VERSION ""

NS_ :

BS_:

BU_: HCM_FD IPMA_ADAS PSCM_FD ABS_ESC TCCM_FD TCM_DSL_FD PCM_HEV_FD PCM_FD ECM_Diesel GENERIC_GWMWakeup GWM_ECG _delete TSTR

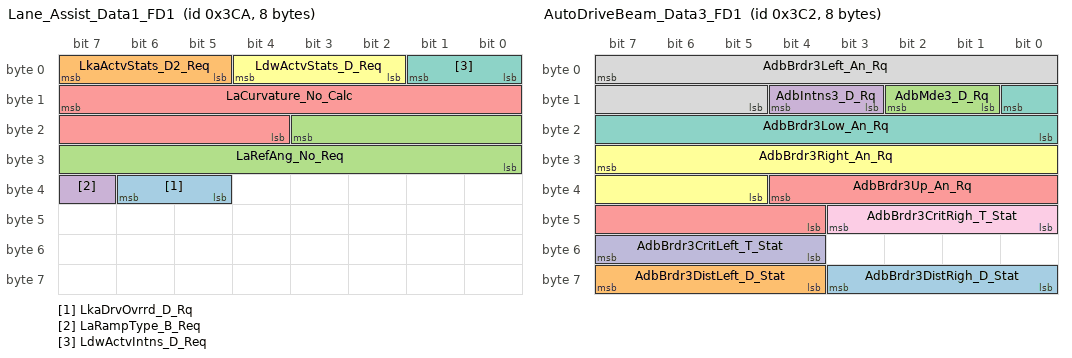
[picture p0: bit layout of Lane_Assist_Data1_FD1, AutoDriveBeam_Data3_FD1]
BO_ 970 Lane_Assist_Data1_FD1: 8 GWM_ECG
 SG_ LkaDrvOvrrd_D_Rq : 38|2@0+ (1,0) [0|3] "SED"  PSCM_FD
 SG_ LkaActvStats_D2_Req : 7|3@0+ (1,0) [0|7] "SED"  PSCM_FD
 SG_ LaRefAng_No_Req : 19|12@0+ (0.05,-102.4) [-102.4|102.3] "mrad"  PSCM_FD
 SG_ LaRampType_B_Req : 39|1@0+ (1,0) [0|1] "SED"  PSCM_FD
 SG_ LaCurvature_No_Calc : 15|12@0+ (5E-006,-0.01024) [-0.01024|0.01023] "1/m"  PSCM_FD
 SG_ LdwActvStats_D_Req : 4|3@0+ (1,0) [0|7] "SED"  PSCM_FD
 SG_ LdwActvIntns_D_Req : 1|2@0+ (1,0) [0|3] "SED"  PSCM_FD

BO_ 962 AutoDriveBeam_Data3_FD1: 8 IPMA_ADAS
 SG_ AdbBrdr3DistRigh_D_Stat : 59|4@0+ (1,0) [0|15] "SED"  HCM_FD
 SG_ AdbBrdr3DistLeft_D_Stat : 63|4@0+ (1,0) [0|15] "SED"  HCM_FD
 SG_ AdbMde3_D_Rq : 10|2@0+ (1,0) [0|3] "SED"  HCM_FD
 SG_ AdbIntns3_D_Rq : 12|2@0+ (1,0) [0|3] "SED"  HCM_FD
 SG_ AdbBrdr3Up_An_Rq : 36|9@0+ (0.02,-8) [-8|2.18] "degrees"  HCM_FD
 SG_ AdbBrdr3Right_An_Rq : 31|11@0+ (0.02,-20) [-20|20.9] "degrees"  HCM_FD
 SG_ AdbBrdr3Low_An_Rq : 8|9@0+ (0.02,-8) [-8|2.18] "degrees"  HCM_FD
 SG_ AdbBrdr3Left_An_Rq : 7|11@0+ (0.02,-20) [-20|20.9] "degrees"  HCM_FD
 SG_ AdbBrdr3CritRigh_T_Stat : 43|4@0+ (100,0) [0|1500] "millisecond"  HCM_FD
 SG_ AdbBrdr3CritLeft_T_Stat : 55|4@0+ (100,0) [0|1500] "millisecond"  HCM_FD

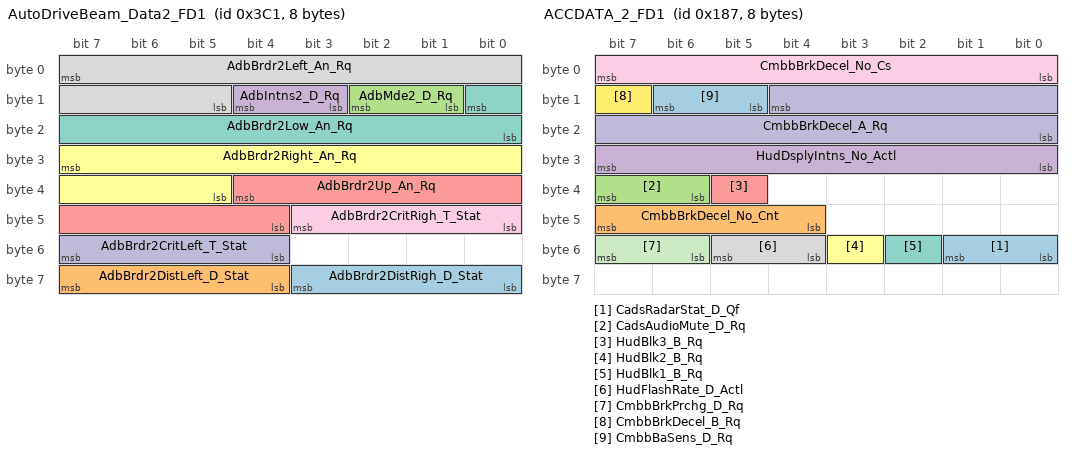
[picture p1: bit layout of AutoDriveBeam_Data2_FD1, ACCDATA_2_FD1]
BO_ 961 AutoDriveBeam_Data2_FD1: 8 IPMA_ADAS
 SG_ AdbBrdr2DistRigh_D_Stat : 59|4@0+ (1,0) [0|15] "SED"  HCM_FD
 SG_ AdbBrdr2DistLeft_D_Stat : 63|4@0+ (1,0) [0|15] "SED"  HCM_FD
 SG_ AdbMde2_D_Rq : 10|2@0+ (1,0) [0|3] "SED"  HCM_FD
 SG_ AdbIntns2_D_Rq : 12|2@0+ (1,0) [0|3] "SED"  HCM_FD
 SG_ AdbBrdr2Up_An_Rq : 36|9@0+ (0.02,-8) [-8|2.18] "degrees"  HCM_FD
 SG_ AdbBrdr2Right_An_Rq : 31|11@0+ (0.02,-20) [-20|20.9] "degrees"  HCM_FD
 SG_ AdbBrdr2Low_An_Rq : 8|9@0+ (0.02,-8) [-8|2.18] "degrees"  HCM_FD
 SG_ AdbBrdr2Left_An_Rq : 7|11@0+ (0.02,-20) [-20|20.9] "degrees"  HCM_FD
 SG_ AdbBrdr2CritRigh_T_Stat : 43|4@0+ (100,0) [0|1500] "millisecond"  HCM_FD
 SG_ AdbBrdr2CritLeft_T_Stat : 55|4@0+ (100,0) [0|1500] "millisecond"  HCM_FD

BO_ 394 ACCDATA_3_FD1: 8 IPMA_ADAS
 SG_ AccTrgDist2_D_Dsply : 27|4@0+ (1,0) [0|15] "SED" Vector__XXX
 SG_ AccStopRes_B_Dsply : 54|1@0+ (1,0) [0|1] "SED" Vector__XXX
 SG_ TjaWarn_D_Rq : 50|3@0+ (1,0) [0|7] "SED" Vector__XXX
 SG_ Tja_D_Stat : 44|3@0+ (1,0) [0|7] "SED" Vector__XXX
 SG_ TjaMsgTxt_D_Dsply : 53|3@0+ (1,0) [0|7] "SED" Vector__XXX
 SG_ IaccLamp_D_Rq : 46|2@0+ (1,0) [0|3] "SED" Vector__XXX
 SG_ AccMsgTxt_D2_Rq : 31|4@0+ (1,0) [0|15] "SED" Vector__XXX
 SG_ FcwDeny_B_Dsply : 10|1@0+ (1,0) [0|1] "SED" Vector__XXX
 SG_ FdaWarn_B_Rq : 21|1@0+ (1,0) [0|1] "SED" Vector__XXX
 SG_ FcwMemStat_B_Actl : 13|1@0+ (1,0) [0|1] "SED" Vector__XXX
 SG_ AccTGap_B_Dsply : 35|1@0+ (1,0) [0|1] "SED" Vector__XXX
 SG_ CadsAlignIncplt_B_Actl : 11|1@0+ (1,0) [0|1] "SED" Vector__XXX
 SG_ AccLowVMde_B_Dsply : 16|1@0+ (1,0) [0|1] "SED" Vector__XXX
 SG_ AccFllwMde_B_Dsply : 17|1@0+ (1,0) [0|1] "SED" Vector__XXX
 SG_ CadsRadrBlck_B_Actl : 22|1@0+ (1,0) [0|1] "SED" Vector__XXX
 SG_ FdaStat_D_Dsply : 3|3@0+ (1,0) [0|7] "SED" Vector__XXX
 SG_ FdaDeny_B_Dsply : 4|1@0+ (1,0) [0|1] "SED" Vector__XXX
 SG_ CadsChime_B_Rq : 55|1@0+ (1,0) [0|1] "SED" Vector__XXX
 SG_ CmbbPostEvnt_B_Dsply : 15|1@0+ (1,0) [0|1] "SED" Vector__XXX
 SG_ FcwCmbbSrvcRqd_B_Rq : 12|1@0+ (1,0) [0|1] "SED" Vector__XXX
 SG_ AccStopMde_B_Dsply : 0|1@0+ (1,0) [0|1] "SED" Vector__XXX
 SG_ CadsCamraBlck_B_Actl : 23|1@0+ (1,0) [0|1] "SED" Vector__XXX
 SG_ FcwMemSens_D_Actl : 20|2@0+ (1,0) [0|3] "SED" Vector__XXX
 SG_ FcwMemDfaltOn_B_Actl : 18|1@0+ (1,0) [0|1] "SED" Vector__XXX
 SG_ AccSrvcRqd_B_Rq : 14|1@0+ (1,0) [0|1] "SED" Vector__XXX
 SG_ FcwMsgTxt_D_Rq : 7|3@0+ (1,0) [0|7] "SED" Vector__XXX
 SG_ AccWarn_D_Dsply : 39|2@0+ (1,0) [0|3] "SED" Vector__XXX
 SG_ FcwVisblWarn_B_Rq : 47|1@0+ (1,0) [0|1] "SED" Vector__XXX
 SG_ FcwAudioWarn_B_Rq : 8|1@0+ (1,0) [0|1] "SED" Vector__XXX
 SG_ FcwMemAudioOn_B_Actl : 9|1@0+ (1,0) [0|1] "SED" Vector__XXX
 SG_ AccTGap_D_Dsply : 34|3@0+ (1,0) [0|7] "SED" Vector__XXX
 SG_ AccMemEnbl_B_RqDrv : 36|1@0+ (1,0) [0|1] "SED" Vector__XXX
 SG_ FdaMem_B_Stat : 37|1@0+ (1,0) [0|1] "SED" Vector__XXX

BO_ 391 ACCDATA_2_FD1: 8 GWM_ECG
 SG_ CadsRadarStat_D_Qf : 49|2@0+ (1,0) [0|3] "SED" Vector__XXX
 SG_ CmbbBrkDecel_No_Cnt : 47|4@0+ (1,0) [0|15] "Unitless"  ABS_ESC
 SG_ CadsAudioMute_D_Rq : 39|2@0+ (1,0) [0|3] "SED" Vector__XXX
 SG_ HudDsplyIntns_No_Actl : 31|8@0+ (0.5,0) [0|100] "%" Vector__XXX
 SG_ HudBlk3_B_Rq : 37|1@0+ (1,0) [0|1] "SED" Vector__XXX
 SG_ HudBlk2_B_Rq : 51|1@0+ (1,0) [0|1] "SED" Vector__XXX
 SG_ HudBlk1_B_Rq : 50|1@0+ (1,0) [0|1] "SED" Vector__XXX
 SG_ HudFlashRate_D_Actl : 53|2@0+ (1,0) [0|3] "SED" Vector__XXX
 SG_ CmbbBrkDecel_No_Cs : 7|8@0+ (1,0) [0|255] "Unitless"  ABS_ESC
 SG_ CmbbBrkDecel_A_Rq : 12|13@0+ (0.0039,-20) [-20|11.9449] "m/s^2"  ABS_ESC
 SG_ CmbbBrkPrchg_D_Rq : 55|2@0+ (1,0) [0|3] "SED"  ABS_ESC
 SG_ CmbbBrkDecel_B_Rq : 15|1@0+ (1,0) [0|1] "SED"  ABS_ESC
 SG_ CmbbBaSens_D_Rq : 14|2@0+ (1,0) [0|3] "SED"  ABS_ESC

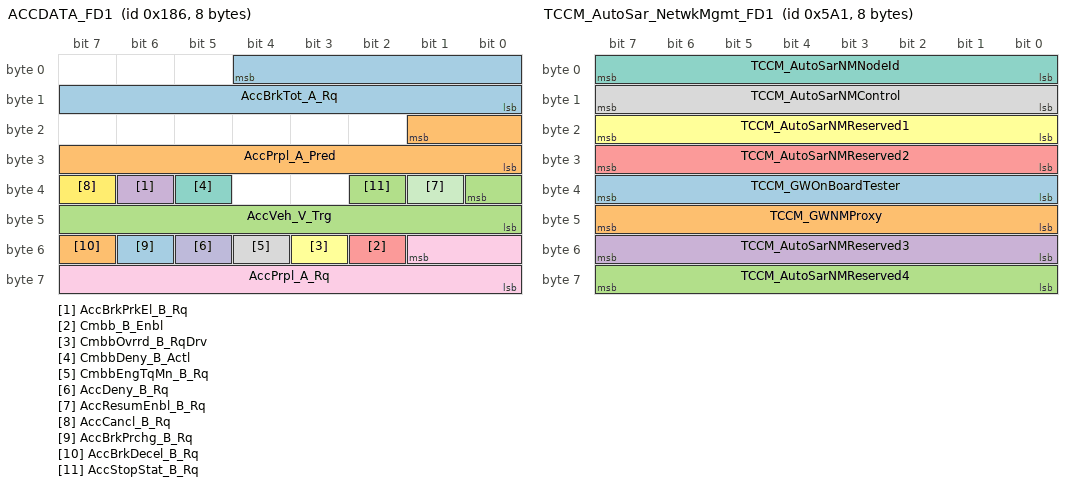
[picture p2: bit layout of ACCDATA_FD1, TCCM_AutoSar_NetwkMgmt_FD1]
BO_ 390 ACCDATA_FD1: 8 GWM_ECG
 SG_ AccBrkTot_A_Rq : 4|13@0+ (0.0039,-20) [-20|11.9449] "m/s^2"  ABS_ESC
 SG_ AccPrpl_A_Pred : 17|10@0+ (0.01,-5) [-5|5.23] "m/s^2"  ECM_Diesel,PCM_FD,PCM_HEV_FD
 SG_ AccVeh_V_Trg : 32|9@0+ (0.5,0) [0|255.5] "kph"  ECM_Diesel,PCM_FD,PCM_HEV_FD,TCM_DSL_FD
 SG_ AccBrkPrkEl_B_Rq : 38|1@0+ (1,0) [0|1] "SED"  ABS_ESC
 SG_ Cmbb_B_Enbl : 50|1@0+ (1,0) [0|1] "SED"  GWM_ECG
 SG_ CmbbOvrrd_B_RqDrv : 51|1@0+ (1,0) [0|1] "SED"  GWM_ECG
 SG_ CmbbDeny_B_Actl : 37|1@0+ (1,0) [0|1] "SED"  GWM_ECG,ABS_ESC
 SG_ CmbbEngTqMn_B_Rq : 52|1@0+ (1,0) [0|1] "SED"  ECM_Diesel,PCM_FD,PCM_HEV_FD,GWM_ECG
 SG_ AccPrpl_A_Rq : 49|10@0+ (0.01,-5) [-5|5.23] "m/s^2"  ECM_Diesel,PCM_FD,PCM_HEV_FD
 SG_ AccDeny_B_Rq : 53|1@0+ (1,0) [0|1] "SED"  ECM_Diesel,PCM_FD,PCM_HEV_FD
 SG_ AccResumEnbl_B_Rq : 33|1@0+ (1,0) [0|1] "SED"  ECM_Diesel,PCM_FD,PCM_HEV_FD
 SG_ AccCancl_B_Rq : 39|1@0+ (1,0) [0|1] "SED"  ABS_ESC,ECM_Diesel,PCM_FD,PCM_HEV_FD
 SG_ AccBrkPrchg_B_Rq : 54|1@0+ (1,0) [0|1] "SED"  ABS_ESC
 SG_ AccBrkDecel_B_Rq : 55|1@0+ (1,0) [0|1] "SED"  ABS_ESC
 SG_ AccStopStat_B_Rq : 34|1@0+ (1,0) [0|1] "SED"  ECM_Diesel,PCM_FD,PCM_HEV_FD,ABS_ESC

BO_ 1441 TCCM_AutoSar_NetwkMgmt_FD1: 8 TCCM_FD
 SG_ TCCM_GWOnBoardTester : 39|8@0+ (1,0) [0|255] "unitless"  GWM_ECG
 SG_ TCCM_GWNMProxy : 47|8@0+ (1,0) [0|255] "unitless"  GWM_ECG
 SG_ TCCM_AutoSarNMReserved4 : 63|8@0+ (1,0) [0|255] "unitless"  GWM_ECG
 SG_ TCCM_AutoSarNMReserved3 : 55|8@0+ (1,0) [0|255] "unitless"  GWM_ECG
 SG_ TCCM_AutoSarNMReserved2 : 31|8@0+ (1,0) [0|255] "unitless"  GWM_ECG
 SG_ TCCM_AutoSarNMReserved1 : 23|8@0+ (1,0) [0|255] "unitless"  GWM_ECG
 SG_ TCCM_AutoSarNMNodeId : 7|8@0+ (1,0) [0|255] "unitless"  GWM_ECG
 SG_ TCCM_AutoSarNMControl : 15|8@0+ (1,0) [0|255] "unitless"  GWM_ECG

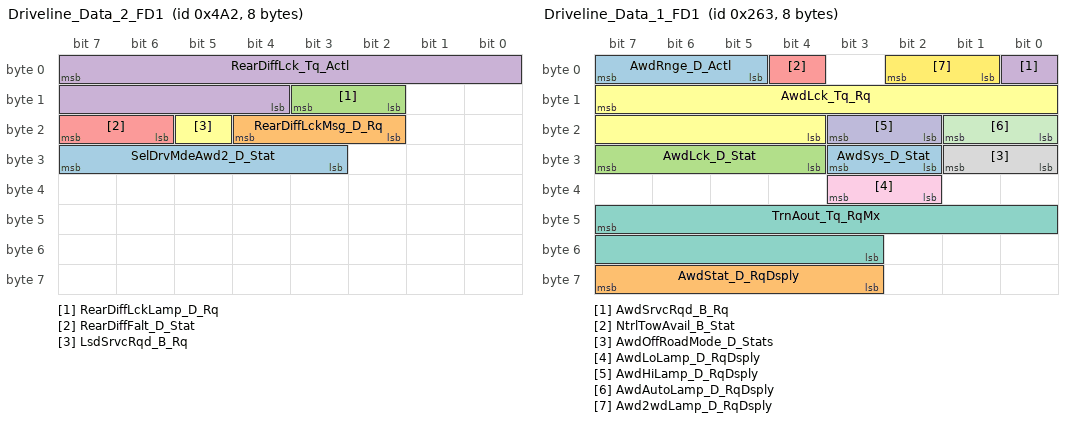
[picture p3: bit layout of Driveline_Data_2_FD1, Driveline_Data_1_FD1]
BO_ 1186 Driveline_Data_2_FD1: 8 TCCM_FD
 SG_ SelDrvMdeAwd2_D_Stat : 31|5@0+ (1,0) [0|31] "SED"  ABS_ESC,GWM_ECG
 SG_ RearDiffLckMsg_D_Rq : 20|3@0+ (1,0) [0|7] "SED"  GWM_ECG
 SG_ RearDiffLckLamp_D_Rq : 11|2@0+ (1,0) [0|3] "SED"  ABS_ESC,IPMA_ADAS,GWM_ECG
 SG_ RearDiffLck_Tq_Actl : 7|12@0+ (1,0) [0|4093] "Nm"  ABS_ESC,ECM_Diesel,PCM_FD,PCM_HEV_FD,GWM_ECG
 SG_ RearDiffFalt_D_Stat : 23|2@0+ (1,0) [0|3] "SED"  ABS_ESC,GWM_ECG
 SG_ LsdSrvcRqd_B_Rq : 21|1@0+ (1,0) [0|1] "SED"  GWM_ECG

BO_ 611 Driveline_Data_1_FD1: 8 TCCM_FD
 SG_ AwdSys_D_Stat : 27|2@0+ (1,0) [0|3] "SED"  GWM_ECG,ECM_Diesel,PCM_FD,PCM_HEV_FD
 SG_ AwdStat_D_RqDsply : 63|5@0+ (1,0) [0|31] "SED"  TCM_DSL_FD,ABS_ESC,GWM_ECG
 SG_ AwdLck_D_Stat : 31|4@0+ (1,0) [0|15] "SED"  GWM_ECG,ABS_ESC
 SG_ AwdSrvcRqd_B_Rq : 0|1@0+ (1,0) [0|1] "SED"  GWM_ECG,PCM_FD,PCM_HEV_FD,TCM_DSL_FD,ABS_ESC
 SG_ NtrlTowAvail_B_Stat : 4|1@0+ (1,0) [0|1] "SED"  GWM_ECG
 SG_ AwdLck_Tq_Rq : 15|12@0+ (1,0) [0|4093] "Nm"  ABS_ESC,GWM_ECG
 SG_ TrnAout_Tq_RqMx : 47|13@0+ (1,-1250) [-1250|6941] "Nm"  GWM_ECG,ECM_Diesel,PCM_FD,PCM_HEV_FD
 SG_ AwdOffRoadMode_D_Stats : 25|2@0+ (1,0) [0|3] "SED"  IPMA_ADAS,GWM_ECG
 SG_ AwdLoLamp_D_RqDsply : 35|2@0+ (1,0) [0|3] "SED"  GWM_ECG
 SG_ AwdHiLamp_D_RqDsply : 19|2@0+ (1,0) [0|3] "SED"  ABS_ESC,GWM_ECG
 SG_ AwdAutoLamp_D_RqDsply : 17|2@0+ (1,0) [0|3] "SED"  ABS_ESC,GWM_ECG
 SG_ Awd2wdLamp_D_RqDsply : 2|2@0+ (1,0) [0|3] "SED"  GWM_ECG
 SG_ AwdRnge_D_Actl : 7|3@0+ (1,0) [0|7] "SED"  GWM_ECG,ECM_Diesel,PCM_FD,PCM_HEV_FD,TCM_DSL_FD,ABS_ESC

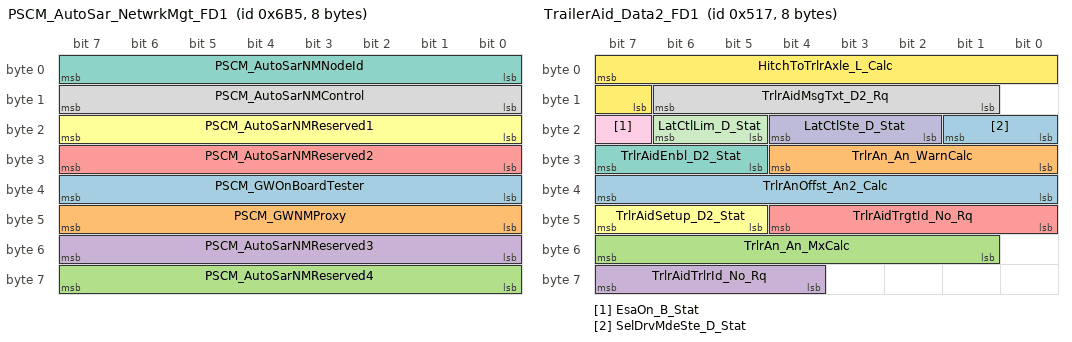
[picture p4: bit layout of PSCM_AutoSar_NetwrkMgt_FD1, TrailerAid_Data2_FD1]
BO_ 1717 PSCM_AutoSar_NetwrkMgt_FD1: 8 PSCM_FD
 SG_ PSCM_GWOnBoardTester : 39|8@0+ (1,0) [0|255] "unitless"  ABS_ESC
 SG_ PSCM_GWNMProxy : 47|8@0+ (1,0) [0|255] "unitless"  ABS_ESC
 SG_ PSCM_AutoSarNMReserved4 : 63|8@0+ (1,0) [0|255] "unitless"  ABS_ESC
 SG_ PSCM_AutoSarNMReserved3 : 55|8@0+ (1,0) [0|255] "unitless"  ABS_ESC
 SG_ PSCM_AutoSarNMReserved2 : 31|8@0+ (1,0) [0|255] "unitless"  ABS_ESC
 SG_ PSCM_AutoSarNMReserved1 : 23|8@0+ (1,0) [0|255] "unitless"  ABS_ESC
 SG_ PSCM_AutoSarNMNodeId : 7|8@0+ (1,0) [0|255] "unitless"  ABS_ESC
 SG_ PSCM_AutoSarNMControl : 15|8@0+ (1,0) [0|255] "unitless"  ABS_ESC

BO_ 1303 TrailerAid_Data2_FD1: 8 PSCM_FD
 SG_ TrlrAnOffst_An2_Calc : 39|8@0+ (0.5,-64) [-64|63.5] "degrees"  IPMA_ADAS
 SG_ TrlrAn_An_WarnCalc : 28|5@0+ (1,0) [0|31] "degrees"  IPMA_ADAS
 SG_ TrlrAn_An_MxCalc : 55|7@0+ (1,0) [0|127] "degrees"  IPMA_ADAS
 SG_ TrlrAidTrlrId_No_Rq : 63|4@0+ (1,0) [0|15] "unitless"  GWM_ECG
 SG_ TrlrAidTrgtId_No_Rq : 44|5@0+ (1,0) [0|31] "unitless"  IPMA_ADAS
 SG_ TrlrAidSetup_D2_Stat : 47|3@0+ (1,0) [0|7] "SED"  IPMA_ADAS
 SG_ TrlrAidEnbl_D2_Stat : 31|3@0+ (1,0) [0|7] "SED"  ECM_Diesel,IPMA_ADAS,GWM_ECG,PCM_FD
 SG_ TrlrAidMsgTxt_D2_Rq : 14|6@0+ (1,0) [0|63] "SED"  ABS_ESC,IPMA_ADAS,GWM_ECG
 SG_ EsaOn_B_Stat : 23|1@0+ (1,0) [0|1] "SED"  GWM_ECG
 SG_ LatCtlSte_D_Stat : 20|3@0+ (1,0) [0|7] "SED"  IPMA_ADAS
 SG_ LatCtlLim_D_Stat : 22|2@0+ (1,0) [0|3] "SED"  IPMA_ADAS
 SG_ HitchToTrlrAxle_L_Calc : 7|9@0+ (0.0254,0) [0|12.9794] "meter"  IPMA_ADAS
 SG_ SelDrvMdeSte_D_Stat : 17|2@0+ (1,0) [0|3] "SED"  ABS_ESC

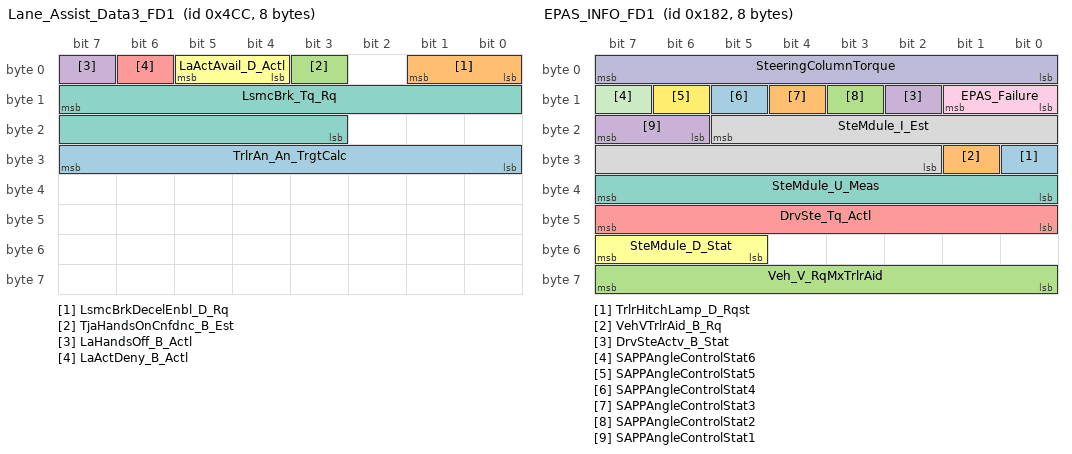
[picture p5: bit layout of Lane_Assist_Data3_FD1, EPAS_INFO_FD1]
BO_ 1228 Lane_Assist_Data3_FD1: 8 PSCM_FD
 SG_ TrlrAn_An_TrgtCalc : 31|8@0+ (1,-128) [-128|127] "degrees"  IPMA_ADAS
 SG_ LsmcBrkDecelEnbl_D_Rq : 1|2@0+ (1,0) [0|3] "SED"  ABS_ESC
 SG_ TjaHandsOnCnfdnc_B_Est : 3|1@0+ (1,0) [0|1] "SED"  IPMA_ADAS
 SG_ LaHandsOff_B_Actl : 7|1@0+ (1,0) [0|1] "SED"  IPMA_ADAS,GWM_ECG
 SG_ LaActDeny_B_Actl : 6|1@0+ (1,0) [0|1] "SED"  IPMA_ADAS,GWM_ECG
 SG_ LaActAvail_D_Actl : 5|2@0+ (1,0) [0|3] "SED"  IPMA_ADAS,GWM_ECG
 SG_ LsmcBrk_Tq_Rq : 15|13@0+ (4,0) [0|32764] "Nm"  ABS_ESC

BO_ 386 EPAS_INFO_FD1: 8 PSCM_FD
 SG_ TrlrHitchLamp_D_Rqst : 24|1@0+ (1,0) [0|1] "SED"  IPMA_ADAS,GWM_ECG
 SG_ VehVTrlrAid_B_Rq : 25|1@0+ (1,0) [0|1] "SED"  ECM_Diesel,PCM_FD
 SG_ Veh_V_RqMxTrlrAid : 63|8@0+ (0.1,0) [0|25.5] "km/h"  ECM_Diesel,PCM_FD
 SG_ DrvSteActv_B_Stat : 10|1@0+ (1,0) [0|1] "SED"  ABS_ESC
 SG_ DrvSte_Tq_Actl : 47|8@0+ (0.0625,-8) [-8|7.8125] "Nm"  ABS_ESC
 SG_ SteMdule_D_Stat : 55|3@0+ (1,0) [0|7] "SED"  GWM_ECG
 SG_ SteMdule_U_Meas : 39|8@0+ (0.05,6) [6|18.7] "Volts"  GWM_ECG
 SG_ SteMdule_I_Est : 21|12@0+ (0.05,-64) [-64|140.7] "Amps"  GWM_ECG
 SG_ EPAS_Failure : 9|2@0+ (1,0) [0|3] "SED"  IPMA_ADAS,GWM_ECG
 SG_ SteeringColumnTorque : 7|8@0+ (0.0625,-8) [-8|7.8125] "Nm"  ABS_ESC,IPMA_ADAS
 SG_ SAPPAngleControlStat6 : 15|1@0+ (1,0) [0|1] "SED"  IPMA_ADAS
 SG_ SAPPAngleControlStat5 : 14|1@0+ (1,0) [0|1] "SED"  IPMA_ADAS
 SG_ SAPPAngleControlStat4 : 13|1@0+ (1,0) [0|1] "SED"  IPMA_ADAS
 SG_ SAPPAngleControlStat3 : 12|1@0+ (1,0) [0|1] "SED"  IPMA_ADAS
 SG_ SAPPAngleControlStat2 : 11|1@0+ (1,0) [0|1] "SED"  IPMA_ADAS
 SG_ SAPPAngleControlStat1 : 23|2@0+ (1,0) [0|3] "SED"  IPMA_ADAS

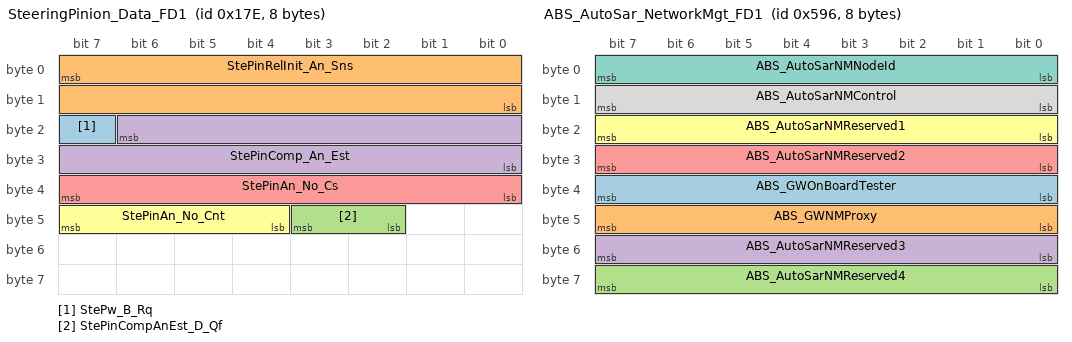
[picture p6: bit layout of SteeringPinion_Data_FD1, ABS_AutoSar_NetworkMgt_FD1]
BO_ 382 SteeringPinion_Data_FD1: 8 PSCM_FD
 SG_ StePw_B_Rq : 23|1@0+ (1,0) [0|1] "SED"  GWM_ECG,ECM_Diesel,PCM_FD
 SG_ StePinRelInit_An_Sns : 7|16@0+ (0.1,-3200) [-3200|3353.3] "degrees"  IPMA_ADAS,GWM_ECG,ECM_Diesel,PCM_FD,PCM_HEV_FD,ABS_ESC,TCCM_FD
 SG_ StePinCompAnEst_D_Qf : 43|2@0+ (1,0) [0|3] "SED"  HCM_FD,IPMA_ADAS,TCM_DSL_FD,GWM_ECG,ECM_Diesel,PCM_FD,PCM_HEV_FD,ABS_ESC,TCCM_FD
 SG_ StePinComp_An_Est : 22|15@0+ (0.1,-1600) [-1600|1676.7] "degrees"  HCM_FD,IPMA_ADAS,TCM_DSL_FD,GWM_ECG,ECM_Diesel,PCM_FD,PCM_HEV_FD,ABS_ESC,TCCM_FD
 SG_ StePinAn_No_Cs : 39|8@0+ (1,0) [0|255] "Unitless"  ABS_ESC,TCCM_FD,GWM_ECG
 SG_ StePinAn_No_Cnt : 47|4@0+ (1,0) [0|15] "unitless"  TCCM_FD,GWM_ECG,ABS_ESC

BO_ 1430 ABS_AutoSar_NetworkMgt_FD1: 8 ABS_ESC
 SG_ ABS_GWOnBoardTester : 39|8@0+ (1,0) [0|255] "unitless"  GWM_ECG
 SG_ ABS_GWNMProxy : 47|8@0+ (1,0) [0|255] "unitless"  GWM_ECG
 SG_ ABS_AutoSarNMReserved4 : 63|8@0+ (1,0) [0|255] "unitless"  GWM_ECG
 SG_ ABS_AutoSarNMReserved3 : 55|8@0+ (1,0) [0|255] "unitless"  GWM_ECG
 SG_ ABS_AutoSarNMReserved2 : 31|8@0+ (1,0) [0|255] "unitless"  GWM_ECG
 SG_ ABS_AutoSarNMReserved1 : 23|8@0+ (1,0) [0|255] "unitless"  GWM_ECG
 SG_ ABS_AutoSarNMNodeId : 7|8@0+ (1,0) [0|255] "unitless"  GWM_ECG
 SG_ ABS_AutoSarNMControl : 15|8@0+ (1,0) [0|255] "unitless"  GWM_ECG

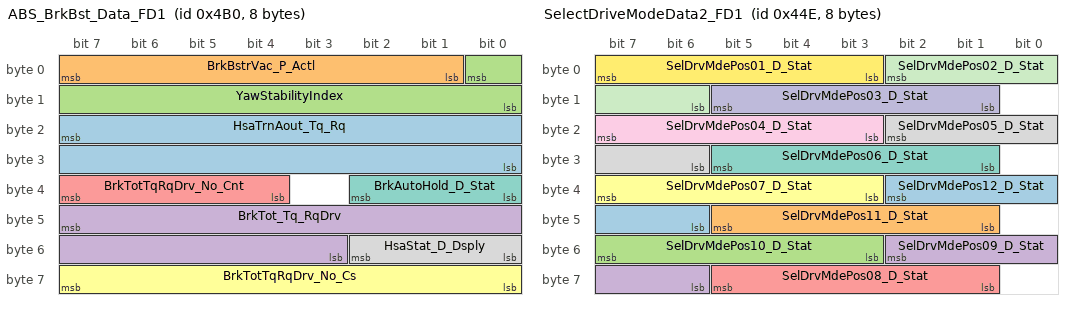
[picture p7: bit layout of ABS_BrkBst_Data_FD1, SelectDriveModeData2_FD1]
BO_ 1200 ABS_BrkBst_Data_FD1: 8 ABS_ESC
 SG_ HsaTrnAout_Tq_Rq : 23|16@0+ (4,-131072) [-131072|131060] "Nm"  GWM_ECG
 SG_ BrkBstrVac_P_Actl : 7|7@0+ (8,0) [0|1008] "Millibar"  ECM_Diesel,PCM_FD,PCM_HEV_FD,GWM_ECG
 SG_ YawStabilityIndex : 0|9@0+ (1,-256) [-256|255] "%"  IPMA_ADAS,PSCM_FD,GWM_ECG
 SG_ BrkTot_Tq_RqDrv : 47|13@0+ (4,0) [0|32760] "Nm"  IPMA_ADAS,ECM_Diesel,PCM_FD,PCM_HEV_FD,GWM_ECG
 SG_ BrkTotTqRqDrv_No_Cnt : 39|4@0+ (1,0) [0|15] "unitless"  ECM_Diesel,PCM_FD,PCM_HEV_FD,GWM_ECG
 SG_ BrkTotTqRqDrv_No_Cs : 63|8@0+ (1,0) [0|255] "unitless"  ECM_Diesel,PCM_FD,PCM_HEV_FD,GWM_ECG
 SG_ BrkAutoHold_D_Stat : 34|3@0+ (1,0) [0|7] "SED"  ECM_Diesel,PCM_FD,PCM_HEV_FD,GWM_ECG,IPMA_ADAS
 SG_ HsaStat_D_Dsply : 50|3@0+ (1,0) [0|7] "SED"  GWM_ECG

BO_ 1102 SelectDriveModeData2_FD1: 8 ABS_ESC
 SG_ SelDrvMdePos12_D_Stat : 34|5@0+ (1,0) [0|31] "SED"  GWM_ECG
 SG_ SelDrvMdePos11_D_Stat : 45|5@0+ (1,0) [0|31] "SED"  GWM_ECG
 SG_ SelDrvMdePos10_D_Stat : 55|5@0+ (1,0) [0|31] "SED"  GWM_ECG
 SG_ SelDrvMdePos09_D_Stat : 50|5@0+ (1,0) [0|31] "SED"  GWM_ECG
 SG_ SelDrvMdePos08_D_Stat : 61|5@0+ (1,0) [0|31] "SED"  GWM_ECG
 SG_ SelDrvMdePos07_D_Stat : 39|5@0+ (1,0) [0|31] "SED"  GWM_ECG
 SG_ SelDrvMdePos06_D_Stat : 29|5@0+ (1,0) [0|31] "SED"  GWM_ECG
 SG_ SelDrvMdePos05_D_Stat : 18|5@0+ (1,0) [0|31] "SED"  GWM_ECG
 SG_ SelDrvMdePos04_D_Stat : 23|5@0+ (1,0) [0|31] "SED"  GWM_ECG
 SG_ SelDrvMdePos03_D_Stat : 13|5@0+ (1,0) [0|31] "SED"  GWM_ECG
 SG_ SelDrvMdePos02_D_Stat : 2|5@0+ (1,0) [0|31] "SED"  GWM_ECG
 SG_ SelDrvMdePos01_D_Stat : 7|5@0+ (1,0) [0|31] "SED"  GWM_ECG

BO_ 1056 SelectDriveModeData_FD1: 8 ABS_ESC
 SG_ SelDrvMdePos12_B_Avail : 54|1@0+ (1,0) [0|1] "SED"  GWM_ECG
 SG_ SelDrvMdePos11_B_Avail : 55|1@0+ (1,0) [0|1] "SED"  GWM_ECG
 SG_ SelDrvMdePos10_B_Avail : 40|1@0+ (1,0) [0|1] "SED"  GWM_ECG
 SG_ SelDrvMdePos09_B_Avail : 41|1@0+ (1,0) [0|1] "SED"  GWM_ECG
 SG_ SelDrvMdePos08_B_Avail : 42|1@0+ (1,0) [0|1] "SED"  GWM_ECG
 SG_ SelDrvMdePos07_B_Avail : 43|1@0+ (1,0) [0|1] "SED"  GWM_ECG
 SG_ SelDrvMdePos06_B_Avail : 44|1@0+ (1,0) [0|1] "SED"  GWM_ECG
 SG_ SelDrvMdePos05_B_Avail : 45|1@0+ (1,0) [0|1] "SED"  GWM_ECG
 SG_ SelDrvMdePos04_B_Avail : 46|1@0+ (1,0) [0|1] "SED"  GWM_ECG
 SG_ SelDrvMdePos03_B_Avail : 47|1@0+ (1,0) [0|1] "SED"  GWM_ECG
 SG_ SelDrvMdePos02_B_Avail : 32|1@0+ (1,0) [0|1] "SED"  GWM_ECG
 SG_ SelDrvMdePos01_B_Avail : 24|1@0+ (1,0) [0|1] "SED"  GWM_ECG
 SG_ ActvDrvMde_D2_Stat : 53|5@0+ (1,0) [0|31] "SED"  IPMA_ADAS,GWM_ECG
 SG_ SelDrvMde_D2_Rq : 63|5@0+ (1,0) [0|31] "SED"  GWM_ECG
 SG_ SelDrvMdePt_D_Rq : 31|5@0+ (1,0) [0|31] "SED"  ECM_Diesel,PCM_FD,PCM_HEV_FD,GWM_ECG
 SG_ SelDrvMdeMsgTxt_D_Rq : 19|4@0+ (1,0) [0|0] "SED"  GWM_ECG
 SG_ SelDrvMde_D_Stat : 26|2@0+ (1,0) [0|3] "SED"  GWM_ECG
 SG_ AwdMde_D_RqBrk : 35|3@0+ (1,0) [0|7] "SED"  GWM_ECG

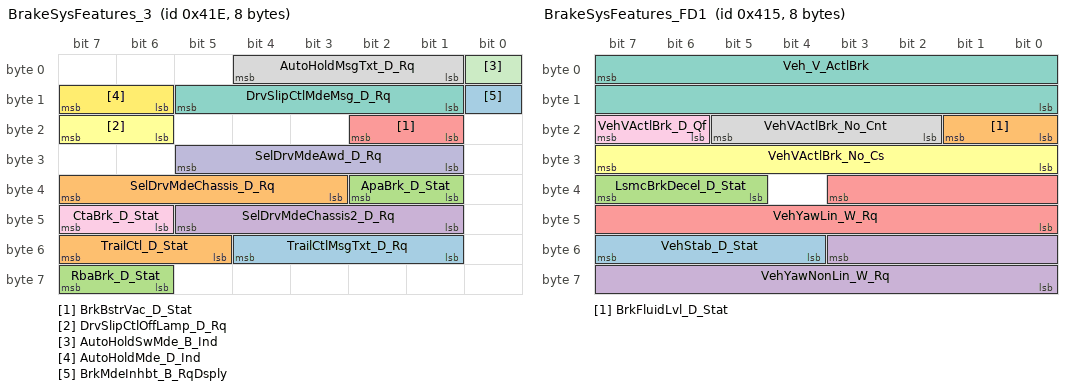
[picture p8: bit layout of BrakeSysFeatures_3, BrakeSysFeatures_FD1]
BO_ 1054 BrakeSysFeatures_3: 8 ABS_ESC
 SG_ TrailCtlMsgTxt_D_Rq : 52|4@0+ (1,0) [0|15] "SED"  GWM_ECG
 SG_ TrailCtl_D_Stat : 55|3@0+ (1,0) [0|7] "SED"  PCM_FD,GWM_ECG,TCCM_FD
 SG_ RbaBrk_D_Stat : 63|2@0+ (1,0) [0|3] "SED"  IPMA_ADAS,GWM_ECG
 SG_ SelDrvMdeChassis2_D_Rq : 45|5@0+ (1,0) [0|31] "SED"  PSCM_FD,GWM_ECG
 SG_ BrkBstrVac_D_Stat : 18|2@0+ (1,0) [0|3] "SED"  ECM_Diesel,PCM_FD,PCM_HEV_FD,GWM_ECG
 SG_ DrvSlipCtlOffLamp_D_Rq : 23|2@0+ (1,0) [0|3] "SED"  GWM_ECG
 SG_ DrvSlipCtlMdeMsg_D_Rq : 13|5@0+ (1,0) [0|31] "SED"  GWM_ECG
 SG_ AutoHoldMsgTxt_D_Rq : 4|4@0+ (1,0) [0|15] "SED"  GWM_ECG
 SG_ CtaBrk_D_Stat : 47|2@0+ (1,0) [0|3] "SED"  GWM_ECG
 SG_ SelDrvMdeAwd_D_Rq : 29|5@0+ (1,0) [0|31] "SED"  TCCM_FD,GWM_ECG
 SG_ AutoHoldSwMde_B_Ind : 0|1@0+ (1,0) [0|1] "SED"  GWM_ECG
 SG_ AutoHoldMde_D_Ind : 15|2@0+ (1,0) [0|3] "SED"  GWM_ECG
 SG_ BrkMdeInhbt_B_RqDsply : 8|1@0+ (1,0) [0|1] "SED"  GWM_ECG
 SG_ SelDrvMdeChassis_D_Rq : 39|5@0+ (1,0) [0|31] "SED"  GWM_ECG
 SG_ ApaBrk_D_Stat : 34|2@0+ (1,0) [0|3] "SED"  ECM_Diesel,IPMA_ADAS,PCM_FD,PCM_HEV_FD,GWM_ECG

BO_ 1046 BrakeSysFeatures_2: 8 ABS_ESC
 SG_ RearDiffElckrOpen_B_Rq : 40|1@0+ (1,0) [0|1] "SE"  GWM_ECG,TCCM_FD
 SG_ HsaMde_D_Mem : 33|2@0+ (1,0) [0|3] "SED"  GWM_ECG
 SG_ BrkBstrVac_B_Rq : 27|1@0+ (1,0) [0|1] "Discrete"  ECM_Diesel,PCM_FD,PCM_HEV_FD,GWM_ECG
 SG_ HdcMde_D_Actl : 31|3@0+ (1,0) [0|7] "SED"  GWM_ECG
 SG_ RearDiffLck_Tq2_RqMx : 51|12@0+ (4,0) [0|16376] "Nm"  GWM_ECG
 SG_ TRLR_SWAY_EVNT_IN_PROG : 25|1@0+ (1,0) [0|1] "SED"  GWM_ECG
 SG_ TRLR_SWAY_CONFIG_STAT : 26|1@0+ (1,0) [0|1] "SED"  GWM_ECG
 SG_ TCMode : 15|1@0+ (1,0) [0|1] "SED"  IPMA_ADAS,ECM_Diesel,PCM_FD,PCM_HEV_FD,GWM_ECG
 SG_ DrvSlipCtlLamp_D_Rq : 42|2@0+ (1,0) [0|3] "SED"  IPMA_ADAS,ECM_Diesel,PCM_FD,PCM_HEV_FD,GWM_ECG
 SG_ Abs_B_Falt : 5|1@0+ (1,0) [0|1] "SED"  ECM_Diesel,PCM_FD,PCM_HEV_FD,GWM_ECG
 SG_ DrvSlipCtlMde_D_Ind : 44|2@0+ (1,0) [0|3] "SED"  TCCM_FD,IPMA_ADAS,ECM_Diesel,PCM_FD,PCM_HEV_FD,GWM_ECG
 SG_ BpedMove_No_Cs : 23|8@0+ (1,0) [0|255] "Unitless"  ECM_Diesel,GWM_ECG
 SG_ DrvAntiLckLamp_D_Rq : 55|2@0+ (1,0) [0|3] "SED"  ECM_Diesel,GWM_ECG
 SG_ BpedMove_No_Cnt : 3|4@0+ (1,0) [0|15] "Unitless"  ECM_Diesel,GWM_ECG
 SG_ StabCtlBrk_B_Avail : 4|1@0+ (1,0) [0|1] "SED"  GWM_ECG
 SG_ DrvHdcWarnInfo_D_Rq : 35|2@0+ (1,0) [0|3] "SED"  GWM_ECG
 SG_ DrvHdcMsg_D_Rq : 10|3@0+ (1,0) [0|7] "SED"  GWM_ECG
 SG_ DrvHdcLampInfo_D_Rq : 12|2@0+ (1,0) [0|3] "SED"  GWM_ECG
 SG_ BpedMove_D_Actl : 7|2@0+ (1,0) [0|3] "SED"  ECM_Diesel,GWM_ECG
 SG_ ChimeBrk_B_Rq : 14|1@0+ (1,0) [0|1] "SED"  GWM_ECG
 SG_ BrkLamp_B_Rq : 13|1@0+ (1,0) [0|1] "SED"  GWM_ECG
 SG_ HILL_DESC_MC : 47|3@0+ (1,0) [0|7] "SED"  GWM_ECG

BO_ 1045 BrakeSysFeatures_FD1: 8 ABS_ESC
 SG_ VehStab_D_Stat : 55|4@0+ (1,0) [0|15] "SED"  PCM_FD,PCM_HEV_FD,GWM_ECG
 SG_ BrkFluidLvl_D_Stat : 17|2@0+ (1,0) [0|3] "SED"  GWM_ECG
 SG_ LsmcBrkDecel_D_Stat : 39|3@0+ (1,0) [0|7] "SED"  PSCM_FD,GWM_ECG
 SG_ VehYawNonLin_W_Rq : 51|12@0+ (0.03663,-75) [-75|74.92659] "deg/s"  ECM_Diesel,GWM_ECG
 SG_ VehYawLin_W_Rq : 35|12@0+ (0.03663,-75) [-75|74.92659] "deg/s"  ECM_Diesel,GWM_ECG
 SG_ VehVActlBrk_No_Cs : 31|8@0+ (1,0) [0|255] "Unitless"  PCM_FD,ECM_Diesel,PCM_HEV_FD,PSCM_FD,TCM_DSL_FD,GWM_ECG
 SG_ Veh_V_ActlBrk : 7|16@0+ (0.01,0) [0|655.35] "kph"  PCM_FD,IPMA_ADAS,ECM_Diesel,PCM_HEV_FD,PSCM_FD,TCM_DSL_FD,GWM_ECG
 SG_ VehVActlBrk_No_Cnt : 21|4@0+ (1,0) [0|15] "Unitless"  PCM_FD,ECM_Diesel,PCM_HEV_FD,PSCM_FD,TCM_DSL_FD,GWM_ECG
 SG_ VehVActlBrk_D_Qf : 23|2@0+ (1,0) [0|3] "SED"  PCM_FD,IPMA_ADAS,ECM_Diesel,PCM_HEV_FD,PSCM_FD,TCM_DSL_FD,GWM_ECG

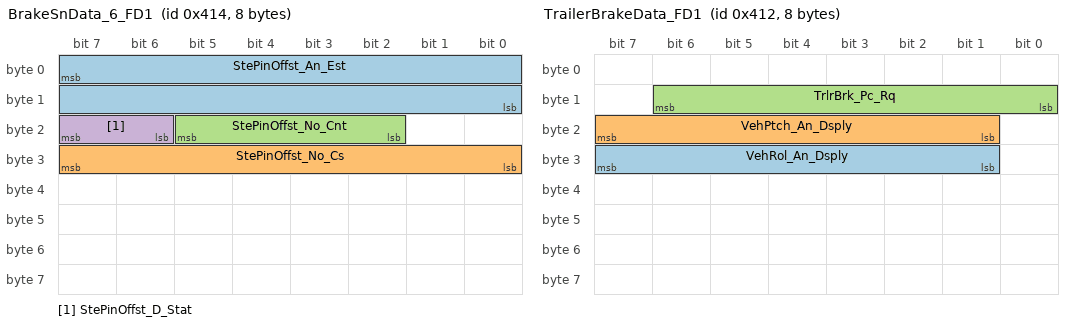
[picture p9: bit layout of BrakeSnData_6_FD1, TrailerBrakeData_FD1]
BO_ 1044 BrakeSnData_6_FD1: 8 ABS_ESC
 SG_ StePinOffst_An_Est : 7|16@0+ (0.1,-3200) [-3200|3353.3] "degrees"  PSCM_FD
 SG_ StePinOffst_No_Cs : 31|8@0+ (1,0) [0|255] "Unitless"  PSCM_FD
 SG_ StePinOffst_No_Cnt : 21|4@0+ (1,0) [0|15] "unitless"  PSCM_FD
 SG_ StePinOffst_D_Stat : 23|2@0+ (1,0) [0|3] "SED"  PSCM_FD

BO_ 1042 TrailerBrakeData_FD1: 8 ABS_ESC
 SG_ VehRol_An_Dsply : 31|7@0+ (1,-64) [-64|61] "degrees"  GWM_ECG
 SG_ VehPtch_An_Dsply : 23|7@0+ (1,-64) [-64|61] "degrees"  GWM_ECG
 SG_ TrlrBrk_Pc_Rq : 14|7@0+ (1,0) [0|127] "percent"  GWM_ECG

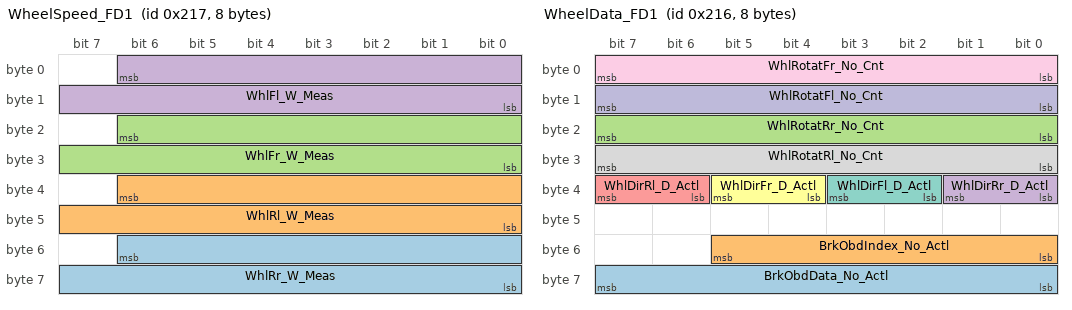
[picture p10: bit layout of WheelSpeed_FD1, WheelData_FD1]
BO_ 535 WheelSpeed_FD1: 8 ABS_ESC
 SG_ WhlRr_W_Meas : 54|15@0+ (0.01,0) [0|327.65] "rad/s"  IPMA_ADAS,GWM_ECG,ECM_Diesel,PCM_FD,PCM_HEV_FD,PSCM_FD,TCCM_FD,TCM_DSL_FD
 SG_ WhlRl_W_Meas : 38|15@0+ (0.01,0) [0|327.65] "rad/s"  IPMA_ADAS,GWM_ECG,ECM_Diesel,PCM_FD,PCM_HEV_FD,PSCM_FD,TCCM_FD,TCM_DSL_FD
 SG_ WhlFr_W_Meas : 22|15@0+ (0.01,0) [0|327.65] "rad/s"  IPMA_ADAS,GWM_ECG,ECM_Diesel,PCM_FD,PCM_HEV_FD,PSCM_FD,TCCM_FD,TCM_DSL_FD
 SG_ WhlFl_W_Meas : 6|15@0+ (0.01,0) [0|327.65] "rad/s"  IPMA_ADAS,GWM_ECG,ECM_Diesel,PCM_FD,PCM_HEV_FD,PSCM_FD,TCCM_FD,TCM_DSL_FD

BO_ 534 WheelData_FD1: 8 ABS_ESC
 SG_ BrkObdData_No_Actl : 63|8@0+ (1,0) [0|255] "unitless"  GWM_ECG
 SG_ BrkObdIndex_No_Actl : 53|6@0+ (1,0) [0|63] "unitless"  GWM_ECG
 SG_ WhlRotatRr_No_Cnt : 23|8@0+ (1,0) [0|255] "Unitless"  PSCM_FD,IPMA_ADAS,GWM_ECG
 SG_ WhlDirRr_D_Actl : 33|2@0+ (1,0) [0|3] "SED"  IPMA_ADAS,GWM_ECG,ECM_Diesel,PCM_HEV_FD,PSCM_FD
 SG_ WhlDirRl_D_Actl : 39|2@0+ (1,0) [0|3] "SED"  IPMA_ADAS,GWM_ECG,PSCM_FD,ECM_Diesel,PCM_HEV_FD
 SG_ WhlDirFr_D_Actl : 37|2@0+ (1,0) [0|3] "SED"  IPMA_ADAS,GWM_ECG,ECM_Diesel,PCM_HEV_FD,PSCM_FD
 SG_ WhlDirFl_D_Actl : 35|2@0+ (1,0) [0|3] "SED"  IPMA_ADAS,GWM_ECG,ECM_Diesel,PCM_HEV_FD,PSCM_FD
 SG_ WhlRotatRl_No_Cnt : 31|8@0+ (1,0) [0|255] "Unitless"  PSCM_FD,IPMA_ADAS,GWM_ECG
 SG_ WhlRotatFr_No_Cnt : 7|8@0+ (1,0) [0|255] "Unitless"  IPMA_ADAS,GWM_ECG,PSCM_FD
 SG_ WhlRotatFl_No_Cnt : 15|8@0+ (1,0) [0|255] "Unitless"  IPMA_ADAS,GWM_ECG,PSCM_FD

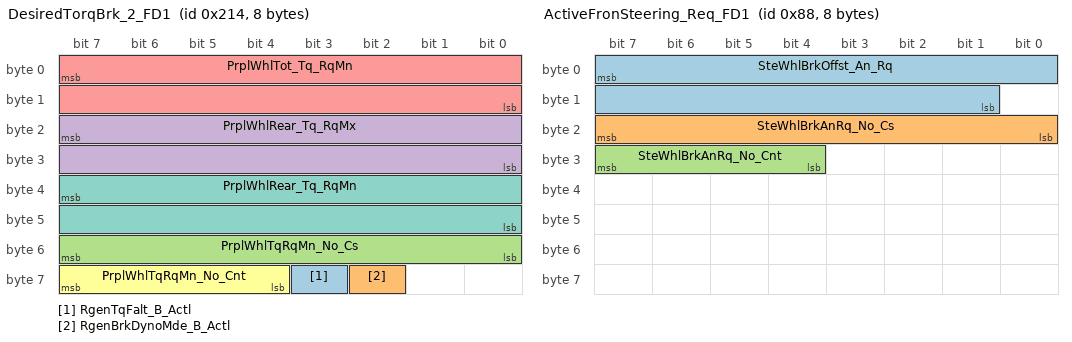
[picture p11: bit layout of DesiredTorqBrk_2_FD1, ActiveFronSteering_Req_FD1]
BO_ 532 DesiredTorqBrk_2_FD1: 8 ABS_ESC
 SG_ RgenTqFalt_B_Actl : 59|1@0+ (1,0) [0|1] "SED"  GWM_ECG,PCM_HEV_FD
 SG_ RgenBrkDynoMde_B_Actl : 58|1@0+ (1,0) [0|1] "SED"  GWM_ECG,PCM_HEV_FD
 SG_ PrplWhlTqRqMn_No_Cs : 55|8@0+ (1,0) [0|255] "Unitless"  GWM_ECG,ECM_Diesel,PCM_FD,PCM_HEV_FD
 SG_ PrplWhlRear_Tq_RqMx : 23|16@0+ (4,-131072) [-131072|131068] "Nm"  GWM_ECG
 SG_ PrplWhlTot_Tq_RqMn : 7|16@0+ (4,-131072) [-131072|131068] "Nm"  GWM_ECG,ECM_Diesel,PCM_FD,PCM_HEV_FD
 SG_ PrplWhlTqRqMn_No_Cnt : 63|4@0+ (1,0) [0|15] "Unitless"  GWM_ECG,ECM_Diesel,PCM_FD,PCM_HEV_FD
 SG_ PrplWhlRear_Tq_RqMn : 39|16@0+ (4,-131072) [-131072|131068] "Nm"  GWM_ECG

BO_ 531 DesiredTorqBrk_FD1: 8 ABS_ESC
 SG_ VehStop_D_Stat : 28|2@0+ (1,0) [0|3] "SED"  IPMA_ADAS,GWM_ECG
 SG_ TracCtlPtActv_B_Actl : 31|1@0+ (1,0) [0|1] "SED"  IPMA_ADAS,TCCM_FD,ECM_Diesel,PCM_FD,PCM_HEV_FD,TCM_DSL_FD,GWM_ECG
 SG_ LscmbbMntr_B_Err : 17|1@0+ (1,0) [0|1] "SED"  GWM_ECG
 SG_ LscmbbBrkDis_B_Actl : 19|1@0+ (1,0) [0|1] "SED"  GWM_ECG
 SG_ LscmbbDeny_B_ActlBrk : 18|1@0+ (1,0) [0|1] "SED"  GWM_ECG
 SG_ PrkBrkYwLamp_D_Rq : 38|2@0+ (1,0) [0|3] "SED"  GWM_ECG
 SG_ PrkBrkRedLamp_D_Rq : 30|2@0+ (1,0) [0|3] "SED"  GWM_ECG
 SG_ VehicleStationary : 39|1@0+ (1,0) [0|1] "SED"  IPMA_ADAS,GWM_ECG
 SG_ LscmbbBrkDecel_B_Actl : 20|1@0+ (1,0) [0|1] "SED"  GWM_ECG
 SG_ AbsActv_B_Actl : 45|1@0+ (1,0) [0|1] "SED"  IPMA_ADAS,ECM_Diesel,PCM_FD,PCM_HEV_FD,TCM_DSL_FD,PSCM_FD,GWM_ECG
 SG_ StabCtlBrkActv_B_Actl : 23|1@0+ (1,0) [0|1] "SED"  IPMA_ADAS,PCM_FD,PCM_HEV_FD,TCM_DSL_FD,PSCM_FD,TCCM_FD,ECM_Diesel,GWM_ECG
 SG_ CmbbBrkPrchg_B_Actl : 59|1@0+ (1,0) [0|1] "SED"  IPMA_ADAS,GWM_ECG
 SG_ CmbbBrkDecel_B_Actl : 58|1@0+ (1,0) [0|1] "SED"  IPMA_ADAS,GWM_ECG
 SG_ CmbbBaSensInc_B_Actl : 57|1@0+ (1,0) [0|1] "SED"  IPMA_ADAS,GWM_ECG
 SG_ AccBrkWarm_B_Actl : 63|1@0+ (1,0) [0|1] "SED"  IPMA_ADAS,GWM_ECG
 SG_ AccBrkTotTqMn_B_Actl : 62|1@0+ (1,0) [0|1] "SED"  IPMA_ADAS,GWM_ECG
 SG_ AccBrkPrchgActv_B_Actl : 61|1@0+ (1,0) [0|1] "SED"  IPMA_ADAS,GWM_ECG
 SG_ AccBrkDis_B_Actl : 44|1@0+ (1,0) [0|1] "SED"  IPMA_ADAS,GWM_ECG
 SG_ AccBrkDeny_B_Actl : 42|1@0+ (1,0) [0|1] "SED"  IPMA_ADAS,ECM_Diesel,PCM_FD,PCM_HEV_FD,GWM_ECG
 SG_ AccBrkActv_B_Actl : 43|1@0+ (1,0) [0|1] "SED"  IPMA_ADAS,ECM_Diesel,GWM_ECG
 SG_ PrplDrgCtlActv_B_Actl : 46|1@0+ (1,0) [0|1] "SED"  ECM_Diesel,PCM_FD,PCM_HEV_FD,TCM_DSL_FD,GWM_ECG
 SG_ PrplWhlTot_Tq_RqMx : 7|16@0+ (4,-131072) [-131072|131068] "Nm"  ECM_Diesel,PCM_FD,PCM_HEV_FD,TCCM_FD,GWM_ECG
 SG_ LscmbbBaSensInc_B_Actl : 21|1@0+ (1,0) [0|1] "SED"  GWM_ECG
 SG_ CmbbBrkDis_B_Actl : 56|1@0+ (1,0) [0|1] "SED"  IPMA_ADAS,PSCM_FD,GWM_ECG
 SG_ CmbbDeny_B_ActlBrk : 60|1@0+ (1,0) [0|1] "SED"  IPMA_ADAS,PSCM_FD,ECM_Diesel,PCM_FD,PCM_HEV_FD,GWM_ECG
 SG_ CcDis_B_Cmd : 47|1@0+ (1,0) [0|1] "SED"  PCM_FD,PCM_HEV_FD,GWM_ECG
 SG_ VehLongOvrGnd_A_Est : 41|10@0+ (0.035,-17.9) [-17.9|17.835] "m/s^2"  IPMA_ADAS,TCCM_FD,GWM_ECG
 SG_ LscmbBrkPrchg_B_Actl : 16|1@0+ (1,0) [0|1] "SED"  GWM_ECG
 SG_ AccStopActv_B_ActlBrk : 22|1@0+ (1,0) [0|1] "SED"  IPMA_ADAS,ECM_Diesel,PCM_FD,PCM_HEV_FD,GWM_ECG
 SG_ AccDis_B_ActlEpb : 32|1@0+ (1,0) [0|1] "SED"  IPMA_ADAS,GWM_ECG
 SG_ PrkBrkMsgTxt_D_Rq : 36|4@0+ (1,0) [0|15] "SED"  GWM_ECG
 SG_ PrkBrkStatus : 26|3@0+ (1,0) [0|7] "SED"  IPMA_ADAS,ECM_Diesel,PCM_FD,PCM_HEV_FD,TCM_DSL_FD,GWM_ECG

BO_ 136 ActiveFronSteering_Req_FD1: 8 ABS_ESC
 SG_ SteWhlBrkOffst_An_Rq : 7|15@0+ (0.1,-1600) [-1600|1676.5] "degrees"  GWM_ECG
 SG_ SteWhlBrkAnRq_No_Cs : 23|8@0+ (1,0) [0|255] "Unitless"  GWM_ECG
 SG_ SteWhlBrkAnRq_No_Cnt : 31|4@0+ (1,0) [0|15] "Unitless"  GWM_ECG

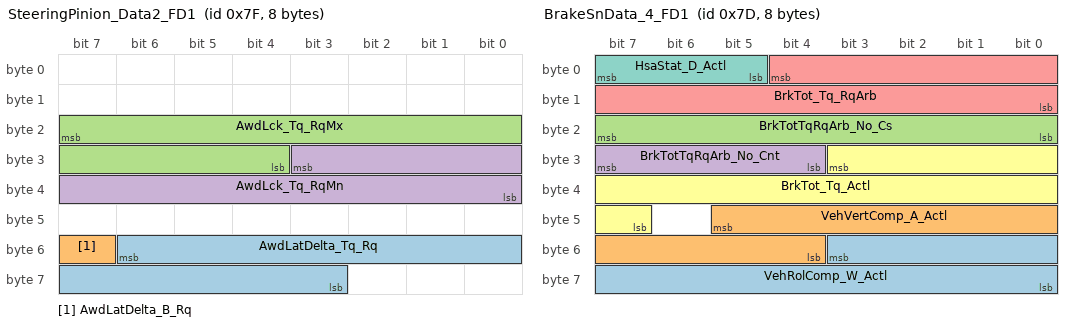
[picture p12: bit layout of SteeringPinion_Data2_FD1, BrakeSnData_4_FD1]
BO_ 127 SteeringPinion_Data2_FD1: 8 ABS_ESC
 SG_ AwdLatDelta_Tq_Rq : 54|12@0+ (2,-4095) [-4095|4095] "Nm"  GWM_ECG
 SG_ AwdLatDelta_B_Rq : 55|1@0+ (1,0) [0|1] "SED"  GWM_ECG
 SG_ AwdLck_Tq_RqMx : 23|12@0+ (1,0) [0|4095] "Nm"  TCCM_FD,GWM_ECG
 SG_ AwdLck_Tq_RqMn : 27|12@0+ (1,0) [0|4095] "Nm"  GWM_ECG

BO_ 125 BrakeSnData_4_FD1: 8 ABS_ESC
 SG_ VehRolComp_W_Actl : 51|12@0+ (0.03663,-75) [-75|74.92659] "degrees/sec"  GWM_ECG
 SG_ VehVertComp_A_Actl : 45|10@0+ (0.035,-17.9) [-17.9|17.835] "m/s^2"  PSCM_FD,GWM_ECG
 SG_ BrkTotTqRqArb_No_Cs : 23|8@0+ (1,0) [0|255] "Unitless"  ECM_Diesel,PCM_FD,PCM_HEV_FD,GWM_ECG
 SG_ BrkTotTqRqArb_No_Cnt : 31|4@0+ (1,0) [0|15] "Unitless"  ECM_Diesel,PCM_FD,PCM_HEV_FD,GWM_ECG
 SG_ BrkTot_Tq_RqArb : 4|13@0+ (4,0) [0|32756] "Nm"  HCM_FD,IPMA_ADAS,ECM_Diesel,PCM_FD,PCM_HEV_FD,TCM_DSL_FD,GWM_ECG
 SG_ BrkTot_Tq_Actl : 27|13@0+ (4,0) [0|32756] "Nm"  ECM_Diesel,PCM_FD,PCM_HEV_FD,PSCM_FD,GWM_ECG
 SG_ HsaStat_D_Actl : 7|3@0+ (1,0) [0|7] "SED"  ECM_Diesel,PCM_FD,PCM_HEV_FD,TCM_DSL_FD,GWM_ECG

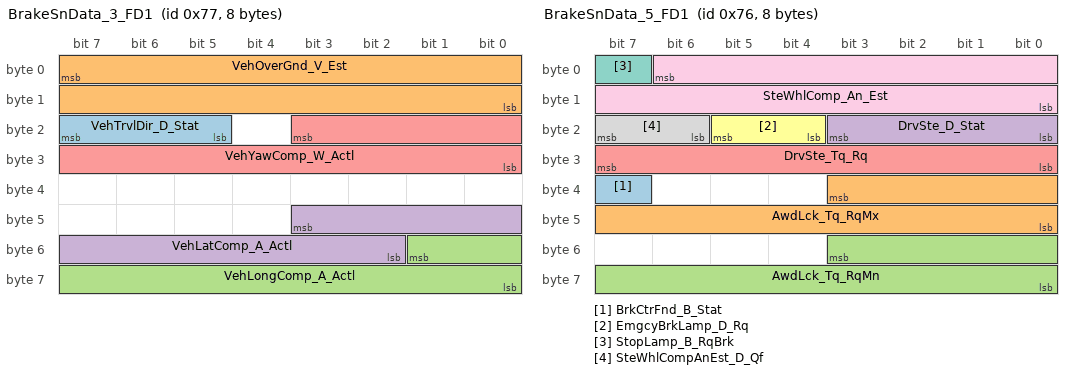
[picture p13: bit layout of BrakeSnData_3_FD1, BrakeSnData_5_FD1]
BO_ 119 BrakeSnData_3_FD1: 8 ABS_ESC
 SG_ VehTrvlDir_D_Stat : 23|3@0+ (1,0) [0|7] "SED"  GWM_ECG
 SG_ VehOverGnd_V_Est : 7|16@0+ (0.01,0) [0|655.33] "kph"  IPMA_ADAS,TCCM_FD,PSCM_FD,GWM_ECG
 SG_ VehLongComp_A_Actl : 49|10@0+ (0.035,-17.9) [-17.9|17.835] "m/s^2"  ECM_Diesel,PCM_FD,PCM_HEV_FD,TCM_DSL_FD,PSCM_FD,GWM_ECG
 SG_ VehLatComp_A_Actl : 43|10@0+ (0.035,-17.9) [-17.9|17.835] "m/s^2"  ECM_Diesel,PCM_FD,PCM_HEV_FD,TCM_DSL_FD,PSCM_FD,TCCM_FD,GWM_ECG
 SG_ VehYawComp_W_Actl : 19|12@0+ (0.03663,-75) [-75|74.92659] "deg/s"  TCCM_FD,IPMA_ADAS,ECM_Diesel,PCM_FD,PCM_HEV_FD,TCM_DSL_FD,PSCM_FD,GWM_ECG

BO_ 118 BrakeSnData_5_FD1: 8 ABS_ESC
 SG_ BrkCtrFnd_B_Stat : 39|1@0+ (1,0) [0|1] "SED"  GWM_ECG
 SG_ AwdLck_Tq_RqMx : 35|12@0+ (1,0) [0|4095] "Nm"  GWM_ECG
 SG_ AwdLck_Tq_RqMn : 51|12@0+ (1,0) [0|4095] "Nm"  TCCM_FD,GWM_ECG
 SG_ DrvSte_D_Stat : 19|4@0+ (1,0) [0|15] "SED"  PSCM_FD,GWM_ECG
 SG_ DrvSte_Tq_Rq : 31|8@0+ (0.0625,-8) [-8|7.8125] "Nm"  PSCM_FD,GWM_ECG
 SG_ EmgcyBrkLamp_D_Rq : 21|2@0+ (1,0) [0|3] "SED"  GWM_ECG
 SG_ StopLamp_B_RqBrk : 7|1@0+ (1,0) [0|1] "SED"  GWM_ECG
 SG_ SteWhlCompAnEst_D_Qf : 23|2@0+ (1,0) [0|3] "SED"  IPMA_ADAS,GWM_ECG
 SG_ SteWhlComp_An_Est : 6|15@0+ (0.1,-1600) [-1600|1676.7] "deg"  IPMA_ADAS,GWM_ECG

BO_ 73 Global_PATS_SubTarget_FD1: 8 ABS_ESC
 SG_ immoSubTarget1Data_T1 : 15|40@0+ (1,0) [0|1099511627775] "Encrypted"  GWM_ECG,PCM_FD,PCM_HEV_FD
 SG_ immoSubTarget1Cmd_T1 : 7|3@0+ (1,0) [0|7] "SED"  GWM_ECG,PCM_FD,PCM_HEV_FD

BO_ 1034 GGCC_Config_Mgmt_ID_1_FD1: 8 GWM_ECG
 SG_ VehicleGGCCData : 7|64@0+ (1,0) [0|1.84467E+019] "mixed"  HCM_FD,IPMA_ADAS,ABS_ESC,ECM_Diesel,PCM_FD,PCM_HEV_FD,PSCM_FD,TCCM_FD,TCM_DSL_FD

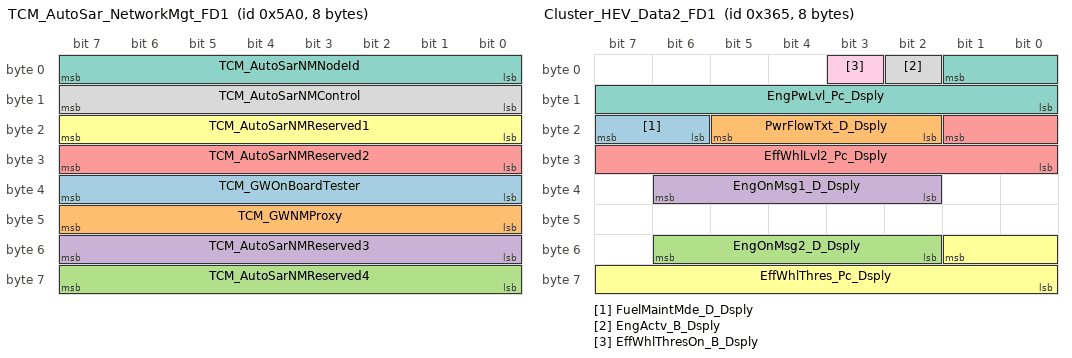
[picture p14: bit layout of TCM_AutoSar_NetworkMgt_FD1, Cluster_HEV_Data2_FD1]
BO_ 1440 TCM_AutoSar_NetworkMgt_FD1: 8 TCM_DSL_FD
 SG_ TCM_GWOnBoardTester : 39|8@0+ (1,0) [0|255] "unitless"  GWM_ECG
 SG_ TCM_GWNMProxy : 47|8@0+ (1,0) [0|255] "unitless"  GWM_ECG
 SG_ TCM_AutoSarNMReserved4 : 63|8@0+ (1,0) [0|255] "unitless"  GWM_ECG
 SG_ TCM_AutoSarNMReserved3 : 55|8@0+ (1,0) [0|255] "unitless"  GWM_ECG
 SG_ TCM_AutoSarNMReserved2 : 31|8@0+ (1,0) [0|255] "unitless"  GWM_ECG
 SG_ TCM_AutoSarNMReserved1 : 23|8@0+ (1,0) [0|255] "unitless"  GWM_ECG
 SG_ TCM_AutoSarNMNodeId : 7|8@0+ (1,0) [0|255] "unitless"  GWM_ECG
 SG_ TCM_AutoSarNMControl : 15|8@0+ (1,0) [0|255] "unitless"  GWM_ECG

BO_ 561 TransGearData_2_FD1: 8 TCM_DSL_FD
 SG_ TrnMsgTxt2_D_Rq : 39|3@0+ (1,0) [0|7] "SED"  GWM_ECG
 SG_ TrnMsgTxt_D_Rq : 23|4@0+ (1,0) [0|15] "SED"  GWM_ECG

BO_ 330 TransData_3_FD1: 8 TCM_DSL_FD
 SG_ TrnAout_W_ActlUnfilt : 22|15@0+ (0.1,0) [0|3276.5] "rad/s"  ECM_Diesel,GWM_ECG

BO_ 869 Cluster_HEV_Data2_FD1: 8 PCM_HEV_FD
 SG_ FuelMaintMde_D_Dsply : 23|2@0+ (1,0) [0|3] "SED"  GWM_ECG
 SG_ PwrFlowTxt_D_Dsply : 21|4@0+ (1,0) [0|15] "SED"  GWM_ECG
 SG_ EngOnMsg2_D_Dsply : 54|5@0+ (1,0) [0|31] "SED"  GWM_ECG
 SG_ EngOnMsg1_D_Dsply : 38|5@0+ (1,0) [0|31] "SED"  GWM_ECG
 SG_ EffWhlLvl2_Pc_Dsply : 17|10@0+ (0.2,-102.2) [-102.2|102.4] "percent"  GWM_ECG
 SG_ EffWhlThres_Pc_Dsply : 49|10@0+ (0.1,0) [0|102.3] "percent"  GWM_ECG
 SG_ EngPwLvl_Pc_Dsply : 1|10@0+ (0.1,0) [0|102.3] "percent"  GWM_ECG
 SG_ EngActv_B_Dsply : 2|1@0+ (1,0) [0|1] "SED"  GWM_ECG
 SG_ EffWhlThresOn_B_Dsply : 3|1@0+ (1,0) [0|1] "SED"  GWM_ECG

BO_ 606 HEV_Powertrain_Data8_FD1: 8 PCM_HEV_FD
 SG_ ElVehLaterMde_D_Stat : 7|2@0+ (1,0) [0|3] "SED"  GWM_ECG
 SG_ ElVehNowMde_D_Stat : 5|2@0+ (1,0) [0|3] "SED"  GWM_ECG

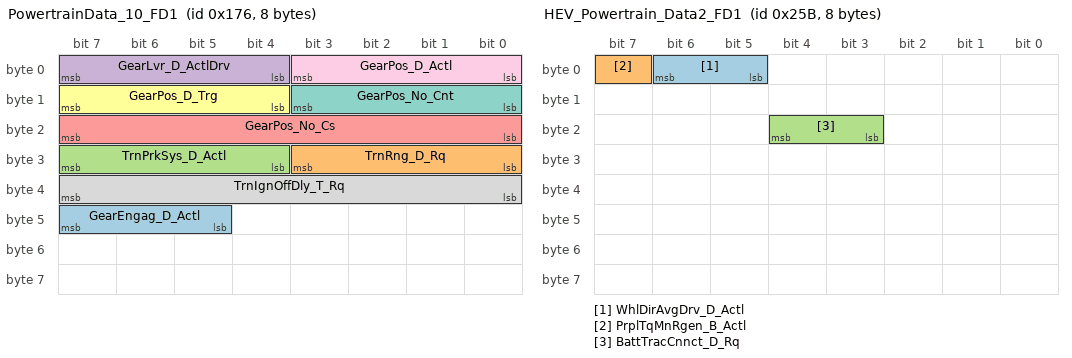
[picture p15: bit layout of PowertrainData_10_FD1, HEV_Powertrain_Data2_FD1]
BO_ 374 PowertrainData_10_FD1: 8 PCM_FD
 SG_ GearEngag_D_Actl : 47|3@0+ (1,0) [0|7] "SED"  GWM_ECG
 SG_ TrnRng_D_Rq : 27|4@0+ (1,0) [0|15] "SED"  IPMA_ADAS,PSCM_FD,ECM_Diesel,GWM_ECG
 SG_ TrnPrkSys_D_Actl : 31|4@0+ (1,0) [0|15] "SED"  IPMA_ADAS,ECM_Diesel,GWM_ECG
 SG_ GearLvr_D_ActlDrv : 7|4@0+ (1,0) [0|15] "SED"  IPMA_ADAS,TCCM_FD,ECM_Diesel,GWM_ECG
 SG_ GearPos_No_Cs : 23|8@0+ (1,0) [0|255] "unitless"  IPMA_ADAS,ABS_ESC,ECM_Diesel,GWM_ECG
 SG_ GearPos_D_Trg : 15|4@0+ (1,0) [0|15] "SED"  HCM_FD,IPMA_ADAS,ABS_ESC,TCCM_FD,ECM_Diesel,GWM_ECG
 SG_ GearPos_No_Cnt : 11|4@0+ (1,0) [0|15] "unitless"  IPMA_ADAS,ABS_ESC,ECM_Diesel,GWM_ECG
 SG_ TrnIgnOffDly_T_Rq : 39|8@0+ (4,0) [0|1020] "ms"  GWM_ECG
 SG_ GearPos_D_Actl : 3|4@0+ (1,0) [0|15] "SED"  PSCM_FD,IPMA_ADAS,ABS_ESC,ECM_Diesel,GWM_ECG

BO_ 603 HEV_Powertrain_Data2_FD1: 8 PCM_HEV_FD
 SG_ WhlDirAvgDrv_D_Actl : 6|2@0+ (1,0) [0|3] "SED"  IPMA_ADAS,GWM_ECG
 SG_ PrplTqMnRgen_B_Actl : 7|1@0+ (1,0) [0|1] "SED"  GWM_ECG
 SG_ BattTracCnnct_D_Rq : 20|2@0+ (1,0) [0|3] "SED"  GWM_ECG

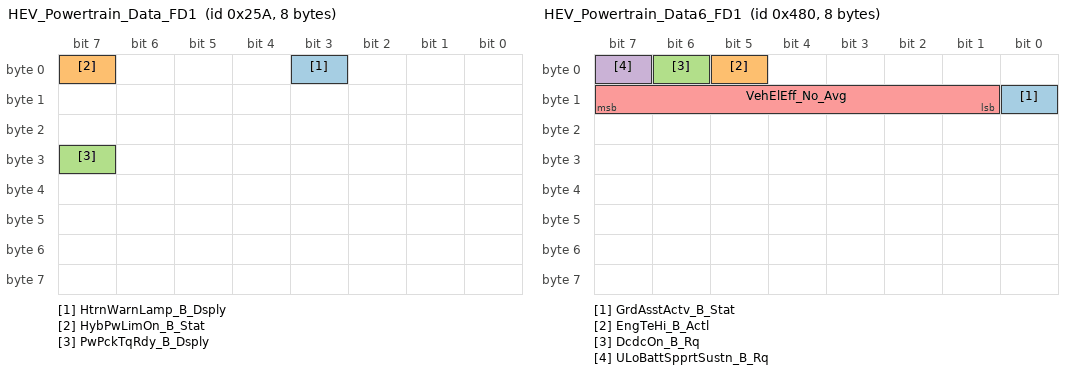
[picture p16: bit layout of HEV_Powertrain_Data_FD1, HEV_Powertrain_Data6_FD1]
BO_ 602 HEV_Powertrain_Data_FD1: 8 PCM_HEV_FD
 SG_ HtrnWarnLamp_B_Dsply : 3|1@0+ (1,0) [0|1] "SED"  GWM_ECG
 SG_ HybPwLimOn_B_Stat : 7|1@0+ (1,0) [0|1] "SED"  GWM_ECG
 SG_ PwPckTqRdy_B_Dsply : 31|1@0+ (1,0) [0|1] "SED"  GWM_ECG

BO_ 1152 HEV_Powertrain_Data6_FD1: 8 PCM_HEV_FD
 SG_ GrdAsstActv_B_Stat : 8|1@0+ (1,0) [0|1] "SED"  GWM_ECG
 SG_ EngTeHi_B_Actl : 5|1@0+ (1,0) [0|1] "SED"  GWM_ECG
 SG_ DcdcOn_B_Rq : 6|1@0+ (1,0) [0|1] "SED"  GWM_ECG
 SG_ ULoBattSpprtSustn_B_Rq : 7|1@0+ (1,0) [0|1] "SED"  GWM_ECG
 SG_ VehElEff_No_Avg : 15|7@0+ (10,-100) [-100|1150] "watt*hr/km"  GWM_ECG

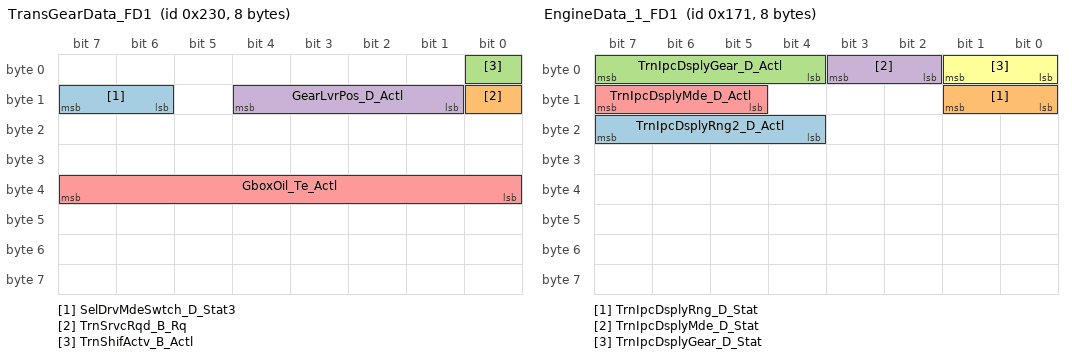
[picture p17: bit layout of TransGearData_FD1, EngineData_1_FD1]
BO_ 560 TransGearData_FD1: 8 TCM_DSL_FD
 SG_ SelDrvMdeSwtch_D_Stat3 : 15|2@0+ (1,0) [0|3] "SED"  GWM_ECG,ABS_ESC
 SG_ TrnSrvcRqd_B_Rq : 8|1@0+ (1,0) [0|1] "SED"  GWM_ECG
 SG_ TrnShifActv_B_Actl : 0|1@0+ (1,0) [0|1] "SED"  GWM_ECG,ABS_ESC,ECM_Diesel
 SG_ GearLvrPos_D_Actl : 12|4@0+ (1,0) [0|15] "SED"  HCM_FD,IPMA_ADAS,GWM_ECG,ABS_ESC,PSCM_FD,TCCM_FD,ECM_Diesel
 SG_ GboxOil_Te_Actl : 39|8@0+ (1,-60) [-60|193] "degC"  GWM_ECG,TCCM_FD,ECM_Diesel

BO_ 369 EngineData_1_FD1: 8 PCM_FD
 SG_ TrnIpcDsplyRng2_D_Actl : 23|4@0+ (1,0) [0|15] "SED"  GWM_ECG
 SG_ TrnIpcDsplyRng_D_Stat : 9|2@0+ (1,0) [0|3] "SED"  GWM_ECG
 SG_ TrnIpcDsplyGear_D_Actl : 7|4@0+ (1,0) [0|15] "SED"  GWM_ECG
 SG_ TrnIpcDsplyMde_D_Stat : 3|2@0+ (1,0) [0|3] "SED"  GWM_ECG
 SG_ TrnIpcDsplyMde_D_Actl : 15|3@0+ (1,0) [0|7] "SED"  GWM_ECG
 SG_ TrnIpcDsplyGear_D_Stat : 1|2@0+ (1,0) [0|3] "SED"  GWM_ECG

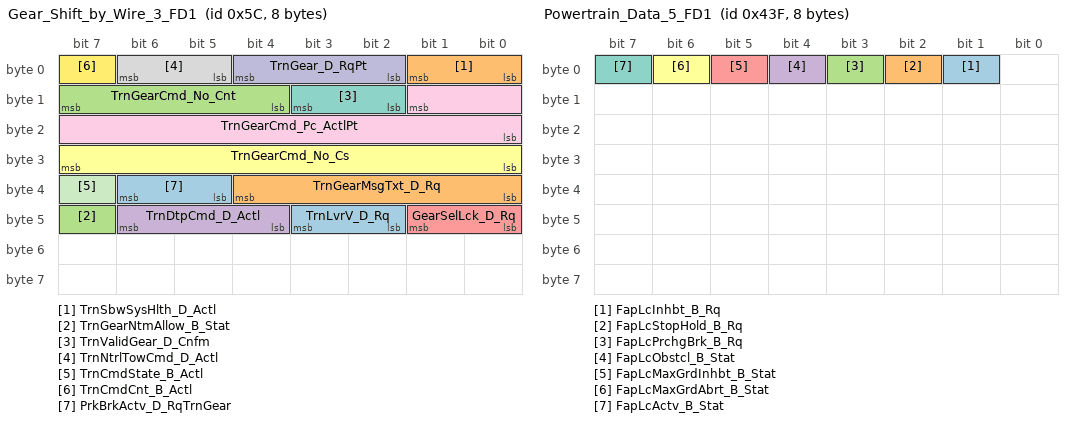
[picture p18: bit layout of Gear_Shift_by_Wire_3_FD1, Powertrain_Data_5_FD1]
BO_ 92 Gear_Shift_by_Wire_3_FD1: 8 PCM_HEV_FD
 SG_ TrnLvrV_D_Rq : 43|2@0+ (1,0) [0|3] "SED"  GWM_ECG
 SG_ TrnSbwSysHlth_D_Actl : 1|2@0+ (1,0) [0|3] "SED"  IPMA_ADAS,GWM_ECG
 SG_ TrnGearNtmAllow_B_Stat : 47|1@0+ (1,0) [0|1] "SED"  GWM_ECG
 SG_ TrnDtpCmd_D_Actl : 46|3@0+ (1,0) [0|7] "SED"  GWM_ECG
 SG_ GearSelLck_D_Rq : 41|2@0+ (1,0) [0|3] "SED"  GWM_ECG
 SG_ TrnGearCmd_No_Cs : 31|8@0+ (1,0) [0|255] "Unitless"  GWM_ECG
 SG_ TrnValidGear_D_Cnfm : 11|2@0+ (1,0) [0|3] "SED"  GWM_ECG
 SG_ TrnNtrlTowCmd_D_Actl : 6|2@0+ (1,0) [0|3] "SED"  IPMA_ADAS,GWM_ECG,ABS_ESC
 SG_ TrnGearCmd_Pc_ActlPt : 9|10@0+ (0.1,0) [0|102.2] "percent duty cycle"  GWM_ECG
 SG_ TrnGear_D_RqPt : 4|3@0+ (1,0) [0|7] "SED"  GWM_ECG
 SG_ TrnCmdState_B_Actl : 39|1@0+ (1,0) [0|1] "SED"  GWM_ECG
 SG_ TrnCmdCnt_B_Actl : 7|1@0+ (1,0) [0|1] "unitless"  GWM_ECG
 SG_ PrkBrkActv_D_RqTrnGear : 38|2@0+ (1,0) [0|3] "SED"  GWM_ECG,ABS_ESC
 SG_ TrnGearMsgTxt_D_Rq : 36|5@0+ (1,0) [0|31] "SED"  GWM_ECG
 SG_ TrnGearCmd_No_Cnt : 15|4@0+ (1,0) [0|15] "Unitless"  GWM_ECG

BO_ 1087 Powertrain_Data_5_FD1: 8 PCM_HEV_FD
 SG_ FapLcInhbt_B_Rq : 1|1@0+ (1,0) [0|1] "SED" Vector__XXX
 SG_ FapLcStopHold_B_Rq : 2|1@0+ (1,0) [0|1] "SED"  ABS_ESC
 SG_ FapLcPrchgBrk_B_Rq : 3|1@0+ (1,0) [0|1] "SED"  ABS_ESC
 SG_ FapLcObstcl_B_Stat : 4|1@0+ (1,0) [0|1] "SED"  IPMA_ADAS
 SG_ FapLcMaxGrdInhbt_B_Stat : 5|1@0+ (1,0) [0|1] "SED"  IPMA_ADAS
 SG_ FapLcMaxGrdAbrt_B_Stat : 6|1@0+ (1,0) [0|1] "SED"  IPMA_ADAS
 SG_ FapLcActv_B_Stat : 7|1@0+ (1,0) [0|1] "SED"  IPMA_ADAS

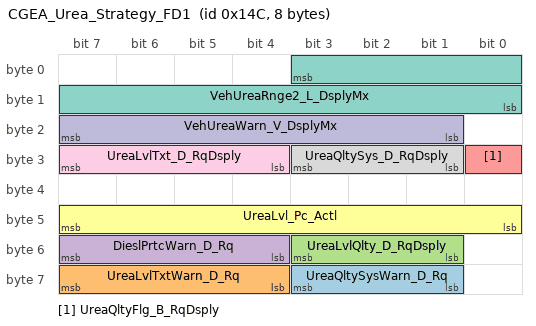
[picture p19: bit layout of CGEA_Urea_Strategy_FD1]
BO_ 332 CGEA_Urea_Strategy_FD1: 8 ECM_Diesel
 SG_ UreaQltySysWarn_D_Rq : 59|3@0+ (1,0) [0|7] "SED"  GWM_ECG
 SG_ UreaLvlTxtWarn_D_Rq : 63|4@0+ (1,0) [0|15] "SED"  GWM_ECG
 SG_ UreaLvlQlty_D_RqDsply : 51|3@0+ (1,0) [0|7] "SED"  GWM_ECG
 SG_ DieslPrtcWarn_D_Rq : 55|4@0+ (1,0) [0|15] "SED"  GWM_ECG
 SG_ UreaQltyFlg_B_RqDsply : 24|1@0+ (1,0) [0|1] "SED"  GWM_ECG
 SG_ UreaLvl_Pc_Actl : 47|8@0+ (0.4,0) [0|102] "percent"  GWM_ECG
 SG_ VehUreaRnge2_L_DsplyMx : 3|12@0+ (1,0) [0|4095] "kilometer"  GWM_ECG
 SG_ UreaQltySys_D_RqDsply : 27|3@0+ (1,0) [0|7] "SED"  GWM_ECG
 SG_ UreaLvlTxt_D_RqDsply : 31|4@0+ (1,0) [0|15] "SED"  GWM_ECG
 SG_ VehUreaWarn_V_DsplyMx : 23|7@0+ (1,0) [0|127] "km/h"  GWM_ECG

BO_ 1896 TesterPhysicalResABS_FD1: 64 ABS_ESC
 SG_ TesterPhysicalResABS : 7|64@0+ (1,0) [0|1.84467E+019] "unitless"  TSTR

BO_ 1889 TesterPhysicalReqTCCM_FD1: 64 TSTR
 SG_ TesterPhysicalReqTCCM : 7|64@0+ (1,0) [0|1.84467E+019] "unitless"  TCCM_FD

BO_ 1888 TesterPhysicalReqABS_FD1: 64 TSTR
 SG_ TesterPhysicalReqABS : 7|64@0+ (1,0) [0|1.84467E+019] "unitless"  ABS_ESC

BO_ 1631 TesterPhysicalResPSCM_FD1: 64 PSCM_FD
 SG_ TesterPhysicalResPSCM : 7|64@0+ (1,0) [0|1.84467E+019] "unitless"  TSTR

BO_TX_BU_ 374 : PCM_HEV_FD,TCM_DSL_FD,PCM_FD;
BO_TX_BU_ 560 : PCM_FD,PCM_HEV_FD,TCM_DSL_FD;
BO_TX_BU_ 369 : PCM_HEV_FD,TCM_DSL_FD,PCM_FD;
BO_TX_BU_ 92 : PCM_FD,TCM_DSL_FD,PCM_HEV_FD;
BO_TX_BU_ 1087 : ECM_Diesel,PCM_FD,PCM_HEV_FD;
CM_ SG_ 391 CmbbBrkDecel_A_Rq "ABSGenSigTimeoutTime=1000";
CM_ SG_ 391 CmbbBrkPrchg_D_Rq "ABSGenSigTimeoutTime=1000";
CM_ SG_ 391 CmbbBrkDecel_B_Rq "ABSGenSigTimeoutTime=1000";
CM_ SG_ 391 CmbbBaSens_D_Rq "ABSGenSigTimeoutTime=1000";
CM_ SG_ 390 AccBrkTot_A_Rq "ABSGenSigTimeoutTime=1000";
CM_ SG_ 390 AccBrkPrkEl_B_Rq "ABSGenSigTimeoutTime=1000";
CM_ SG_ 390 AccPrpl_A_Rq "PCMGenSigTimeoutTime=1000";
CM_ SG_ 390 AccBrkPrchg_B_Rq "ABSGenSigTimeoutTime=1000";
CM_ SG_ 390 AccBrkDecel_B_Rq "ABSGenSigTimeoutTime=1000";
CM_ SG_ 390 AccStopStat_B_Rq "ABSGenSigTimeoutTime=1000";
CM_ BO_ 611 "Used on Applications with 4x4 supplied by Motorola.";
CM_ SG_ 611 AwdStat_D_RqDsply "Signal not transmitted on programs that do not have AWD.";
CM_ SG_ 611 AwdSrvcRqd_B_Rq "Signal not transmitted on programs that do not have AWD.";
CM_ SG_ 611 AwdLck_Tq_Rq "Signal not transmitted on programs that do not have AWD.";
CM_ BO_ 386 "drecker 10/23/09 Need SAPP in sync w/Strg Torque for proper PAM interpretation, else fault msg's displayed FP@20ms IPC needs EPAS_Failure for msg to driver.  Not map w/Lane Assist FP@30s FP), save bandwidth if feature not on vehicle ";
CM_ SG_ 386 VehVTrlrAid_B_Rq "VR session start- req. limit blower speed no more than X volts.  CC restriction on time msg. will be honored.Double Event msg1st event to request limit, 2nd event to release limit, No msg. CC Grammar v7.xls";
CM_ SG_ 386 SteMdule_U_Meas "DCR 1745  to update Tx from GWM to EP100ms. SteMdule_I_Est & SteMdule_U_Meas are used by BMS system & filtered. The filter uses standard periodic rate & changing to EP would adversely affect the filter.(jweinfur)";
CM_ SG_ 386 SteMdule_I_Est "DCR 1745  to update Tx from GWM to EP100ms. SteMdule_I_Est & SteMdule_U_Meas are used by BMS system & filtered. The filter uses standard periodic rate & changing to EP would adversely affect the filter.(jweinfur)";
CM_ SG_ 382 StePinRelInit_An_Sns "SASM will transmit these signals on vehicles with SASM and without PSCM.  SCCM will not Tx this signal when SASM is present.";
CM_ SG_ 382 StePinAn_No_Cs "Signal not transmitted on gas variants.";
CM_ SG_ 1200 BrkTot_Tq_RqDrv "DCR 1836 to update Tx from GWM to EP100ms rejected due MPS6 TCM requires BrkTot_Tq_RqDrv at 20ms (bshu1).";
CM_ SG_ 1046 TCMode "Signal data set to 0x0 for ABS only vehicle option content";
CM_ SG_ 1046 DrvAntiLckLamp_D_Rq "update value table v8.34, not align w/GSDB, need etracker.  ABS & IPC implemented as updated.";
CM_ SG_ 1046 BpedMove_D_Actl "CCMGenSigTimeoutTime=1000";
CM_ SG_ 1044 StePinOffst_An_Est "SASM will transmit these signals on vehicles with SASM and without PSCM.  SCCM will not Tx this signal when SASM is present.";
CM_ SG_ 1044 StePinOffst_No_Cs "Signal not transmitted on gas variants.";
CM_ SG_ 534 BrkObdData_No_Actl "Signal not transmitted on gas, diesel and HEV.  Only supported on PHEV.";
CM_ SG_ 534 BrkObdIndex_No_Actl "Signal not transmitted on gas, diesel and HEV.  Only supported on PHEV.";
CM_ SG_ 534 WhlRotatRr_No_Cnt "DCR 1833 to update Tx from GWM to EP100ms. Wheel Count signals are used by complex algorithm to determine Tire Pressure by Location & can't change from 20msec. (jweinfur)";
CM_ SG_ 534 WhlRotatRl_No_Cnt "DCR 1833 to update Tx from GWM to EP100ms. Wheel Count signals are used by complex algorithm to determine Tire Pressure by Location & can't change from 20msec. (jweinfur)";
CM_ SG_ 534 WhlRotatFr_No_Cnt "DCR 1833 to update Tx from GWM to EP100ms. Wheel Count signals are used by complex algorithm to determine Tire Pressure by Location & can't change from 20msec. (jweinfur)";
CM_ SG_ 534 WhlRotatFl_No_Cnt "DCR 1833 to update Tx from GWM to EP100ms. Wheel Count signals are used by complex algorithm to determine Tire Pressure by Location & can't change from 20msec. (jweinfur)";
CM_ BO_ 532 "IC is NOT to use data in this message for displays, Used data from 415 instead.";
CM_ BO_ 531 "When PBM is present use 0x41B for PrkMsgTxt_D_Rq, PrkBrkRedLamp_D_Rq, PrkBrkYwLamp_D_Rq source signals otherwise ABS will source from 0x213.";
CM_ SG_ 531 VehLongOvrGnd_A_Est "CCMGenSigTimeoutTime=1000";
CM_ SG_ 118 SteWhlCompAnEst_D_Qf "Legacy signal not supported, reserving bit locations for commodity BCM, PAM, RCM, APIM dbc files.  GWM to Tx Init value, no valid data. ";
CM_ SG_ 118 SteWhlComp_An_Est "Legacy signal not supported, reserving bit locations for commodity BCM, PAM, RCM, APIM dbc files.  GWM to Tx Init value, no valid data. ";
CM_ BO_ 73 "Provide target function information to the control function of the Passive Anti-Theft Subsystem";
CM_ SG_ 1034 VehicleGGCCData "RCMGenSigTimeout=6000";
CM_ BO_ 374 "Programs w/o HS1 0x172 will need HS1 0x176 for GearPos_D_Actl.  Future MY Programs that choose c/o still require HS1 0x172. ";
CM_ SG_ 374 TrnRng_D_Rq "Powersplit HEVs with HF45, HPCM will Tx  this message.  For all other programs it will be Tx by PCM or TCM. ";
CM_ SG_ 374 TrnPrkSys_D_Actl "Powersplit HEVs with HF45, HPCM will Tx  this message.  For all other programs it will be Tx by PCM or TCM. ";
CM_ SG_ 374 GearLvr_D_ActlDrv "Powersplit HEVs with HF45, HPCM will Tx  this message.  For all other programs it will be Tx by PCM or TCM. ";
CM_ SG_ 374 GearPos_No_Cs "Powersplit HEVs with HF45, HPCM will Tx  this message.  For all other programs it will be Tx by PCM or TCM. ";
CM_ SG_ 374 GearPos_D_Trg "Powersplit HEVs with HF45, HPCM will Tx  this message.  For all other programs it will be Tx by PCM or TCM. ";
CM_ SG_ 374 GearPos_No_Cnt "Powersplit HEVs with HF45, HPCM will Tx  this message.  For all other programs it will be Tx by PCM or TCM. ";
CM_ SG_ 374 GearPos_D_Actl "Powersplit HEVs with HF45, HPCM will Tx  this message.  For all other programs it will be Tx by PCM or TCM. ";
CM_ BO_ 603 "48V mHEV: ECM_HEVDSL is Tx
MHT HEV: PCM_HEV is Tx
Powersplit HEV: SOBDMC_HPCM is Tx
";
CM_ SG_ 603 WhlDirAvgDrv_D_Actl "48V mHEV: ECM_HEVDSL is Tx,  MHT HEV: PCM_HEV is Tx,  Powersplit HEV: SOBDMC_HPCM is Tx";
CM_ SG_ 603 PrplTqMnRgen_B_Actl "48V mHEV: ECM_HEVDSL is Tx,  MHT HEV: PCM_HEV is Tx,  Powersplit HEV: SOBDMC_HPCM is Tx";
CM_ SG_ 603 BattTracCnnct_D_Rq "48V mHEV: ECM_HEVDSL is Tx,  MHT HEV: PCM_HEV is Tx,  Powersplit HEV: SOBDMC_HPCM is Tx";
CM_ BO_ 560 "MHT (U611/625) the HPCM will Rx 0x230 from the PCM_HEV
Powersplit FWD HEV’s (Cx482/3 430) the HPCM will Tx 0x230";
CM_ SG_ 560 SelDrvMdeSwtch_D_Stat3 "ECM_HEV does not support or Transmit signal.";
CM_ SG_ 560 TrnSrvcRqd_B_Rq "Signal not transmitted on Diesel & HEV variants. MHT(U611/625) HPCM Rx 0x230 from PCM_HEV. Powersplit FWD HEV’s(Cx482/3 430) HPCM Tx 0x230.";
CM_ SG_ 560 TrnShifActv_B_Actl "Signal not transmitted on HEV variants. MHT(U611/625) HPCM Rx 0x230 from PCM_HEV. Powersplit FWD HEV’s(Cx482/3 430) HPCM Tx 0x230.";
CM_ SG_ 560 GboxOil_Te_Actl "Signal not transmitted on HEV variants. MHT(U611/625) HPCM Rx 0x230 from PCM_HEV. Powersplit FWD HEV’s(Cx482/3 430) HPCM Tx 0x230.";
CM_ SG_ 92 TrnSbwSysHlth_D_Actl "Signal not transmitted on vehicles that do not have shift by wire.";
CM_ SG_ 92 TrnGearNtmAllow_B_Stat "Signal not transmitted on vehicles that do not have shift by wire.";
CM_ SG_ 92 TrnDtpCmd_D_Actl "Signal not transmitted on vehicles that do not have shift by wire.";
CM_ SG_ 92 TrnGearCmd_No_Cs "Signal not transmitted on vehicles that do not have shift by wire.";
CM_ SG_ 92 TrnValidGear_D_Cnfm "Signal not transmitted on vehicles that do not have shift by wire.";
CM_ SG_ 92 TrnNtrlTowCmd_D_Actl "Signal not transmitted on vehicles that do not have shift by wire.";
CM_ SG_ 92 TrnGearCmd_Pc_ActlPt "Signal not transmitted on vehicles that do not have shift by wire.";
CM_ SG_ 92 TrnGear_D_RqPt "Signal not transmitted on vehicles that do not have shift by wire.";
CM_ SG_ 92 TrnCmdState_B_Actl "Signal not transmitted on vehicles that do not have shift by wire.";
CM_ SG_ 92 TrnCmdCnt_B_Actl "Signal not transmitted on vehicles that do not have shift by wire.";
CM_ SG_ 92 PrkBrkActv_D_RqTrnGear "Signal not transmitted on vehicles that do not have shift by wire.";
CM_ SG_ 92 TrnGearMsgTxt_D_Rq "Signal not transmitted on vehicles that do not have shift by wire.";
CM_ SG_ 92 TrnGearCmd_No_Cnt "Signal not transmitted on vehicles that do not have shift by wire.";
BA_DEF_ BO_  "VFrameFormat" ENUM  "StandardCAN","ExtendedCAN","reserved","reserved","reserved","reserved","reserved","reserved","reserved","reserved","reserved","reserved","reserved","reserved","StandardCAN_FD","ExtendedCAN_FD";
BA_DEF_ SG_  "GenSigSendType" ENUM  "Cyclic","OnWrite","vector_leerstring","OnChange","vector_leerstring","IfActive","vector_leerstring","NoSigSendType";
BA_DEF_ SG_  "GenSigInactiveValue" INT 0 100000;
BA_DEF_ SG_  "WakeupSignal" ENUM  "No","Yes";
BA_DEF_ SG_  "CrossOver_InfoCAN" ENUM  "No","Yes";
BA_DEF_ SG_  "UsedOnPgmDBC" ENUM  "No","Yes";
BA_DEF_ SG_  "GenSigStartValue" INT 0 1000000000;
BA_DEF_ SG_  "ContentDependant" ENUM  "No","Yes";
BA_DEF_ SG_  "MetaData" ENUM  "No","Yes";
BA_DEF_ SG_  "U_P702_MY2021_Rx" ENUM  "No","Yes";
BA_DEF_ SG_  "U_CX727_MY2021_Tx" ENUM  "No","Yes";
BA_DEF_ SG_  "U_P702_MY2021_Tx" ENUM  "No","Yes";
BA_DEF_ BO_  "GenMsgILSupport" ENUM  "No","Yes";
BA_DEF_ BO_  "DiagResponse" ENUM  "No","Yes";
BA_DEF_ BO_  "DiagRequest" ENUM  "No","Yes";
BA_DEF_ BO_  "DiagState" ENUM  "No","Yes";
BA_DEF_ BO_  "TpApplType" STRING ;
BA_DEF_ BO_  "NmAsrMessage" ENUM  "No","Yes";
BA_DEF_ BO_  "MessageGateway" ENUM  "No","Yes";
BA_DEF_ BO_  "AuthFreshnessCounterSyncAttempt" INT 0 2;
BA_DEF_ BO_  "GenMsgSendType" ENUM  "FixedPeriodic","Event","EnabledPeriodic","NotUsed","NotUsed","EventPeriodic","NotUsed","NotUsed","NoMsgSendType";
BA_DEF_ BO_  "GenMsgCycleTime" INT 0 100000;
BA_DEF_ BO_  "GenMsgDelayTime" INT 0 1000;
BA_DEF_ BO_  "GenMsgNrOfRepetition" INT 0 100;
BA_DEF_ BO_  "GenMsgStartDelayTime" INT 0 10000;
BA_DEF_ BO_  "EventRateOfChange" INT 10 10000;
BA_DEF_ BO_  "FrameGatewayId" HEX 0 1407;
BA_DEF_ BO_  "NetworkInitialization" ENUM  "No","Yes";
BA_DEF_ BO_  "FrameGatewayNetwork" STRING ;
BA_DEF_DEF_  "VFrameFormat" "ExtendedCAN_FD";
BA_DEF_DEF_  "GenSigSendType" "NoSigSendType";
BA_DEF_DEF_  "GenSigInactiveValue" 0;
BA_DEF_DEF_  "WakeupSignal" "No";
BA_DEF_DEF_  "CrossOver_InfoCAN" "No";
BA_DEF_DEF_  "UsedOnPgmDBC" "Yes";
BA_DEF_DEF_  "GenSigStartValue" 0;
BA_DEF_DEF_  "ContentDependant" "No";
BA_DEF_DEF_  "MetaData" "No";
BA_DEF_DEF_  "U_P702_MY2021_Rx" "No";
BA_DEF_DEF_  "U_CX727_MY2021_Tx" "No";
BA_DEF_DEF_  "U_P702_MY2021_Tx" "No";
BA_DEF_DEF_  "GenMsgILSupport" "Yes";
BA_DEF_DEF_  "DiagResponse" "No";
BA_DEF_DEF_  "DiagRequest" "No";
BA_DEF_DEF_  "DiagState" "No";
BA_DEF_DEF_  "TpApplType" "";
BA_DEF_DEF_  "NmAsrMessage" "No";
BA_DEF_DEF_  "MessageGateway" "No";
BA_DEF_DEF_  "AuthFreshnessCounterSyncAttempt" 2;
BA_DEF_DEF_  "GenMsgSendType" "NoMsgSendType";
BA_DEF_DEF_  "GenMsgCycleTime" 0;
BA_DEF_DEF_  "GenMsgDelayTime" 20;
BA_DEF_DEF_  "GenMsgNrOfRepetition" 1;
BA_DEF_DEF_  "GenMsgStartDelayTime" 0;
BA_DEF_DEF_  "EventRateOfChange" 10000;
BA_DEF_DEF_  "FrameGatewayId" 0;
BA_DEF_DEF_  "NetworkInitialization" "Yes";
BA_DEF_DEF_  "FrameGatewayNetwork" "NONE";
BA_ "FrameGatewayNetwork" BO_ 970 "HS2_CAN";
BA_ "FrameGatewayId" BO_ 970 970;
BA_ "GenMsgDelayTime" BO_ 970 10;
BA_ "VFrameFormat" BO_ 970 14;
BA_ "GenMsgCycleTime" BO_ 962 1000;
BA_ "GenMsgSendType" BO_ 962 5;
BA_ "VFrameFormat" BO_ 962 14;
BA_ "GenMsgCycleTime" BO_ 961 1000;
BA_ "GenMsgSendType" BO_ 961 5;
BA_ "VFrameFormat" BO_ 961 14;
BA_ "GenMsgCycleTime" BO_ 394 200;
BA_ "GenMsgSendType" BO_ 394 0;
BA_ "VFrameFormat" BO_ 394 14;
BA_ "FrameGatewayNetwork" BO_ 391 "HS2_CAN";
BA_ "FrameGatewayId" BO_ 391 391;
BA_ "GenMsgDelayTime" BO_ 391 10;
BA_ "VFrameFormat" BO_ 391 14;
BA_ "FrameGatewayNetwork" BO_ 390 "HS2_CAN";
BA_ "FrameGatewayId" BO_ 390 390;
BA_ "GenMsgDelayTime" BO_ 390 10;
BA_ "VFrameFormat" BO_ 390 14;
BA_ "GenMsgCycleTime" BO_ 1441 1000;
BA_ "GenMsgSendType" BO_ 1441 0;
BA_ "NmAsrMessage" BO_ 1441 1;
BA_ "GenMsgILSupport" BO_ 1441 0;
BA_ "VFrameFormat" BO_ 1441 14;
BA_ "GenMsgCycleTime" BO_ 1186 100;
BA_ "GenMsgSendType" BO_ 1186 0;
BA_ "VFrameFormat" BO_ 1186 14;
BA_ "GenMsgCycleTime" BO_ 611 100;
BA_ "GenMsgSendType" BO_ 611 0;
BA_ "VFrameFormat" BO_ 611 14;
BA_ "GenMsgCycleTime" BO_ 1717 1000;
BA_ "GenMsgSendType" BO_ 1717 0;
BA_ "NmAsrMessage" BO_ 1717 1;
BA_ "GenMsgILSupport" BO_ 1717 0;
BA_ "VFrameFormat" BO_ 1717 14;
BA_ "GenMsgCycleTime" BO_ 1303 1000;
BA_ "GenMsgSendType" BO_ 1303 5;
BA_ "VFrameFormat" BO_ 1303 14;
BA_ "GenMsgDelayTime" BO_ 1228 10;
BA_ "GenMsgCycleTime" BO_ 1228 30;
BA_ "GenMsgSendType" BO_ 1228 0;
BA_ "VFrameFormat" BO_ 1228 14;
BA_ "GenMsgDelayTime" BO_ 386 10;
BA_ "GenMsgCycleTime" BO_ 386 20;
BA_ "GenMsgSendType" BO_ 386 0;
BA_ "VFrameFormat" BO_ 386 14;
BA_ "GenMsgDelayTime" BO_ 382 0;
BA_ "GenMsgCycleTime" BO_ 382 10;
BA_ "GenMsgSendType" BO_ 382 0;
BA_ "MessageGateway" BO_ 382 1;
BA_ "VFrameFormat" BO_ 382 14;
BA_ "GenMsgCycleTime" BO_ 1430 1000;
BA_ "GenMsgSendType" BO_ 1430 0;
BA_ "NmAsrMessage" BO_ 1430 1;
BA_ "GenMsgILSupport" BO_ 1430 0;
BA_ "VFrameFormat" BO_ 1430 14;
BA_ "GenMsgDelayTime" BO_ 1200 10;
BA_ "GenMsgCycleTime" BO_ 1200 20;
BA_ "GenMsgSendType" BO_ 1200 0;
BA_ "VFrameFormat" BO_ 1200 14;
BA_ "GenMsgStartDelayTime" BO_ 1102 1130;
BA_ "GenMsgCycleTime" BO_ 1102 100000;
BA_ "GenMsgSendType" BO_ 1102 5;
BA_ "VFrameFormat" BO_ 1102 14;
BA_ "GenMsgCycleTime" BO_ 1056 1000;
BA_ "GenMsgSendType" BO_ 1056 5;
BA_ "VFrameFormat" BO_ 1056 14;
BA_ "GenMsgCycleTime" BO_ 1054 1000;
BA_ "GenMsgSendType" BO_ 1054 5;
BA_ "VFrameFormat" BO_ 1054 14;
BA_ "GenMsgCycleTime" BO_ 1046 100;
BA_ "GenMsgSendType" BO_ 1046 0;
BA_ "VFrameFormat" BO_ 1046 14;
BA_ "GenMsgDelayTime" BO_ 1045 10;
BA_ "GenMsgCycleTime" BO_ 1045 20;
BA_ "GenMsgSendType" BO_ 1045 0;
BA_ "VFrameFormat" BO_ 1045 14;
BA_ "GenMsgCycleTime" BO_ 1044 100;
BA_ "GenMsgSendType" BO_ 1044 0;
BA_ "VFrameFormat" BO_ 1044 14;
BA_ "GenMsgCycleTime" BO_ 1042 50;
BA_ "GenMsgSendType" BO_ 1042 0;
BA_ "VFrameFormat" BO_ 1042 14;
BA_ "GenMsgDelayTime" BO_ 535 0;
BA_ "GenMsgCycleTime" BO_ 535 10;
BA_ "GenMsgSendType" BO_ 535 0;
BA_ "VFrameFormat" BO_ 535 14;
BA_ "GenMsgDelayTime" BO_ 534 10;
BA_ "GenMsgCycleTime" BO_ 534 20;
BA_ "GenMsgSendType" BO_ 534 0;
BA_ "VFrameFormat" BO_ 534 14;
BA_ "GenMsgDelayTime" BO_ 532 10;
BA_ "GenMsgCycleTime" BO_ 532 20;
BA_ "GenMsgSendType" BO_ 532 0;
BA_ "VFrameFormat" BO_ 532 14;
BA_ "GenMsgDelayTime" BO_ 531 10;
BA_ "GenMsgCycleTime" BO_ 531 20;
BA_ "GenMsgSendType" BO_ 531 0;
BA_ "VFrameFormat" BO_ 531 14;
BA_ "GenMsgDelayTime" BO_ 136 0;
BA_ "GenMsgCycleTime" BO_ 136 10;
BA_ "GenMsgSendType" BO_ 136 0;
BA_ "VFrameFormat" BO_ 136 14;
BA_ "GenMsgDelayTime" BO_ 127 10;
BA_ "GenMsgCycleTime" BO_ 127 20;
BA_ "GenMsgSendType" BO_ 127 0;
BA_ "VFrameFormat" BO_ 127 14;
BA_ "GenMsgDelayTime" BO_ 125 10;
BA_ "GenMsgCycleTime" BO_ 125 20;
BA_ "GenMsgSendType" BO_ 125 0;
BA_ "VFrameFormat" BO_ 125 14;
BA_ "GenMsgDelayTime" BO_ 119 10;
BA_ "GenMsgCycleTime" BO_ 119 20;
BA_ "GenMsgSendType" BO_ 119 0;
BA_ "VFrameFormat" BO_ 119 14;
BA_ "GenMsgCycleTime" BO_ 118 500;
BA_ "GenMsgSendType" BO_ 118 5;
BA_ "VFrameFormat" BO_ 118 14;
BA_ "GenMsgDelayTime" BO_ 73 10;
BA_ "GenMsgCycleTime" BO_ 73 20;
BA_ "GenMsgSendType" BO_ 73 0;
BA_ "VFrameFormat" BO_ 73 14;
BA_ "FrameGatewayNetwork" BO_ 1034 "HS1_CAN";
BA_ "FrameGatewayId" BO_ 1034 1034;
BA_ "VFrameFormat" BO_ 1034 14;
BA_ "GenMsgCycleTime" BO_ 1440 1000;
BA_ "GenMsgSendType" BO_ 1440 0;
BA_ "NmAsrMessage" BO_ 1440 1;
BA_ "GenMsgILSupport" BO_ 1440 0;
BA_ "VFrameFormat" BO_ 1440 14;
BA_ "GenMsgCycleTime" BO_ 561 100;
BA_ "GenMsgSendType" BO_ 561 0;
BA_ "VFrameFormat" BO_ 561 14;
BA_ "GenMsgDelayTime" BO_ 330 0;
BA_ "GenMsgCycleTime" BO_ 330 10;
BA_ "GenMsgSendType" BO_ 330 0;
BA_ "VFrameFormat" BO_ 330 14;
BA_ "GenMsgCycleTime" BO_ 869 100;
BA_ "GenMsgSendType" BO_ 869 0;
BA_ "VFrameFormat" BO_ 869 14;
BA_ "GenMsgCycleTime" BO_ 606 1000;
BA_ "GenMsgSendType" BO_ 606 5;
BA_ "VFrameFormat" BO_ 606 14;
BA_ "GenMsgCycleTime" BO_ 374 100;
BA_ "GenMsgSendType" BO_ 374 5;
BA_ "VFrameFormat" BO_ 374 14;
BA_ "GenMsgDelayTime" BO_ 603 10;
BA_ "GenMsgCycleTime" BO_ 603 20;
BA_ "GenMsgSendType" BO_ 603 0;
BA_ "VFrameFormat" BO_ 603 14;
BA_ "GenMsgCycleTime" BO_ 602 100;
BA_ "GenMsgSendType" BO_ 602 0;
BA_ "VFrameFormat" BO_ 602 14;
BA_ "GenMsgCycleTime" BO_ 1152 1000;
BA_ "GenMsgSendType" BO_ 1152 5;
BA_ "VFrameFormat" BO_ 1152 14;
BA_ "GenMsgDelayTime" BO_ 560 10;
BA_ "GenMsgCycleTime" BO_ 560 20;
BA_ "GenMsgSendType" BO_ 560 0;
BA_ "VFrameFormat" BO_ 560 14;
BA_ "GenMsgDelayTime" BO_ 369 10;
BA_ "GenMsgCycleTime" BO_ 369 30;
BA_ "GenMsgSendType" BO_ 369 0;
BA_ "VFrameFormat" BO_ 369 14;
BA_ "GenMsgCycleTime" BO_ 92 100;
BA_ "GenMsgSendType" BO_ 92 5;
BA_ "VFrameFormat" BO_ 92 14;
BA_ "GenMsgCycleTime" BO_ 1087 1000;
BA_ "GenMsgSendType" BO_ 1087 5;
BA_ "VFrameFormat" BO_ 1087 14;
BA_ "GenMsgCycleTime" BO_ 332 200;
BA_ "GenMsgSendType" BO_ 332 0;
BA_ "VFrameFormat" BO_ 332 14;
BA_ "GenMsgDelayTime" BO_ 1896 0;
BA_ "GenMsgSendType" BO_ 1896 1;
BA_ "DiagResponse" BO_ 1896 1;
BA_ "GenMsgILSupport" BO_ 1896 0;
BA_ "VFrameFormat" BO_ 1896 14;
BA_ "GenMsgDelayTime" BO_ 1889 0;
BA_ "GenMsgSendType" BO_ 1889 1;
BA_ "DiagRequest" BO_ 1889 1;
BA_ "GenMsgILSupport" BO_ 1889 0;
BA_ "VFrameFormat" BO_ 1889 14;
BA_ "GenMsgDelayTime" BO_ 1888 0;
BA_ "GenMsgSendType" BO_ 1888 1;
BA_ "DiagRequest" BO_ 1888 1;
BA_ "GenMsgILSupport" BO_ 1888 0;
BA_ "VFrameFormat" BO_ 1888 14;
BA_ "GenMsgDelayTime" BO_ 1631 0;
BA_ "GenMsgSendType" BO_ 1631 1;
BA_ "DiagResponse" BO_ 1631 1;
BA_ "GenMsgILSupport" BO_ 1631 0;
BA_ "VFrameFormat" BO_ 1631 14;
BA_ "U_P702_MY2021_Rx" SG_ 970 LkaActvStats_D2_Req 1;
BA_ "U_P702_MY2021_Rx" SG_ 970 LaRefAng_No_Req 1;
BA_ "GenSigStartValue" SG_ 970 LaRefAng_No_Req 2048;
BA_ "U_P702_MY2021_Rx" SG_ 970 LaRampType_B_Req 1;
BA_ "U_P702_MY2021_Rx" SG_ 970 LaCurvature_No_Calc 1;
BA_ "GenSigStartValue" SG_ 970 LaCurvature_No_Calc 2048;
BA_ "U_P702_MY2021_Rx" SG_ 970 LdwActvStats_D_Req 1;
BA_ "U_P702_MY2021_Rx" SG_ 970 LdwActvIntns_D_Req 1;
BA_ "CrossOver_InfoCAN" SG_ 970 LdwActvIntns_D_Req 1;
BA_ "U_P702_MY2021_Rx" SG_ 962 AdbBrdr3DistRigh_D_Stat 1;
BA_ "GenSigSendType" SG_ 962 AdbBrdr3DistRigh_D_Stat 3;
BA_ "U_P702_MY2021_Rx" SG_ 962 AdbBrdr3DistLeft_D_Stat 1;
BA_ "GenSigSendType" SG_ 962 AdbBrdr3DistLeft_D_Stat 3;
BA_ "U_P702_MY2021_Rx" SG_ 962 AdbMde3_D_Rq 1;
BA_ "GenSigSendType" SG_ 962 AdbMde3_D_Rq 3;
BA_ "U_P702_MY2021_Rx" SG_ 962 AdbIntns3_D_Rq 1;
BA_ "GenSigSendType" SG_ 962 AdbIntns3_D_Rq 3;
BA_ "U_P702_MY2021_Rx" SG_ 962 AdbBrdr3Up_An_Rq 1;
BA_ "GenSigStartValue" SG_ 962 AdbBrdr3Up_An_Rq 510;
BA_ "U_P702_MY2021_Rx" SG_ 962 AdbBrdr3Right_An_Rq 1;
BA_ "GenSigStartValue" SG_ 962 AdbBrdr3Right_An_Rq 2046;
BA_ "U_P702_MY2021_Rx" SG_ 962 AdbBrdr3Low_An_Rq 1;
BA_ "GenSigStartValue" SG_ 962 AdbBrdr3Low_An_Rq 510;
BA_ "U_P702_MY2021_Rx" SG_ 962 AdbBrdr3Left_An_Rq 1;
BA_ "GenSigStartValue" SG_ 962 AdbBrdr3Left_An_Rq 2046;
BA_ "U_P702_MY2021_Rx" SG_ 962 AdbBrdr3CritRigh_T_Stat 1;
BA_ "U_P702_MY2021_Rx" SG_ 962 AdbBrdr3CritLeft_T_Stat 1;
BA_ "U_P702_MY2021_Rx" SG_ 961 AdbBrdr2DistRigh_D_Stat 1;
BA_ "GenSigSendType" SG_ 961 AdbBrdr2DistRigh_D_Stat 3;
BA_ "U_P702_MY2021_Rx" SG_ 961 AdbBrdr2DistLeft_D_Stat 1;
BA_ "GenSigSendType" SG_ 961 AdbBrdr2DistLeft_D_Stat 3;
BA_ "U_P702_MY2021_Rx" SG_ 961 AdbMde2_D_Rq 1;
BA_ "GenSigSendType" SG_ 961 AdbMde2_D_Rq 3;
BA_ "U_P702_MY2021_Rx" SG_ 961 AdbIntns2_D_Rq 1;
BA_ "GenSigSendType" SG_ 961 AdbIntns2_D_Rq 3;
BA_ "U_P702_MY2021_Rx" SG_ 961 AdbBrdr2Up_An_Rq 1;
BA_ "GenSigStartValue" SG_ 961 AdbBrdr2Up_An_Rq 510;
BA_ "U_P702_MY2021_Rx" SG_ 961 AdbBrdr2Right_An_Rq 1;
BA_ "GenSigStartValue" SG_ 961 AdbBrdr2Right_An_Rq 2046;
BA_ "U_P702_MY2021_Rx" SG_ 961 AdbBrdr2Low_An_Rq 1;
BA_ "GenSigStartValue" SG_ 961 AdbBrdr2Low_An_Rq 510;
BA_ "U_P702_MY2021_Rx" SG_ 961 AdbBrdr2Left_An_Rq 1;
BA_ "GenSigStartValue" SG_ 961 AdbBrdr2Left_An_Rq 2046;
BA_ "U_P702_MY2021_Rx" SG_ 961 AdbBrdr2CritRigh_T_Stat 1;
BA_ "U_P702_MY2021_Rx" SG_ 961 AdbBrdr2CritLeft_T_Stat 1;
BA_ "CrossOver_InfoCAN" SG_ 394 AccTrgDist2_D_Dsply 1;
BA_ "CrossOver_InfoCAN" SG_ 394 AccStopRes_B_Dsply 1;
BA_ "CrossOver_InfoCAN" SG_ 394 FcwDeny_B_Dsply 1;
BA_ "CrossOver_InfoCAN" SG_ 394 FdaWarn_B_Rq 1;
BA_ "CrossOver_InfoCAN" SG_ 394 FcwMemStat_B_Actl 1;
BA_ "CrossOver_InfoCAN" SG_ 394 AccTGap_B_Dsply 1;
BA_ "CrossOver_InfoCAN" SG_ 394 CadsAlignIncplt_B_Actl 1;
BA_ "CrossOver_InfoCAN" SG_ 394 AccLowVMde_B_Dsply 1;
BA_ "CrossOver_InfoCAN" SG_ 394 AccFllwMde_B_Dsply 1;
BA_ "CrossOver_InfoCAN" SG_ 394 CadsRadrBlck_B_Actl 1;
BA_ "CrossOver_InfoCAN" SG_ 394 FdaStat_D_Dsply 1;
BA_ "CrossOver_InfoCAN" SG_ 394 FdaDeny_B_Dsply 1;
BA_ "CrossOver_InfoCAN" SG_ 394 CadsChime_B_Rq 1;
BA_ "CrossOver_InfoCAN" SG_ 394 CmbbPostEvnt_B_Dsply 1;
BA_ "CrossOver_InfoCAN" SG_ 394 FcwCmbbSrvcRqd_B_Rq 1;
BA_ "CrossOver_InfoCAN" SG_ 394 AccStopMde_B_Dsply 1;
BA_ "CrossOver_InfoCAN" SG_ 394 CadsCamraBlck_B_Actl 1;
BA_ "CrossOver_InfoCAN" SG_ 394 FcwMemSens_D_Actl 1;
BA_ "CrossOver_InfoCAN" SG_ 394 FcwMemDfaltOn_B_Actl 1;
BA_ "CrossOver_InfoCAN" SG_ 394 AccSrvcRqd_B_Rq 1;
BA_ "CrossOver_InfoCAN" SG_ 394 FcwMsgTxt_D_Rq 1;
BA_ "CrossOver_InfoCAN" SG_ 394 AccWarn_D_Dsply 1;
BA_ "CrossOver_InfoCAN" SG_ 394 FcwVisblWarn_B_Rq 1;
BA_ "CrossOver_InfoCAN" SG_ 394 FcwAudioWarn_B_Rq 1;
BA_ "CrossOver_InfoCAN" SG_ 394 FcwMemAudioOn_B_Actl 1;
BA_ "GenSigStartValue" SG_ 394 AccTGap_D_Dsply 3;
BA_ "CrossOver_InfoCAN" SG_ 394 AccTGap_D_Dsply 1;
BA_ "GenSigStartValue" SG_ 394 AccMemEnbl_B_RqDrv 1;
BA_ "CrossOver_InfoCAN" SG_ 394 AccMemEnbl_B_RqDrv 1;
BA_ "CrossOver_InfoCAN" SG_ 394 FdaMem_B_Stat 1;
BA_ "MetaData" SG_ 391 CadsRadarStat_D_Qf 1;
BA_ "GenSigStartValue" SG_ 391 CadsRadarStat_D_Qf 1;
BA_ "U_P702_MY2021_Rx" SG_ 391 CmbbBrkDecel_No_Cnt 1;
BA_ "MetaData" SG_ 391 CmbbBrkDecel_No_Cnt 1;
BA_ "CrossOver_InfoCAN" SG_ 391 CadsAudioMute_D_Rq 1;
BA_ "U_P702_MY2021_Rx" SG_ 391 CmbbBrkDecel_No_Cs 1;
BA_ "MetaData" SG_ 391 CmbbBrkDecel_No_Cs 1;
BA_ "U_P702_MY2021_Rx" SG_ 391 CmbbBrkDecel_A_Rq 1;
BA_ "GenSigStartValue" SG_ 391 CmbbBrkDecel_A_Rq 5129;
BA_ "U_P702_MY2021_Rx" SG_ 391 CmbbBrkPrchg_D_Rq 1;
BA_ "U_P702_MY2021_Rx" SG_ 391 CmbbBrkDecel_B_Rq 1;
BA_ "U_P702_MY2021_Rx" SG_ 391 CmbbBaSens_D_Rq 1;
BA_ "U_P702_MY2021_Rx" SG_ 390 AccBrkTot_A_Rq 1;
BA_ "GenSigStartValue" SG_ 390 AccBrkTot_A_Rq 5129;
BA_ "U_P702_MY2021_Rx" SG_ 390 AccPrpl_A_Pred 1;
BA_ "U_P702_MY2021_Rx" SG_ 390 AccVeh_V_Trg 1;
BA_ "U_P702_MY2021_Rx" SG_ 390 AccBrkPrkEl_B_Rq 1;
BA_ "U_P702_MY2021_Rx" SG_ 390 CmbbDeny_B_Actl 1;
BA_ "U_P702_MY2021_Rx" SG_ 390 CmbbEngTqMn_B_Rq 1;
BA_ "U_P702_MY2021_Rx" SG_ 390 AccPrpl_A_Rq 1;
BA_ "U_P702_MY2021_Rx" SG_ 390 AccDeny_B_Rq 1;
BA_ "U_P702_MY2021_Rx" SG_ 390 AccResumEnbl_B_Rq 1;
BA_ "WakeupSignal" SG_ 390 AccResumEnbl_B_Rq 1;
BA_ "U_P702_MY2021_Rx" SG_ 390 AccCancl_B_Rq 1;
BA_ "U_P702_MY2021_Rx" SG_ 390 AccBrkPrchg_B_Rq 1;
BA_ "U_P702_MY2021_Rx" SG_ 390 AccBrkDecel_B_Rq 1;
BA_ "U_P702_MY2021_Rx" SG_ 390 AccStopStat_B_Rq 1;
BA_ "U_P702_MY2021_Tx" SG_ 1441 TCCM_GWOnBoardTester 1;
BA_ "ContentDependant" SG_ 1441 TCCM_GWOnBoardTester 1;
BA_ "GenSigStartValue" SG_ 1441 TCCM_GWOnBoardTester 255;
BA_ "U_P702_MY2021_Tx" SG_ 1441 TCCM_GWNMProxy 1;
BA_ "ContentDependant" SG_ 1441 TCCM_GWNMProxy 1;
BA_ "GenSigStartValue" SG_ 1441 TCCM_GWNMProxy 255;
BA_ "U_P702_MY2021_Tx" SG_ 1441 TCCM_AutoSarNMReserved4 1;
BA_ "ContentDependant" SG_ 1441 TCCM_AutoSarNMReserved4 1;
BA_ "GenSigStartValue" SG_ 1441 TCCM_AutoSarNMReserved4 255;
BA_ "U_P702_MY2021_Tx" SG_ 1441 TCCM_AutoSarNMReserved3 1;
BA_ "ContentDependant" SG_ 1441 TCCM_AutoSarNMReserved3 1;
BA_ "GenSigStartValue" SG_ 1441 TCCM_AutoSarNMReserved3 255;
BA_ "U_P702_MY2021_Tx" SG_ 1441 TCCM_AutoSarNMReserved2 1;
BA_ "ContentDependant" SG_ 1441 TCCM_AutoSarNMReserved2 1;
BA_ "GenSigStartValue" SG_ 1441 TCCM_AutoSarNMReserved2 255;
BA_ "U_P702_MY2021_Tx" SG_ 1441 TCCM_AutoSarNMReserved1 1;
BA_ "ContentDependant" SG_ 1441 TCCM_AutoSarNMReserved1 1;
BA_ "GenSigStartValue" SG_ 1441 TCCM_AutoSarNMReserved1 255;
BA_ "U_P702_MY2021_Tx" SG_ 1441 TCCM_AutoSarNMNodeId 1;
BA_ "ContentDependant" SG_ 1441 TCCM_AutoSarNMNodeId 1;
BA_ "GenSigStartValue" SG_ 1441 TCCM_AutoSarNMNodeId 161;
BA_ "U_P702_MY2021_Tx" SG_ 1441 TCCM_AutoSarNMControl 1;
BA_ "ContentDependant" SG_ 1441 TCCM_AutoSarNMControl 1;
BA_ "U_P702_MY2021_Tx" SG_ 1186 SelDrvMdeAwd2_D_Stat 1;
BA_ "GenSigStartValue" SG_ 1186 SelDrvMdeAwd2_D_Stat 31;
BA_ "U_P702_MY2021_Tx" SG_ 1186 RearDiffLckMsg_D_Rq 1;
BA_ "U_P702_MY2021_Tx" SG_ 1186 RearDiffLckLamp_D_Rq 1;
BA_ "U_P702_MY2021_Tx" SG_ 1186 RearDiffLck_Tq_Actl 1;
BA_ "U_P702_MY2021_Rx" SG_ 1186 RearDiffLck_Tq_Actl 1;
BA_ "U_P702_MY2021_Tx" SG_ 1186 RearDiffFalt_D_Stat 1;
BA_ "U_P702_MY2021_Rx" SG_ 1186 RearDiffFalt_D_Stat 1;
BA_ "U_P702_MY2021_Tx" SG_ 1186 LsdSrvcRqd_B_Rq 1;
BA_ "CrossOver_InfoCAN" SG_ 1186 LsdSrvcRqd_B_Rq 1;
BA_ "U_P702_MY2021_Tx" SG_ 611 AwdSys_D_Stat 1;
BA_ "U_P702_MY2021_Rx" SG_ 611 AwdSys_D_Stat 1;
BA_ "U_P702_MY2021_Tx" SG_ 611 AwdStat_D_RqDsply 1;
BA_ "U_P702_MY2021_Rx" SG_ 611 AwdStat_D_RqDsply 1;
BA_ "ContentDependant" SG_ 611 AwdStat_D_RqDsply 1;
BA_ "CrossOver_InfoCAN" SG_ 611 AwdStat_D_RqDsply 1;
BA_ "U_P702_MY2021_Tx" SG_ 611 AwdLck_D_Stat 1;
BA_ "U_P702_MY2021_Rx" SG_ 611 AwdLck_D_Stat 1;
BA_ "CrossOver_InfoCAN" SG_ 611 AwdLck_D_Stat 1;
BA_ "U_P702_MY2021_Tx" SG_ 611 AwdSrvcRqd_B_Rq 1;
BA_ "U_P702_MY2021_Rx" SG_ 611 AwdSrvcRqd_B_Rq 1;
BA_ "ContentDependant" SG_ 611 AwdSrvcRqd_B_Rq 1;
BA_ "CrossOver_InfoCAN" SG_ 611 AwdSrvcRqd_B_Rq 1;
BA_ "U_P702_MY2021_Tx" SG_ 611 NtrlTowAvail_B_Stat 1;
BA_ "U_P702_MY2021_Tx" SG_ 611 AwdLck_Tq_Rq 1;
BA_ "U_P702_MY2021_Rx" SG_ 611 AwdLck_Tq_Rq 1;
BA_ "ContentDependant" SG_ 611 AwdLck_Tq_Rq 1;
BA_ "CrossOver_InfoCAN" SG_ 611 AwdLck_Tq_Rq 1;
BA_ "U_P702_MY2021_Tx" SG_ 611 TrnAout_Tq_RqMx 1;
BA_ "U_P702_MY2021_Rx" SG_ 611 TrnAout_Tq_RqMx 1;
BA_ "GenSigStartValue" SG_ 611 TrnAout_Tq_RqMx 8191;
BA_ "CrossOver_InfoCAN" SG_ 611 TrnAout_Tq_RqMx 1;
BA_ "U_P702_MY2021_Tx" SG_ 611 AwdOffRoadMode_D_Stats 1;
BA_ "CrossOver_InfoCAN" SG_ 611 AwdOffRoadMode_D_Stats 1;
BA_ "U_P702_MY2021_Tx" SG_ 611 AwdLoLamp_D_RqDsply 1;
BA_ "CrossOver_InfoCAN" SG_ 611 AwdLoLamp_D_RqDsply 1;
BA_ "U_P702_MY2021_Tx" SG_ 611 AwdHiLamp_D_RqDsply 1;
BA_ "CrossOver_InfoCAN" SG_ 611 AwdHiLamp_D_RqDsply 1;
BA_ "U_P702_MY2021_Tx" SG_ 611 AwdAutoLamp_D_RqDsply 1;
BA_ "CrossOver_InfoCAN" SG_ 611 AwdAutoLamp_D_RqDsply 1;
BA_ "U_P702_MY2021_Tx" SG_ 611 Awd2wdLamp_D_RqDsply 1;
BA_ "CrossOver_InfoCAN" SG_ 611 Awd2wdLamp_D_RqDsply 1;
BA_ "U_P702_MY2021_Tx" SG_ 611 AwdRnge_D_Actl 1;
BA_ "U_P702_MY2021_Rx" SG_ 611 AwdRnge_D_Actl 1;
BA_ "GenSigStartValue" SG_ 611 AwdRnge_D_Actl 7;
BA_ "CrossOver_InfoCAN" SG_ 611 AwdRnge_D_Actl 1;
BA_ "U_P702_MY2021_Tx" SG_ 1717 PSCM_GWOnBoardTester 1;
BA_ "U_P702_MY2021_Rx" SG_ 1717 PSCM_GWOnBoardTester 1;
BA_ "ContentDependant" SG_ 1717 PSCM_GWOnBoardTester 1;
BA_ "GenSigStartValue" SG_ 1717 PSCM_GWOnBoardTester 255;
BA_ "U_P702_MY2021_Tx" SG_ 1717 PSCM_GWNMProxy 1;
BA_ "U_P702_MY2021_Rx" SG_ 1717 PSCM_GWNMProxy 1;
BA_ "ContentDependant" SG_ 1717 PSCM_GWNMProxy 1;
BA_ "GenSigStartValue" SG_ 1717 PSCM_GWNMProxy 255;
BA_ "U_P702_MY2021_Tx" SG_ 1717 PSCM_AutoSarNMReserved4 1;
BA_ "U_P702_MY2021_Rx" SG_ 1717 PSCM_AutoSarNMReserved4 1;
BA_ "ContentDependant" SG_ 1717 PSCM_AutoSarNMReserved4 1;
BA_ "GenSigStartValue" SG_ 1717 PSCM_AutoSarNMReserved4 255;
BA_ "U_P702_MY2021_Tx" SG_ 1717 PSCM_AutoSarNMReserved3 1;
BA_ "U_P702_MY2021_Rx" SG_ 1717 PSCM_AutoSarNMReserved3 1;
BA_ "ContentDependant" SG_ 1717 PSCM_AutoSarNMReserved3 1;
BA_ "GenSigStartValue" SG_ 1717 PSCM_AutoSarNMReserved3 255;
BA_ "U_P702_MY2021_Tx" SG_ 1717 PSCM_AutoSarNMReserved2 1;
BA_ "ContentDependant" SG_ 1717 PSCM_AutoSarNMReserved2 1;
BA_ "GenSigStartValue" SG_ 1717 PSCM_AutoSarNMReserved2 255;
BA_ "U_P702_MY2021_Tx" SG_ 1717 PSCM_AutoSarNMReserved1 1;
BA_ "ContentDependant" SG_ 1717 PSCM_AutoSarNMReserved1 1;
BA_ "GenSigStartValue" SG_ 1717 PSCM_AutoSarNMReserved1 255;
BA_ "U_P702_MY2021_Tx" SG_ 1717 PSCM_AutoSarNMNodeId 1;
BA_ "ContentDependant" SG_ 1717 PSCM_AutoSarNMNodeId 1;
BA_ "GenSigStartValue" SG_ 1717 PSCM_AutoSarNMNodeId 181;
BA_ "U_P702_MY2021_Tx" SG_ 1717 PSCM_AutoSarNMControl 1;
BA_ "ContentDependant" SG_ 1717 PSCM_AutoSarNMControl 1;
BA_ "U_P702_MY2021_Tx" SG_ 1303 TrlrAnOffst_An2_Calc 1;
BA_ "GenSigStartValue" SG_ 1303 TrlrAnOffst_An2_Calc 128;
BA_ "U_P702_MY2021_Tx" SG_ 1303 TrlrAn_An_WarnCalc 1;
BA_ "U_P702_MY2021_Tx" SG_ 1303 TrlrAn_An_MxCalc 1;
BA_ "U_P702_MY2021_Tx" SG_ 1303 TrlrAidTrlrId_No_Rq 1;
BA_ "U_P702_MY2021_Tx" SG_ 1303 TrlrAidTrgtId_No_Rq 1;
BA_ "U_P702_MY2021_Tx" SG_ 1303 TrlrAidSetup_D2_Stat 1;
BA_ "U_P702_MY2021_Tx" SG_ 1303 TrlrAidEnbl_D2_Stat 1;
BA_ "U_P702_MY2021_Rx" SG_ 1303 TrlrAidEnbl_D2_Stat 1;
BA_ "GenSigSendType" SG_ 1303 TrlrAidEnbl_D2_Stat 3;
BA_ "U_P702_MY2021_Tx" SG_ 1303 TrlrAidMsgTxt_D2_Rq 1;
BA_ "GenSigSendType" SG_ 1303 TrlrAidMsgTxt_D2_Rq 3;
BA_ "U_P702_MY2021_Tx" SG_ 1303 EsaOn_B_Stat 1;
BA_ "GenSigStartValue" SG_ 1303 EsaOn_B_Stat 1;
BA_ "GenSigSendType" SG_ 1303 EsaOn_B_Stat 3;
BA_ "U_P702_MY2021_Tx" SG_ 1303 LatCtlSte_D_Stat 1;
BA_ "GenSigSendType" SG_ 1303 LatCtlSte_D_Stat 3;
BA_ "U_P702_MY2021_Tx" SG_ 1303 LatCtlLim_D_Stat 1;
BA_ "GenSigSendType" SG_ 1303 LatCtlLim_D_Stat 3;
BA_ "U_P702_MY2021_Tx" SG_ 1303 HitchToTrlrAxle_L_Calc 1;
BA_ "U_P702_MY2021_Tx" SG_ 1303 SelDrvMdeSte_D_Stat 1;
BA_ "GenSigSendType" SG_ 1303 SelDrvMdeSte_D_Stat 3;
BA_ "U_P702_MY2021_Tx" SG_ 1228 TrlrAn_An_TrgtCalc 1;
BA_ "GenSigStartValue" SG_ 1228 TrlrAn_An_TrgtCalc 128;
BA_ "U_P702_MY2021_Tx" SG_ 1228 LsmcBrkDecelEnbl_D_Rq 1;
BA_ "U_P702_MY2021_Rx" SG_ 1228 LsmcBrkDecelEnbl_D_Rq 1;
BA_ "U_P702_MY2021_Tx" SG_ 1228 TjaHandsOnCnfdnc_B_Est 1;
BA_ "GenSigStartValue" SG_ 1228 TjaHandsOnCnfdnc_B_Est 1;
BA_ "U_P702_MY2021_Tx" SG_ 1228 LaHandsOff_B_Actl 1;
BA_ "GenSigStartValue" SG_ 1228 LaHandsOff_B_Actl 1;
BA_ "CrossOver_InfoCAN" SG_ 1228 LaHandsOff_B_Actl 1;
BA_ "U_P702_MY2021_Tx" SG_ 1228 LaActDeny_B_Actl 1;
BA_ "CrossOver_InfoCAN" SG_ 1228 LaActDeny_B_Actl 1;
BA_ "U_P702_MY2021_Tx" SG_ 1228 LaActAvail_D_Actl 1;
BA_ "CrossOver_InfoCAN" SG_ 1228 LaActAvail_D_Actl 1;
BA_ "U_P702_MY2021_Tx" SG_ 1228 LsmcBrk_Tq_Rq 1;
BA_ "U_P702_MY2021_Rx" SG_ 1228 LsmcBrk_Tq_Rq 1;
BA_ "U_P702_MY2021_Tx" SG_ 386 TrlrHitchLamp_D_Rqst 1;
BA_ "CrossOver_InfoCAN" SG_ 386 TrlrHitchLamp_D_Rqst 1;
BA_ "U_P702_MY2021_Tx" SG_ 386 VehVTrlrAid_B_Rq 1;
BA_ "U_P702_MY2021_Rx" SG_ 386 VehVTrlrAid_B_Rq 1;
BA_ "CrossOver_InfoCAN" SG_ 386 VehVTrlrAid_B_Rq 1;
BA_ "U_P702_MY2021_Tx" SG_ 386 Veh_V_RqMxTrlrAid 1;
BA_ "U_P702_MY2021_Rx" SG_ 386 Veh_V_RqMxTrlrAid 1;
BA_ "GenSigStartValue" SG_ 386 Veh_V_RqMxTrlrAid 255;
BA_ "U_P702_MY2021_Tx" SG_ 386 DrvSteActv_B_Stat 1;
BA_ "U_P702_MY2021_Rx" SG_ 386 DrvSteActv_B_Stat 1;
BA_ "U_P702_MY2021_Tx" SG_ 386 DrvSte_Tq_Actl 1;
BA_ "U_P702_MY2021_Rx" SG_ 386 DrvSte_Tq_Actl 1;
BA_ "GenSigStartValue" SG_ 386 DrvSte_Tq_Actl 128;
BA_ "U_P702_MY2021_Tx" SG_ 386 SteMdule_D_Stat 1;
BA_ "U_P702_MY2021_Tx" SG_ 386 SteMdule_U_Meas 1;
BA_ "GenSigStartValue" SG_ 386 SteMdule_U_Meas 255;
BA_ "U_P702_MY2021_Tx" SG_ 386 SteMdule_I_Est 1;
BA_ "GenSigStartValue" SG_ 386 SteMdule_I_Est 4095;
BA_ "U_P702_MY2021_Tx" SG_ 386 EPAS_Failure 1;
BA_ "CrossOver_InfoCAN" SG_ 386 EPAS_Failure 1;
BA_ "U_P702_MY2021_Tx" SG_ 386 SteeringColumnTorque 1;
BA_ "GenSigStartValue" SG_ 386 SteeringColumnTorque 254;
BA_ "U_P702_MY2021_Tx" SG_ 386 SAPPAngleControlStat6 1;
BA_ "U_P702_MY2021_Tx" SG_ 386 SAPPAngleControlStat5 1;
BA_ "U_P702_MY2021_Tx" SG_ 386 SAPPAngleControlStat4 1;
BA_ "U_P702_MY2021_Tx" SG_ 386 SAPPAngleControlStat3 1;
BA_ "U_P702_MY2021_Tx" SG_ 386 SAPPAngleControlStat2 1;
BA_ "U_P702_MY2021_Tx" SG_ 386 SAPPAngleControlStat1 1;
BA_ "U_P702_MY2021_Tx" SG_ 382 StePw_B_Rq 1;
BA_ "U_P702_MY2021_Rx" SG_ 382 StePw_B_Rq 1;
BA_ "U_P702_MY2021_Tx" SG_ 382 StePinRelInit_An_Sns 1;
BA_ "U_P702_MY2021_Rx" SG_ 382 StePinRelInit_An_Sns 1;
BA_ "ContentDependant" SG_ 382 StePinRelInit_An_Sns 1;
BA_ "GenSigStartValue" SG_ 382 StePinRelInit_An_Sns 65535;
BA_ "U_P702_MY2021_Tx" SG_ 382 StePinCompAnEst_D_Qf 1;
BA_ "U_P702_MY2021_Rx" SG_ 382 StePinCompAnEst_D_Qf 1;
BA_ "GenSigStartValue" SG_ 382 StePinCompAnEst_D_Qf 1;
BA_ "CrossOver_InfoCAN" SG_ 382 StePinCompAnEst_D_Qf 1;
BA_ "U_P702_MY2021_Tx" SG_ 382 StePinComp_An_Est 1;
BA_ "U_P702_MY2021_Rx" SG_ 382 StePinComp_An_Est 1;
BA_ "GenSigStartValue" SG_ 382 StePinComp_An_Est 16000;
BA_ "U_P702_MY2021_Tx" SG_ 382 StePinAn_No_Cs 1;
BA_ "U_P702_MY2021_Rx" SG_ 382 StePinAn_No_Cs 1;
BA_ "MetaData" SG_ 382 StePinAn_No_Cs 1;
BA_ "ContentDependant" SG_ 382 StePinAn_No_Cs 1;
BA_ "U_P702_MY2021_Tx" SG_ 382 StePinAn_No_Cnt 1;
BA_ "U_P702_MY2021_Rx" SG_ 382 StePinAn_No_Cnt 1;
BA_ "MetaData" SG_ 382 StePinAn_No_Cnt 1;
BA_ "CrossOver_InfoCAN" SG_ 382 StePinAn_No_Cnt 1;
BA_ "U_P702_MY2021_Tx" SG_ 1430 ABS_GWOnBoardTester 1;
BA_ "ContentDependant" SG_ 1430 ABS_GWOnBoardTester 1;
BA_ "GenSigStartValue" SG_ 1430 ABS_GWOnBoardTester 255;
BA_ "U_P702_MY2021_Tx" SG_ 1430 ABS_GWNMProxy 1;
BA_ "ContentDependant" SG_ 1430 ABS_GWNMProxy 1;
BA_ "GenSigStartValue" SG_ 1430 ABS_GWNMProxy 255;
BA_ "U_P702_MY2021_Tx" SG_ 1430 ABS_AutoSarNMReserved4 1;
BA_ "ContentDependant" SG_ 1430 ABS_AutoSarNMReserved4 1;
BA_ "GenSigStartValue" SG_ 1430 ABS_AutoSarNMReserved4 255;
BA_ "U_P702_MY2021_Tx" SG_ 1430 ABS_AutoSarNMReserved3 1;
BA_ "ContentDependant" SG_ 1430 ABS_AutoSarNMReserved3 1;
BA_ "GenSigStartValue" SG_ 1430 ABS_AutoSarNMReserved3 255;
BA_ "U_P702_MY2021_Tx" SG_ 1430 ABS_AutoSarNMReserved2 1;
BA_ "ContentDependant" SG_ 1430 ABS_AutoSarNMReserved2 1;
BA_ "GenSigStartValue" SG_ 1430 ABS_AutoSarNMReserved2 255;
BA_ "U_P702_MY2021_Tx" SG_ 1430 ABS_AutoSarNMReserved1 1;
BA_ "ContentDependant" SG_ 1430 ABS_AutoSarNMReserved1 1;
BA_ "GenSigStartValue" SG_ 1430 ABS_AutoSarNMReserved1 255;
BA_ "U_P702_MY2021_Tx" SG_ 1430 ABS_AutoSarNMNodeId 1;
BA_ "ContentDependant" SG_ 1430 ABS_AutoSarNMNodeId 1;
BA_ "GenSigStartValue" SG_ 1430 ABS_AutoSarNMNodeId 150;
BA_ "U_P702_MY2021_Tx" SG_ 1430 ABS_AutoSarNMControl 1;
BA_ "ContentDependant" SG_ 1430 ABS_AutoSarNMControl 1;
BA_ "U_P702_MY2021_Tx" SG_ 1200 HsaTrnAout_Tq_Rq 1;
BA_ "GenSigStartValue" SG_ 1200 HsaTrnAout_Tq_Rq 32768;
BA_ "U_P702_MY2021_Tx" SG_ 1200 BrkBstrVac_P_Actl 1;
BA_ "U_P702_MY2021_Rx" SG_ 1200 BrkBstrVac_P_Actl 1;
BA_ "GenSigStartValue" SG_ 1200 BrkBstrVac_P_Actl 127;
BA_ "U_P702_MY2021_Tx" SG_ 1200 YawStabilityIndex 1;
BA_ "U_P702_MY2021_Rx" SG_ 1200 YawStabilityIndex 1;
BA_ "GenSigStartValue" SG_ 1200 YawStabilityIndex 256;
BA_ "U_P702_MY2021_Tx" SG_ 1200 BrkTot_Tq_RqDrv 1;
BA_ "U_P702_MY2021_Rx" SG_ 1200 BrkTot_Tq_RqDrv 1;
BA_ "U_P702_MY2021_Tx" SG_ 1200 BrkTotTqRqDrv_No_Cnt 1;
BA_ "U_P702_MY2021_Rx" SG_ 1200 BrkTotTqRqDrv_No_Cnt 1;
BA_ "MetaData" SG_ 1200 BrkTotTqRqDrv_No_Cnt 1;
BA_ "U_P702_MY2021_Tx" SG_ 1200 BrkTotTqRqDrv_No_Cs 1;
BA_ "U_P702_MY2021_Rx" SG_ 1200 BrkTotTqRqDrv_No_Cs 1;
BA_ "MetaData" SG_ 1200 BrkTotTqRqDrv_No_Cs 1;
BA_ "U_P702_MY2021_Tx" SG_ 1200 BrkAutoHold_D_Stat 1;
BA_ "U_P702_MY2021_Rx" SG_ 1200 BrkAutoHold_D_Stat 1;
BA_ "U_P702_MY2021_Tx" SG_ 1200 HsaStat_D_Dsply 1;
BA_ "U_P702_MY2021_Tx" SG_ 1102 SelDrvMdePos12_D_Stat 1;
BA_ "GenSigStartValue" SG_ 1102 SelDrvMdePos12_D_Stat 31;
BA_ "GenSigSendType" SG_ 1102 SelDrvMdePos12_D_Stat 3;
BA_ "U_P702_MY2021_Tx" SG_ 1102 SelDrvMdePos11_D_Stat 1;
BA_ "GenSigStartValue" SG_ 1102 SelDrvMdePos11_D_Stat 31;
BA_ "GenSigSendType" SG_ 1102 SelDrvMdePos11_D_Stat 3;
BA_ "U_P702_MY2021_Tx" SG_ 1102 SelDrvMdePos10_D_Stat 1;
BA_ "GenSigStartValue" SG_ 1102 SelDrvMdePos10_D_Stat 31;
BA_ "GenSigSendType" SG_ 1102 SelDrvMdePos10_D_Stat 3;
BA_ "U_P702_MY2021_Tx" SG_ 1102 SelDrvMdePos09_D_Stat 1;
BA_ "GenSigStartValue" SG_ 1102 SelDrvMdePos09_D_Stat 31;
BA_ "GenSigSendType" SG_ 1102 SelDrvMdePos09_D_Stat 3;
BA_ "U_P702_MY2021_Tx" SG_ 1102 SelDrvMdePos08_D_Stat 1;
BA_ "GenSigStartValue" SG_ 1102 SelDrvMdePos08_D_Stat 31;
BA_ "GenSigSendType" SG_ 1102 SelDrvMdePos08_D_Stat 3;
BA_ "U_P702_MY2021_Tx" SG_ 1102 SelDrvMdePos07_D_Stat 1;
BA_ "GenSigStartValue" SG_ 1102 SelDrvMdePos07_D_Stat 31;
BA_ "GenSigSendType" SG_ 1102 SelDrvMdePos07_D_Stat 3;
BA_ "U_P702_MY2021_Tx" SG_ 1102 SelDrvMdePos06_D_Stat 1;
BA_ "GenSigStartValue" SG_ 1102 SelDrvMdePos06_D_Stat 31;
BA_ "GenSigSendType" SG_ 1102 SelDrvMdePos06_D_Stat 3;
BA_ "U_P702_MY2021_Tx" SG_ 1102 SelDrvMdePos05_D_Stat 1;
BA_ "GenSigStartValue" SG_ 1102 SelDrvMdePos05_D_Stat 31;
BA_ "GenSigSendType" SG_ 1102 SelDrvMdePos05_D_Stat 3;
BA_ "U_P702_MY2021_Tx" SG_ 1102 SelDrvMdePos04_D_Stat 1;
BA_ "GenSigStartValue" SG_ 1102 SelDrvMdePos04_D_Stat 31;
BA_ "GenSigSendType" SG_ 1102 SelDrvMdePos04_D_Stat 3;
BA_ "U_P702_MY2021_Tx" SG_ 1102 SelDrvMdePos03_D_Stat 1;
BA_ "GenSigStartValue" SG_ 1102 SelDrvMdePos03_D_Stat 31;
BA_ "GenSigSendType" SG_ 1102 SelDrvMdePos03_D_Stat 3;
BA_ "U_P702_MY2021_Tx" SG_ 1102 SelDrvMdePos02_D_Stat 1;
BA_ "GenSigStartValue" SG_ 1102 SelDrvMdePos02_D_Stat 31;
BA_ "GenSigSendType" SG_ 1102 SelDrvMdePos02_D_Stat 3;
BA_ "U_P702_MY2021_Tx" SG_ 1102 SelDrvMdePos01_D_Stat 1;
BA_ "GenSigStartValue" SG_ 1102 SelDrvMdePos01_D_Stat 31;
BA_ "GenSigSendType" SG_ 1102 SelDrvMdePos01_D_Stat 3;
BA_ "U_P702_MY2021_Tx" SG_ 1056 SelDrvMdePos12_B_Avail 1;
BA_ "GenSigSendType" SG_ 1056 SelDrvMdePos12_B_Avail 3;
BA_ "U_P702_MY2021_Tx" SG_ 1056 SelDrvMdePos11_B_Avail 1;
BA_ "GenSigSendType" SG_ 1056 SelDrvMdePos11_B_Avail 3;
BA_ "U_P702_MY2021_Tx" SG_ 1056 SelDrvMdePos10_B_Avail 1;
BA_ "GenSigSendType" SG_ 1056 SelDrvMdePos10_B_Avail 3;
BA_ "U_P702_MY2021_Tx" SG_ 1056 SelDrvMdePos09_B_Avail 1;
BA_ "GenSigSendType" SG_ 1056 SelDrvMdePos09_B_Avail 3;
BA_ "U_P702_MY2021_Tx" SG_ 1056 SelDrvMdePos08_B_Avail 1;
BA_ "GenSigSendType" SG_ 1056 SelDrvMdePos08_B_Avail 3;
BA_ "U_P702_MY2021_Tx" SG_ 1056 SelDrvMdePos07_B_Avail 1;
BA_ "GenSigSendType" SG_ 1056 SelDrvMdePos07_B_Avail 3;
BA_ "U_P702_MY2021_Tx" SG_ 1056 SelDrvMdePos06_B_Avail 1;
BA_ "GenSigSendType" SG_ 1056 SelDrvMdePos06_B_Avail 3;
BA_ "U_P702_MY2021_Tx" SG_ 1056 SelDrvMdePos05_B_Avail 1;
BA_ "GenSigSendType" SG_ 1056 SelDrvMdePos05_B_Avail 3;
BA_ "U_P702_MY2021_Tx" SG_ 1056 SelDrvMdePos04_B_Avail 1;
BA_ "GenSigSendType" SG_ 1056 SelDrvMdePos04_B_Avail 3;
BA_ "U_P702_MY2021_Tx" SG_ 1056 SelDrvMdePos03_B_Avail 1;
BA_ "GenSigSendType" SG_ 1056 SelDrvMdePos03_B_Avail 3;
BA_ "U_P702_MY2021_Tx" SG_ 1056 SelDrvMdePos02_B_Avail 1;
BA_ "GenSigSendType" SG_ 1056 SelDrvMdePos02_B_Avail 3;
BA_ "U_P702_MY2021_Tx" SG_ 1056 SelDrvMdePos01_B_Avail 1;
BA_ "GenSigSendType" SG_ 1056 SelDrvMdePos01_B_Avail 3;
BA_ "U_P702_MY2021_Tx" SG_ 1056 ActvDrvMde_D2_Stat 1;
BA_ "GenSigStartValue" SG_ 1056 ActvDrvMde_D2_Stat 31;
BA_ "GenSigSendType" SG_ 1056 ActvDrvMde_D2_Stat 3;
BA_ "U_P702_MY2021_Tx" SG_ 1056 SelDrvMde_D2_Rq 1;
BA_ "GenSigStartValue" SG_ 1056 SelDrvMde_D2_Rq 31;
BA_ "GenSigSendType" SG_ 1056 SelDrvMde_D2_Rq 3;
BA_ "U_P702_MY2021_Tx" SG_ 1056 SelDrvMdePt_D_Rq 1;
BA_ "U_P702_MY2021_Rx" SG_ 1056 SelDrvMdePt_D_Rq 1;
BA_ "GenSigSendType" SG_ 1056 SelDrvMdePt_D_Rq 3;
BA_ "U_P702_MY2021_Tx" SG_ 1056 SelDrvMdeMsgTxt_D_Rq 1;
BA_ "GenSigSendType" SG_ 1056 SelDrvMdeMsgTxt_D_Rq 3;
BA_ "U_P702_MY2021_Tx" SG_ 1056 SelDrvMde_D_Stat 1;
BA_ "GenSigSendType" SG_ 1056 SelDrvMde_D_Stat 3;
BA_ "U_P702_MY2021_Tx" SG_ 1056 AwdMde_D_RqBrk 1;
BA_ "GenSigStartValue" SG_ 1056 AwdMde_D_RqBrk 5;
BA_ "GenSigSendType" SG_ 1056 AwdMde_D_RqBrk 3;
BA_ "GenSigSendType" SG_ 1054 TrailCtlMsgTxt_D_Rq 3;
BA_ "U_CX727_MY2021_Tx" SG_ 1054 TrailCtlMsgTxt_D_Rq 1;
BA_ "U_CX727_MY2021_Tx" SG_ 1054 TrailCtl_D_Stat 1;
BA_ "U_P702_MY2021_Rx" SG_ 1054 TrailCtl_D_Stat 1;
BA_ "GenSigSendType" SG_ 1054 TrailCtl_D_Stat 3;
BA_ "U_P702_MY2021_Tx" SG_ 1054 RbaBrk_D_Stat 1;
BA_ "GenSigSendType" SG_ 1054 RbaBrk_D_Stat 3;
BA_ "U_P702_MY2021_Tx" SG_ 1054 SelDrvMdeChassis2_D_Rq 1;
BA_ "U_P702_MY2021_Rx" SG_ 1054 SelDrvMdeChassis2_D_Rq 1;
BA_ "GenSigSendType" SG_ 1054 SelDrvMdeChassis2_D_Rq 3;
BA_ "U_P702_MY2021_Tx" SG_ 1054 BrkBstrVac_D_Stat 1;
BA_ "U_P702_MY2021_Rx" SG_ 1054 BrkBstrVac_D_Stat 1;
BA_ "GenSigSendType" SG_ 1054 BrkBstrVac_D_Stat 3;
BA_ "U_P702_MY2021_Tx" SG_ 1054 DrvSlipCtlOffLamp_D_Rq 1;
BA_ "GenSigSendType" SG_ 1054 DrvSlipCtlOffLamp_D_Rq 3;
BA_ "U_P702_MY2021_Tx" SG_ 1054 DrvSlipCtlMdeMsg_D_Rq 1;
BA_ "GenSigSendType" SG_ 1054 DrvSlipCtlMdeMsg_D_Rq 3;
BA_ "U_P702_MY2021_Tx" SG_ 1054 AutoHoldMsgTxt_D_Rq 1;
BA_ "GenSigSendType" SG_ 1054 AutoHoldMsgTxt_D_Rq 3;
BA_ "U_P702_MY2021_Tx" SG_ 1054 CtaBrk_D_Stat 1;
BA_ "GenSigSendType" SG_ 1054 CtaBrk_D_Stat 3;
BA_ "U_P702_MY2021_Tx" SG_ 1054 SelDrvMdeAwd_D_Rq 1;
BA_ "U_P702_MY2021_Rx" SG_ 1054 SelDrvMdeAwd_D_Rq 1;
BA_ "GenSigStartValue" SG_ 1054 SelDrvMdeAwd_D_Rq 31;
BA_ "GenSigSendType" SG_ 1054 SelDrvMdeAwd_D_Rq 3;
BA_ "U_P702_MY2021_Tx" SG_ 1054 AutoHoldSwMde_B_Ind 1;
BA_ "ContentDependant" SG_ 1054 AutoHoldSwMde_B_Ind 1;
BA_ "CrossOver_InfoCAN" SG_ 1054 AutoHoldSwMde_B_Ind 1;
BA_ "GenSigSendType" SG_ 1054 AutoHoldSwMde_B_Ind 3;
BA_ "U_P702_MY2021_Tx" SG_ 1054 AutoHoldMde_D_Ind 1;
BA_ "GenSigSendType" SG_ 1054 AutoHoldMde_D_Ind 3;
BA_ "U_P702_MY2021_Tx" SG_ 1054 BrkMdeInhbt_B_RqDsply 1;
BA_ "CrossOver_InfoCAN" SG_ 1054 BrkMdeInhbt_B_RqDsply 1;
BA_ "WakeupSignal" SG_ 1054 BrkMdeInhbt_B_RqDsply 1;
BA_ "GenSigSendType" SG_ 1054 BrkMdeInhbt_B_RqDsply 3;
BA_ "U_P702_MY2021_Tx" SG_ 1054 SelDrvMdeChassis_D_Rq 1;
BA_ "GenSigSendType" SG_ 1054 SelDrvMdeChassis_D_Rq 3;
BA_ "U_P702_MY2021_Tx" SG_ 1054 ApaBrk_D_Stat 1;
BA_ "U_P702_MY2021_Rx" SG_ 1054 ApaBrk_D_Stat 1;
BA_ "GenSigSendType" SG_ 1054 ApaBrk_D_Stat 3;
BA_ "U_P702_MY2021_Tx" SG_ 1046 HsaMde_D_Mem 1;
BA_ "GenSigStartValue" SG_ 1046 HsaMde_D_Mem 1;
BA_ "CrossOver_InfoCAN" SG_ 1046 HsaMde_D_Mem 1;
BA_ "U_P702_MY2021_Tx" SG_ 1046 BrkBstrVac_B_Rq 1;
BA_ "U_P702_MY2021_Rx" SG_ 1046 BrkBstrVac_B_Rq 1;
BA_ "CrossOver_InfoCAN" SG_ 1046 BrkBstrVac_B_Rq 1;
BA_ "U_P702_MY2021_Tx" SG_ 1046 HdcMde_D_Actl 1;
BA_ "CrossOver_InfoCAN" SG_ 1046 HdcMde_D_Actl 1;
BA_ "U_P702_MY2021_Tx" SG_ 1046 RearDiffLck_Tq2_RqMx 1;
BA_ "U_P702_MY2021_Rx" SG_ 1046 RearDiffLck_Tq2_RqMx 1;
BA_ "GenSigStartValue" SG_ 1046 RearDiffLck_Tq2_RqMx 4094;
BA_ "U_P702_MY2021_Tx" SG_ 1046 TRLR_SWAY_EVNT_IN_PROG 1;
BA_ "U_P702_MY2021_Tx" SG_ 1046 TRLR_SWAY_CONFIG_STAT 1;
BA_ "U_P702_MY2021_Tx" SG_ 1046 TCMode 1;
BA_ "U_P702_MY2021_Rx" SG_ 1046 TCMode 1;
BA_ "ContentDependant" SG_ 1046 TCMode 1;
BA_ "CrossOver_InfoCAN" SG_ 1046 TCMode 1;
BA_ "U_P702_MY2021_Tx" SG_ 1046 DrvSlipCtlLamp_D_Rq 1;
BA_ "U_P702_MY2021_Rx" SG_ 1046 DrvSlipCtlLamp_D_Rq 1;
BA_ "CrossOver_InfoCAN" SG_ 1046 DrvSlipCtlLamp_D_Rq 1;
BA_ "U_P702_MY2021_Tx" SG_ 1046 Abs_B_Falt 1;
BA_ "U_P702_MY2021_Rx" SG_ 1046 Abs_B_Falt 1;
BA_ "CrossOver_InfoCAN" SG_ 1046 Abs_B_Falt 1;
BA_ "U_P702_MY2021_Tx" SG_ 1046 DrvSlipCtlMde_D_Ind 1;
BA_ "U_P702_MY2021_Rx" SG_ 1046 DrvSlipCtlMde_D_Ind 1;
BA_ "CrossOver_InfoCAN" SG_ 1046 DrvSlipCtlMde_D_Ind 1;
BA_ "U_P702_MY2021_Tx" SG_ 1046 BpedMove_No_Cs 1;
BA_ "U_P702_MY2021_Rx" SG_ 1046 BpedMove_No_Cs 1;
BA_ "MetaData" SG_ 1046 BpedMove_No_Cs 1;
BA_ "CrossOver_InfoCAN" SG_ 1046 BpedMove_No_Cs 1;
BA_ "U_P702_MY2021_Tx" SG_ 1046 DrvAntiLckLamp_D_Rq 1;
BA_ "U_P702_MY2021_Rx" SG_ 1046 DrvAntiLckLamp_D_Rq 1;
BA_ "CrossOver_InfoCAN" SG_ 1046 DrvAntiLckLamp_D_Rq 1;
BA_ "U_P702_MY2021_Tx" SG_ 1046 BpedMove_No_Cnt 1;
BA_ "U_P702_MY2021_Rx" SG_ 1046 BpedMove_No_Cnt 1;
BA_ "MetaData" SG_ 1046 BpedMove_No_Cnt 1;
BA_ "CrossOver_InfoCAN" SG_ 1046 BpedMove_No_Cnt 1;
BA_ "U_P702_MY2021_Tx" SG_ 1046 StabCtlBrk_B_Avail 1;
BA_ "GenSigStartValue" SG_ 1046 StabCtlBrk_B_Avail 1;
BA_ "CrossOver_InfoCAN" SG_ 1046 StabCtlBrk_B_Avail 1;
BA_ "U_P702_MY2021_Tx" SG_ 1046 DrvHdcWarnInfo_D_Rq 1;
BA_ "CrossOver_InfoCAN" SG_ 1046 DrvHdcWarnInfo_D_Rq 1;
BA_ "U_P702_MY2021_Tx" SG_ 1046 DrvHdcMsg_D_Rq 1;
BA_ "CrossOver_InfoCAN" SG_ 1046 DrvHdcMsg_D_Rq 1;
BA_ "U_P702_MY2021_Tx" SG_ 1046 DrvHdcLampInfo_D_Rq 1;
BA_ "CrossOver_InfoCAN" SG_ 1046 DrvHdcLampInfo_D_Rq 1;
BA_ "U_P702_MY2021_Tx" SG_ 1046 BpedMove_D_Actl 1;
BA_ "U_P702_MY2021_Rx" SG_ 1046 BpedMove_D_Actl 1;
BA_ "GenSigStartValue" SG_ 1046 BpedMove_D_Actl 3;
BA_ "CrossOver_InfoCAN" SG_ 1046 BpedMove_D_Actl 1;
BA_ "U_P702_MY2021_Tx" SG_ 1046 ChimeBrk_B_Rq 1;
BA_ "CrossOver_InfoCAN" SG_ 1046 ChimeBrk_B_Rq 1;
BA_ "U_P702_MY2021_Tx" SG_ 1046 BrkLamp_B_Rq 1;
BA_ "CrossOver_InfoCAN" SG_ 1046 BrkLamp_B_Rq 1;
BA_ "U_P702_MY2021_Tx" SG_ 1046 HILL_DESC_MC 1;
BA_ "CrossOver_InfoCAN" SG_ 1046 HILL_DESC_MC 1;
BA_ "U_P702_MY2021_Tx" SG_ 1045 VehStab_D_Stat 1;
BA_ "GenSigStartValue" SG_ 1045 VehStab_D_Stat 14;
BA_ "U_P702_MY2021_Tx" SG_ 1045 BrkFluidLvl_D_Stat 1;
BA_ "U_P702_MY2021_Tx" SG_ 1045 LsmcBrkDecel_D_Stat 1;
BA_ "U_P702_MY2021_Rx" SG_ 1045 LsmcBrkDecel_D_Stat 1;
BA_ "U_P702_MY2021_Tx" SG_ 1045 VehYawNonLin_W_Rq 1;
BA_ "U_P702_MY2021_Rx" SG_ 1045 VehYawNonLin_W_Rq 1;
BA_ "GenSigStartValue" SG_ 1045 VehYawNonLin_W_Rq 4094;
BA_ "CrossOver_InfoCAN" SG_ 1045 VehYawNonLin_W_Rq 1;
BA_ "U_P702_MY2021_Tx" SG_ 1045 VehYawLin_W_Rq 1;
BA_ "U_P702_MY2021_Rx" SG_ 1045 VehYawLin_W_Rq 1;
BA_ "GenSigStartValue" SG_ 1045 VehYawLin_W_Rq 4094;
BA_ "CrossOver_InfoCAN" SG_ 1045 VehYawLin_W_Rq 1;
BA_ "U_P702_MY2021_Tx" SG_ 1045 VehVActlBrk_No_Cs 1;
BA_ "U_P702_MY2021_Rx" SG_ 1045 VehVActlBrk_No_Cs 1;
BA_ "MetaData" SG_ 1045 VehVActlBrk_No_Cs 1;
BA_ "CrossOver_InfoCAN" SG_ 1045 VehVActlBrk_No_Cs 1;
BA_ "U_P702_MY2021_Tx" SG_ 1045 Veh_V_ActlBrk 1;
BA_ "U_P702_MY2021_Rx" SG_ 1045 Veh_V_ActlBrk 1;
BA_ "CrossOver_InfoCAN" SG_ 1045 Veh_V_ActlBrk 1;
BA_ "U_P702_MY2021_Tx" SG_ 1045 VehVActlBrk_No_Cnt 1;
BA_ "U_P702_MY2021_Rx" SG_ 1045 VehVActlBrk_No_Cnt 1;
BA_ "MetaData" SG_ 1045 VehVActlBrk_No_Cnt 1;
BA_ "CrossOver_InfoCAN" SG_ 1045 VehVActlBrk_No_Cnt 1;
BA_ "U_P702_MY2021_Tx" SG_ 1045 VehVActlBrk_D_Qf 1;
BA_ "U_P702_MY2021_Rx" SG_ 1045 VehVActlBrk_D_Qf 1;
BA_ "MetaData" SG_ 1045 VehVActlBrk_D_Qf 1;
BA_ "CrossOver_InfoCAN" SG_ 1045 VehVActlBrk_D_Qf 1;
BA_ "U_P702_MY2021_Tx" SG_ 1044 StePinOffst_An_Est 1;
BA_ "U_P702_MY2021_Rx" SG_ 1044 StePinOffst_An_Est 1;
BA_ "ContentDependant" SG_ 1044 StePinOffst_An_Est 1;
BA_ "GenSigStartValue" SG_ 1044 StePinOffst_An_Est 65534;
BA_ "U_P702_MY2021_Tx" SG_ 1044 StePinOffst_No_Cs 1;
BA_ "U_P702_MY2021_Rx" SG_ 1044 StePinOffst_No_Cs 1;
BA_ "MetaData" SG_ 1044 StePinOffst_No_Cs 1;
BA_ "ContentDependant" SG_ 1044 StePinOffst_No_Cs 1;
BA_ "U_P702_MY2021_Tx" SG_ 1044 StePinOffst_No_Cnt 1;
BA_ "U_P702_MY2021_Rx" SG_ 1044 StePinOffst_No_Cnt 1;
BA_ "MetaData" SG_ 1044 StePinOffst_No_Cnt 1;
BA_ "CrossOver_InfoCAN" SG_ 1044 StePinOffst_No_Cnt 1;
BA_ "U_P702_MY2021_Tx" SG_ 1044 StePinOffst_D_Stat 1;
BA_ "U_P702_MY2021_Rx" SG_ 1044 StePinOffst_D_Stat 1;
BA_ "U_P702_MY2021_Tx" SG_ 1042 VehRol_An_Dsply 1;
BA_ "GenSigStartValue" SG_ 1042 VehRol_An_Dsply 64;
BA_ "U_P702_MY2021_Tx" SG_ 1042 VehPtch_An_Dsply 1;
BA_ "GenSigStartValue" SG_ 1042 VehPtch_An_Dsply 64;
BA_ "U_P702_MY2021_Tx" SG_ 1042 TrlrBrk_Pc_Rq 1;
BA_ "U_P702_MY2021_Tx" SG_ 535 WhlRr_W_Meas 1;
BA_ "U_P702_MY2021_Rx" SG_ 535 WhlRr_W_Meas 1;
BA_ "U_P702_MY2021_Tx" SG_ 535 WhlRl_W_Meas 1;
BA_ "U_P702_MY2021_Rx" SG_ 535 WhlRl_W_Meas 1;
BA_ "U_P702_MY2021_Tx" SG_ 535 WhlFr_W_Meas 1;
BA_ "U_P702_MY2021_Rx" SG_ 535 WhlFr_W_Meas 1;
BA_ "U_P702_MY2021_Tx" SG_ 535 WhlFl_W_Meas 1;
BA_ "U_P702_MY2021_Rx" SG_ 535 WhlFl_W_Meas 1;
BA_ "U_P702_MY2021_Tx" SG_ 534 BrkObdData_No_Actl 1;
BA_ "ContentDependant" SG_ 534 BrkObdData_No_Actl 1;
BA_ "U_P702_MY2021_Tx" SG_ 534 BrkObdIndex_No_Actl 1;
BA_ "ContentDependant" SG_ 534 BrkObdIndex_No_Actl 1;
BA_ "U_P702_MY2021_Tx" SG_ 534 WhlRotatRr_No_Cnt 1;
BA_ "CrossOver_InfoCAN" SG_ 534 WhlRotatRr_No_Cnt 1;
BA_ "U_P702_MY2021_Tx" SG_ 534 WhlDirRr_D_Actl 1;
BA_ "U_P702_MY2021_Rx" SG_ 534 WhlDirRr_D_Actl 1;
BA_ "CrossOver_InfoCAN" SG_ 534 WhlDirRr_D_Actl 1;
BA_ "U_P702_MY2021_Tx" SG_ 534 WhlDirRl_D_Actl 1;
BA_ "U_P702_MY2021_Rx" SG_ 534 WhlDirRl_D_Actl 1;
BA_ "CrossOver_InfoCAN" SG_ 534 WhlDirRl_D_Actl 1;
BA_ "U_P702_MY2021_Tx" SG_ 534 WhlDirFr_D_Actl 1;
BA_ "U_P702_MY2021_Rx" SG_ 534 WhlDirFr_D_Actl 1;
BA_ "CrossOver_InfoCAN" SG_ 534 WhlDirFr_D_Actl 1;
BA_ "U_P702_MY2021_Tx" SG_ 534 WhlDirFl_D_Actl 1;
BA_ "U_P702_MY2021_Rx" SG_ 534 WhlDirFl_D_Actl 1;
BA_ "CrossOver_InfoCAN" SG_ 534 WhlDirFl_D_Actl 1;
BA_ "U_P702_MY2021_Tx" SG_ 534 WhlRotatRl_No_Cnt 1;
BA_ "CrossOver_InfoCAN" SG_ 534 WhlRotatRl_No_Cnt 1;
BA_ "U_P702_MY2021_Tx" SG_ 534 WhlRotatFr_No_Cnt 1;
BA_ "U_P702_MY2021_Rx" SG_ 534 WhlRotatFr_No_Cnt 1;
BA_ "CrossOver_InfoCAN" SG_ 534 WhlRotatFr_No_Cnt 1;
BA_ "U_P702_MY2021_Tx" SG_ 534 WhlRotatFl_No_Cnt 1;
BA_ "U_P702_MY2021_Rx" SG_ 534 WhlRotatFl_No_Cnt 1;
BA_ "CrossOver_InfoCAN" SG_ 534 WhlRotatFl_No_Cnt 1;
BA_ "U_P702_MY2021_Tx" SG_ 532 RgenTqFalt_B_Actl 1;
BA_ "U_P702_MY2021_Rx" SG_ 532 RgenTqFalt_B_Actl 1;
BA_ "U_P702_MY2021_Tx" SG_ 532 RgenBrkDynoMde_B_Actl 1;
BA_ "U_P702_MY2021_Rx" SG_ 532 RgenBrkDynoMde_B_Actl 1;
BA_ "U_P702_MY2021_Tx" SG_ 532 PrplWhlTqRqMn_No_Cs 1;
BA_ "U_P702_MY2021_Rx" SG_ 532 PrplWhlTqRqMn_No_Cs 1;
BA_ "MetaData" SG_ 532 PrplWhlTqRqMn_No_Cs 1;
BA_ "U_P702_MY2021_Tx" SG_ 532 PrplWhlRear_Tq_RqMx 1;
BA_ "U_P702_MY2021_Tx" SG_ 532 PrplWhlTot_Tq_RqMn 1;
BA_ "U_P702_MY2021_Rx" SG_ 532 PrplWhlTot_Tq_RqMn 1;
BA_ "U_P702_MY2021_Tx" SG_ 532 PrplWhlTqRqMn_No_Cnt 1;
BA_ "U_P702_MY2021_Rx" SG_ 532 PrplWhlTqRqMn_No_Cnt 1;
BA_ "MetaData" SG_ 532 PrplWhlTqRqMn_No_Cnt 1;
BA_ "U_P702_MY2021_Tx" SG_ 532 PrplWhlRear_Tq_RqMn 1;
BA_ "U_P702_MY2021_Tx" SG_ 531 VehStop_D_Stat 1;
BA_ "GenSigStartValue" SG_ 531 VehStop_D_Stat 2;
BA_ "U_P702_MY2021_Tx" SG_ 531 TracCtlPtActv_B_Actl 1;
BA_ "U_P702_MY2021_Rx" SG_ 531 TracCtlPtActv_B_Actl 1;
BA_ "CrossOver_InfoCAN" SG_ 531 TracCtlPtActv_B_Actl 1;
BA_ "U_P702_MY2021_Tx" SG_ 531 LscmbbMntr_B_Err 1;
BA_ "CrossOver_InfoCAN" SG_ 531 LscmbbMntr_B_Err 1;
BA_ "U_P702_MY2021_Tx" SG_ 531 LscmbbBrkDis_B_Actl 1;
BA_ "CrossOver_InfoCAN" SG_ 531 LscmbbBrkDis_B_Actl 1;
BA_ "U_P702_MY2021_Tx" SG_ 531 LscmbbDeny_B_ActlBrk 1;
BA_ "CrossOver_InfoCAN" SG_ 531 LscmbbDeny_B_ActlBrk 1;
BA_ "U_P702_MY2021_Tx" SG_ 531 PrkBrkYwLamp_D_Rq 1;
BA_ "CrossOver_InfoCAN" SG_ 531 PrkBrkYwLamp_D_Rq 1;
BA_ "WakeupSignal" SG_ 531 PrkBrkYwLamp_D_Rq 1;
BA_ "U_P702_MY2021_Tx" SG_ 531 PrkBrkRedLamp_D_Rq 1;
BA_ "CrossOver_InfoCAN" SG_ 531 PrkBrkRedLamp_D_Rq 1;
BA_ "WakeupSignal" SG_ 531 PrkBrkRedLamp_D_Rq 1;
BA_ "U_P702_MY2021_Tx" SG_ 531 VehicleStationary 1;
BA_ "CrossOver_InfoCAN" SG_ 531 VehicleStationary 1;
BA_ "U_P702_MY2021_Tx" SG_ 531 LscmbbBrkDecel_B_Actl 1;
BA_ "CrossOver_InfoCAN" SG_ 531 LscmbbBrkDecel_B_Actl 1;
BA_ "U_P702_MY2021_Tx" SG_ 531 AbsActv_B_Actl 1;
BA_ "U_P702_MY2021_Rx" SG_ 531 AbsActv_B_Actl 1;
BA_ "CrossOver_InfoCAN" SG_ 531 AbsActv_B_Actl 1;
BA_ "U_P702_MY2021_Tx" SG_ 531 StabCtlBrkActv_B_Actl 1;
BA_ "U_P702_MY2021_Rx" SG_ 531 StabCtlBrkActv_B_Actl 1;
BA_ "CrossOver_InfoCAN" SG_ 531 StabCtlBrkActv_B_Actl 1;
BA_ "U_P702_MY2021_Tx" SG_ 531 CmbbBrkPrchg_B_Actl 1;
BA_ "CrossOver_InfoCAN" SG_ 531 CmbbBrkPrchg_B_Actl 1;
BA_ "U_P702_MY2021_Tx" SG_ 531 CmbbBrkDecel_B_Actl 1;
BA_ "CrossOver_InfoCAN" SG_ 531 CmbbBrkDecel_B_Actl 1;
BA_ "U_P702_MY2021_Tx" SG_ 531 CmbbBaSensInc_B_Actl 1;
BA_ "CrossOver_InfoCAN" SG_ 531 CmbbBaSensInc_B_Actl 1;
BA_ "U_P702_MY2021_Tx" SG_ 531 AccBrkWarm_B_Actl 1;
BA_ "CrossOver_InfoCAN" SG_ 531 AccBrkWarm_B_Actl 1;
BA_ "U_P702_MY2021_Tx" SG_ 531 AccBrkTotTqMn_B_Actl 1;
BA_ "CrossOver_InfoCAN" SG_ 531 AccBrkTotTqMn_B_Actl 1;
BA_ "U_P702_MY2021_Tx" SG_ 531 AccBrkPrchgActv_B_Actl 1;
BA_ "CrossOver_InfoCAN" SG_ 531 AccBrkPrchgActv_B_Actl 1;
BA_ "U_P702_MY2021_Tx" SG_ 531 AccBrkDis_B_Actl 1;
BA_ "CrossOver_InfoCAN" SG_ 531 AccBrkDis_B_Actl 1;
BA_ "U_P702_MY2021_Tx" SG_ 531 AccBrkDeny_B_Actl 1;
BA_ "U_P702_MY2021_Rx" SG_ 531 AccBrkDeny_B_Actl 1;
BA_ "CrossOver_InfoCAN" SG_ 531 AccBrkDeny_B_Actl 1;
BA_ "U_P702_MY2021_Tx" SG_ 531 AccBrkActv_B_Actl 1;
BA_ "U_P702_MY2021_Rx" SG_ 531 AccBrkActv_B_Actl 1;
BA_ "CrossOver_InfoCAN" SG_ 531 AccBrkActv_B_Actl 1;
BA_ "U_P702_MY2021_Tx" SG_ 531 PrplDrgCtlActv_B_Actl 1;
BA_ "U_P702_MY2021_Rx" SG_ 531 PrplDrgCtlActv_B_Actl 1;
BA_ "CrossOver_InfoCAN" SG_ 531 PrplDrgCtlActv_B_Actl 1;
BA_ "U_P702_MY2021_Tx" SG_ 531 PrplWhlTot_Tq_RqMx 1;
BA_ "U_P702_MY2021_Rx" SG_ 531 PrplWhlTot_Tq_RqMx 1;
BA_ "CrossOver_InfoCAN" SG_ 531 PrplWhlTot_Tq_RqMx 1;
BA_ "U_P702_MY2021_Tx" SG_ 531 LscmbbBaSensInc_B_Actl 1;
BA_ "CrossOver_InfoCAN" SG_ 531 LscmbbBaSensInc_B_Actl 1;
BA_ "U_P702_MY2021_Tx" SG_ 531 CmbbBrkDis_B_Actl 1;
BA_ "U_P702_MY2021_Rx" SG_ 531 CmbbBrkDis_B_Actl 1;
BA_ "CrossOver_InfoCAN" SG_ 531 CmbbBrkDis_B_Actl 1;
BA_ "U_P702_MY2021_Tx" SG_ 531 CmbbDeny_B_ActlBrk 1;
BA_ "U_P702_MY2021_Rx" SG_ 531 CmbbDeny_B_ActlBrk 1;
BA_ "CrossOver_InfoCAN" SG_ 531 CmbbDeny_B_ActlBrk 1;
BA_ "U_P702_MY2021_Tx" SG_ 531 CcDis_B_Cmd 1;
BA_ "U_P702_MY2021_Rx" SG_ 531 CcDis_B_Cmd 1;
BA_ "CrossOver_InfoCAN" SG_ 531 CcDis_B_Cmd 1;
BA_ "U_P702_MY2021_Tx" SG_ 531 VehLongOvrGnd_A_Est 1;
BA_ "U_P702_MY2021_Rx" SG_ 531 VehLongOvrGnd_A_Est 1;
BA_ "GenSigStartValue" SG_ 531 VehLongOvrGnd_A_Est 511;
BA_ "CrossOver_InfoCAN" SG_ 531 VehLongOvrGnd_A_Est 1;
BA_ "U_P702_MY2021_Tx" SG_ 531 LscmbBrkPrchg_B_Actl 1;
BA_ "CrossOver_InfoCAN" SG_ 531 LscmbBrkPrchg_B_Actl 1;
BA_ "U_P702_MY2021_Tx" SG_ 531 AccStopActv_B_ActlBrk 1;
BA_ "U_P702_MY2021_Rx" SG_ 531 AccStopActv_B_ActlBrk 1;
BA_ "CrossOver_InfoCAN" SG_ 531 AccStopActv_B_ActlBrk 1;
BA_ "U_P702_MY2021_Tx" SG_ 531 AccDis_B_ActlEpb 1;
BA_ "CrossOver_InfoCAN" SG_ 531 AccDis_B_ActlEpb 1;
BA_ "U_P702_MY2021_Tx" SG_ 531 PrkBrkMsgTxt_D_Rq 1;
BA_ "CrossOver_InfoCAN" SG_ 531 PrkBrkMsgTxt_D_Rq 1;
BA_ "WakeupSignal" SG_ 531 PrkBrkMsgTxt_D_Rq 1;
BA_ "U_P702_MY2021_Tx" SG_ 531 PrkBrkStatus 1;
BA_ "U_P702_MY2021_Rx" SG_ 531 PrkBrkStatus 1;
BA_ "GenSigStartValue" SG_ 531 PrkBrkStatus 7;
BA_ "CrossOver_InfoCAN" SG_ 531 PrkBrkStatus 1;
BA_ "U_P702_MY2021_Tx" SG_ 136 SteWhlBrkOffst_An_Rq 1;
BA_ "GenSigStartValue" SG_ 136 SteWhlBrkOffst_An_Rq 32766;
BA_ "U_P702_MY2021_Tx" SG_ 136 SteWhlBrkAnRq_No_Cs 1;
BA_ "MetaData" SG_ 136 SteWhlBrkAnRq_No_Cs 1;
BA_ "CrossOver_InfoCAN" SG_ 136 SteWhlBrkAnRq_No_Cs 1;
BA_ "U_P702_MY2021_Tx" SG_ 136 SteWhlBrkAnRq_No_Cnt 1;
BA_ "MetaData" SG_ 136 SteWhlBrkAnRq_No_Cnt 1;
BA_ "CrossOver_InfoCAN" SG_ 136 SteWhlBrkAnRq_No_Cnt 1;
BA_ "U_P702_MY2021_Tx" SG_ 127 AwdLatDelta_Tq_Rq 1;
BA_ "GenSigStartValue" SG_ 127 AwdLatDelta_Tq_Rq 1;
BA_ "U_P702_MY2021_Tx" SG_ 127 AwdLatDelta_B_Rq 1;
BA_ "U_P702_MY2021_Tx" SG_ 127 AwdLck_Tq_RqMx 1;
BA_ "U_P702_MY2021_Rx" SG_ 127 AwdLck_Tq_RqMx 1;
BA_ "U_P702_MY2021_Tx" SG_ 127 AwdLck_Tq_RqMn 1;
BA_ "U_P702_MY2021_Rx" SG_ 127 AwdLck_Tq_RqMn 1;
BA_ "U_P702_MY2021_Tx" SG_ 125 VehRolComp_W_Actl 1;
BA_ "GenSigStartValue" SG_ 125 VehRolComp_W_Actl 4094;
BA_ "U_P702_MY2021_Tx" SG_ 125 VehVertComp_A_Actl 1;
BA_ "GenSigStartValue" SG_ 125 VehVertComp_A_Actl 1022;
BA_ "U_P702_MY2021_Tx" SG_ 125 BrkTotTqRqArb_No_Cs 1;
BA_ "U_P702_MY2021_Rx" SG_ 125 BrkTotTqRqArb_No_Cs 1;
BA_ "MetaData" SG_ 125 BrkTotTqRqArb_No_Cs 1;
BA_ "U_P702_MY2021_Tx" SG_ 125 BrkTotTqRqArb_No_Cnt 1;
BA_ "U_P702_MY2021_Rx" SG_ 125 BrkTotTqRqArb_No_Cnt 1;
BA_ "MetaData" SG_ 125 BrkTotTqRqArb_No_Cnt 1;
BA_ "U_P702_MY2021_Tx" SG_ 125 BrkTot_Tq_RqArb 1;
BA_ "U_P702_MY2021_Rx" SG_ 125 BrkTot_Tq_RqArb 1;
BA_ "U_P702_MY2021_Tx" SG_ 125 BrkTot_Tq_Actl 1;
BA_ "U_P702_MY2021_Rx" SG_ 125 BrkTot_Tq_Actl 1;
BA_ "U_P702_MY2021_Tx" SG_ 125 HsaStat_D_Actl 1;
BA_ "U_P702_MY2021_Rx" SG_ 125 HsaStat_D_Actl 1;
BA_ "CrossOver_InfoCAN" SG_ 125 HsaStat_D_Actl 1;
BA_ "U_P702_MY2021_Tx" SG_ 119 VehTrvlDir_D_Stat 1;
BA_ "GenSigStartValue" SG_ 119 VehTrvlDir_D_Stat 6;
BA_ "U_P702_MY2021_Tx" SG_ 119 VehOverGnd_V_Est 1;
BA_ "U_P702_MY2021_Rx" SG_ 119 VehOverGnd_V_Est 1;
BA_ "U_P702_MY2021_Tx" SG_ 119 VehLongComp_A_Actl 1;
BA_ "U_P702_MY2021_Rx" SG_ 119 VehLongComp_A_Actl 1;
BA_ "GenSigStartValue" SG_ 119 VehLongComp_A_Actl 1022;
BA_ "U_P702_MY2021_Tx" SG_ 119 VehLatComp_A_Actl 1;
BA_ "U_P702_MY2021_Rx" SG_ 119 VehLatComp_A_Actl 1;
BA_ "GenSigStartValue" SG_ 119 VehLatComp_A_Actl 1022;
BA_ "U_P702_MY2021_Tx" SG_ 119 VehYawComp_W_Actl 1;
BA_ "U_P702_MY2021_Rx" SG_ 119 VehYawComp_W_Actl 1;
BA_ "GenSigStartValue" SG_ 119 VehYawComp_W_Actl 4094;
BA_ "CrossOver_InfoCAN" SG_ 119 VehYawComp_W_Actl 1;
BA_ "U_P702_MY2021_Tx" SG_ 118 BrkCtrFnd_B_Stat 1;
BA_ "GenSigSendType" SG_ 118 BrkCtrFnd_B_Stat 3;
BA_ "U_P702_MY2021_Tx" SG_ 118 AwdLck_Tq_RqMx 1;
BA_ "U_P702_MY2021_Rx" SG_ 118 AwdLck_Tq_RqMx 1;
BA_ "U_P702_MY2021_Tx" SG_ 118 AwdLck_Tq_RqMn 1;
BA_ "U_P702_MY2021_Rx" SG_ 118 AwdLck_Tq_RqMn 1;
BA_ "U_P702_MY2021_Tx" SG_ 118 DrvSte_D_Stat 1;
BA_ "U_P702_MY2021_Rx" SG_ 118 DrvSte_D_Stat 1;
BA_ "GenSigSendType" SG_ 118 DrvSte_D_Stat 3;
BA_ "U_P702_MY2021_Tx" SG_ 118 DrvSte_Tq_Rq 1;
BA_ "U_P702_MY2021_Rx" SG_ 118 DrvSte_Tq_Rq 1;
BA_ "GenSigStartValue" SG_ 118 DrvSte_Tq_Rq 128;
BA_ "U_P702_MY2021_Tx" SG_ 118 EmgcyBrkLamp_D_Rq 1;
BA_ "GenSigSendType" SG_ 118 EmgcyBrkLamp_D_Rq 3;
BA_ "U_P702_MY2021_Tx" SG_ 118 StopLamp_B_RqBrk 1;
BA_ "GenSigSendType" SG_ 118 StopLamp_B_RqBrk 3;
BA_ "U_P702_MY2021_Tx" SG_ 118 SteWhlCompAnEst_D_Qf 1;
BA_ "MetaData" SG_ 118 SteWhlCompAnEst_D_Qf 1;
BA_ "ContentDependant" SG_ 118 SteWhlCompAnEst_D_Qf 1;
BA_ "GenSigSendType" SG_ 118 SteWhlCompAnEst_D_Qf 3;
BA_ "U_P702_MY2021_Tx" SG_ 118 SteWhlComp_An_Est 1;
BA_ "ContentDependant" SG_ 118 SteWhlComp_An_Est 1;
BA_ "U_P702_MY2021_Tx" SG_ 73 immoSubTarget1Data_T1 1;
BA_ "U_P702_MY2021_Rx" SG_ 73 immoSubTarget1Data_T1 1;
BA_ "U_P702_MY2021_Tx" SG_ 73 immoSubTarget1Cmd_T1 1;
BA_ "U_P702_MY2021_Rx" SG_ 73 immoSubTarget1Cmd_T1 1;
BA_ "U_P702_MY2021_Rx" SG_ 1034 VehicleGGCCData 1;
BA_ "CrossOver_InfoCAN" SG_ 1034 VehicleGGCCData 1;
BA_ "U_P702_MY2021_Tx" SG_ 1440 TCM_GWOnBoardTester 1;
BA_ "ContentDependant" SG_ 1440 TCM_GWOnBoardTester 1;
BA_ "GenSigStartValue" SG_ 1440 TCM_GWOnBoardTester 255;
BA_ "U_P702_MY2021_Tx" SG_ 1440 TCM_GWNMProxy 1;
BA_ "ContentDependant" SG_ 1440 TCM_GWNMProxy 1;
BA_ "GenSigStartValue" SG_ 1440 TCM_GWNMProxy 255;
BA_ "U_P702_MY2021_Tx" SG_ 1440 TCM_AutoSarNMReserved4 1;
BA_ "ContentDependant" SG_ 1440 TCM_AutoSarNMReserved4 1;
BA_ "GenSigStartValue" SG_ 1440 TCM_AutoSarNMReserved4 255;
BA_ "U_P702_MY2021_Tx" SG_ 1440 TCM_AutoSarNMReserved3 1;
BA_ "ContentDependant" SG_ 1440 TCM_AutoSarNMReserved3 1;
BA_ "GenSigStartValue" SG_ 1440 TCM_AutoSarNMReserved3 255;
BA_ "U_P702_MY2021_Tx" SG_ 1440 TCM_AutoSarNMReserved2 1;
BA_ "ContentDependant" SG_ 1440 TCM_AutoSarNMReserved2 1;
BA_ "GenSigStartValue" SG_ 1440 TCM_AutoSarNMReserved2 255;
BA_ "U_P702_MY2021_Tx" SG_ 1440 TCM_AutoSarNMReserved1 1;
BA_ "ContentDependant" SG_ 1440 TCM_AutoSarNMReserved1 1;
BA_ "GenSigStartValue" SG_ 1440 TCM_AutoSarNMReserved1 255;
BA_ "U_P702_MY2021_Tx" SG_ 1440 TCM_AutoSarNMNodeId 1;
BA_ "ContentDependant" SG_ 1440 TCM_AutoSarNMNodeId 1;
BA_ "GenSigStartValue" SG_ 1440 TCM_AutoSarNMNodeId 160;
BA_ "U_P702_MY2021_Tx" SG_ 1440 TCM_AutoSarNMControl 1;
BA_ "ContentDependant" SG_ 1440 TCM_AutoSarNMControl 1;
BA_ "U_P702_MY2021_Tx" SG_ 561 TrnMsgTxt2_D_Rq 1;
BA_ "CrossOver_InfoCAN" SG_ 561 TrnMsgTxt2_D_Rq 1;
BA_ "U_P702_MY2021_Tx" SG_ 561 TrnMsgTxt_D_Rq 1;
BA_ "CrossOver_InfoCAN" SG_ 561 TrnMsgTxt_D_Rq 1;
BA_ "U_P702_MY2021_Tx" SG_ 330 TrnAout_W_ActlUnfilt 1;
BA_ "U_P702_MY2021_Rx" SG_ 330 TrnAout_W_ActlUnfilt 1;
BA_ "U_P702_MY2021_Tx" SG_ 869 PwrFlowTxt_D_Dsply 1;
BA_ "U_P702_MY2021_Tx" SG_ 869 EngOnMsg2_D_Dsply 1;
BA_ "U_P702_MY2021_Tx" SG_ 869 EngOnMsg1_D_Dsply 1;
BA_ "U_P702_MY2021_Tx" SG_ 869 EffWhlLvl2_Pc_Dsply 1;
BA_ "GenSigStartValue" SG_ 869 EffWhlLvl2_Pc_Dsply 511;
BA_ "CrossOver_InfoCAN" SG_ 869 EffWhlLvl2_Pc_Dsply 1;
BA_ "U_P702_MY2021_Tx" SG_ 869 EffWhlThres_Pc_Dsply 1;
BA_ "CrossOver_InfoCAN" SG_ 869 EffWhlThres_Pc_Dsply 1;
BA_ "U_P702_MY2021_Tx" SG_ 869 EngPwLvl_Pc_Dsply 1;
BA_ "CrossOver_InfoCAN" SG_ 869 EngPwLvl_Pc_Dsply 1;
BA_ "U_P702_MY2021_Tx" SG_ 869 EngActv_B_Dsply 1;
BA_ "CrossOver_InfoCAN" SG_ 869 EngActv_B_Dsply 1;
BA_ "U_P702_MY2021_Tx" SG_ 869 EffWhlThresOn_B_Dsply 1;
BA_ "CrossOver_InfoCAN" SG_ 869 EffWhlThresOn_B_Dsply 1;
BA_ "U_P702_MY2021_Tx" SG_ 606 ElVehLaterMde_D_Stat 1;
BA_ "GenSigSendType" SG_ 606 ElVehLaterMde_D_Stat 3;
BA_ "U_P702_MY2021_Tx" SG_ 606 ElVehNowMde_D_Stat 1;
BA_ "GenSigSendType" SG_ 606 ElVehNowMde_D_Stat 3;
BA_ "U_P702_MY2021_Tx" SG_ 374 GearEngag_D_Actl 1;
BA_ "GenSigSendType" SG_ 374 GearEngag_D_Actl 3;
BA_ "U_P702_MY2021_Tx" SG_ 374 TrnRng_D_Rq 1;
BA_ "U_P702_MY2021_Rx" SG_ 374 TrnRng_D_Rq 1;
BA_ "ContentDependant" SG_ 374 TrnRng_D_Rq 1;
BA_ "GenSigStartValue" SG_ 374 TrnRng_D_Rq 14;
BA_ "GenSigSendType" SG_ 374 TrnRng_D_Rq 3;
BA_ "U_P702_MY2021_Tx" SG_ 374 TrnPrkSys_D_Actl 1;
BA_ "U_P702_MY2021_Rx" SG_ 374 TrnPrkSys_D_Actl 1;
BA_ "ContentDependant" SG_ 374 TrnPrkSys_D_Actl 1;
BA_ "GenSigSendType" SG_ 374 TrnPrkSys_D_Actl 3;
BA_ "U_P702_MY2021_Tx" SG_ 374 GearLvr_D_ActlDrv 1;
BA_ "U_P702_MY2021_Rx" SG_ 374 GearLvr_D_ActlDrv 1;
BA_ "ContentDependant" SG_ 374 GearLvr_D_ActlDrv 1;
BA_ "GenSigSendType" SG_ 374 GearLvr_D_ActlDrv 3;
BA_ "U_P702_MY2021_Tx" SG_ 374 GearPos_No_Cs 1;
BA_ "U_P702_MY2021_Rx" SG_ 374 GearPos_No_Cs 1;
BA_ "MetaData" SG_ 374 GearPos_No_Cs 1;
BA_ "ContentDependant" SG_ 374 GearPos_No_Cs 1;
BA_ "U_P702_MY2021_Tx" SG_ 374 GearPos_D_Trg 1;
BA_ "U_P702_MY2021_Rx" SG_ 374 GearPos_D_Trg 1;
BA_ "ContentDependant" SG_ 374 GearPos_D_Trg 1;
BA_ "GenSigStartValue" SG_ 374 GearPos_D_Trg 15;
BA_ "CrossOver_InfoCAN" SG_ 374 GearPos_D_Trg 1;
BA_ "GenSigSendType" SG_ 374 GearPos_D_Trg 3;
BA_ "U_P702_MY2021_Tx" SG_ 374 GearPos_No_Cnt 1;
BA_ "U_P702_MY2021_Rx" SG_ 374 GearPos_No_Cnt 1;
BA_ "MetaData" SG_ 374 GearPos_No_Cnt 1;
BA_ "ContentDependant" SG_ 374 GearPos_No_Cnt 1;
BA_ "U_P702_MY2021_Tx" SG_ 374 TrnIgnOffDly_T_Rq 1;
BA_ "U_P702_MY2021_Tx" SG_ 374 GearPos_D_Actl 1;
BA_ "U_P702_MY2021_Rx" SG_ 374 GearPos_D_Actl 1;
BA_ "ContentDependant" SG_ 374 GearPos_D_Actl 1;
BA_ "GenSigStartValue" SG_ 374 GearPos_D_Actl 15;
BA_ "GenSigSendType" SG_ 374 GearPos_D_Actl 3;
BA_ "U_P702_MY2021_Tx" SG_ 603 WhlDirAvgDrv_D_Actl 1;
BA_ "ContentDependant" SG_ 603 WhlDirAvgDrv_D_Actl 1;
BA_ "U_P702_MY2021_Tx" SG_ 603 PrplTqMnRgen_B_Actl 1;
BA_ "ContentDependant" SG_ 603 PrplTqMnRgen_B_Actl 1;
BA_ "U_P702_MY2021_Tx" SG_ 603 BattTracCnnct_D_Rq 1;
BA_ "ContentDependant" SG_ 603 BattTracCnnct_D_Rq 1;
BA_ "U_P702_MY2021_Tx" SG_ 602 HtrnWarnLamp_B_Dsply 1;
BA_ "CrossOver_InfoCAN" SG_ 602 HtrnWarnLamp_B_Dsply 1;
BA_ "U_P702_MY2021_Tx" SG_ 602 HybPwLimOn_B_Stat 1;
BA_ "U_P702_MY2021_Tx" SG_ 602 PwPckTqRdy_B_Dsply 1;
BA_ "CrossOver_InfoCAN" SG_ 602 PwPckTqRdy_B_Dsply 1;
BA_ "U_P702_MY2021_Tx" SG_ 1152 GrdAsstActv_B_Stat 1;
BA_ "U_P702_MY2021_Tx" SG_ 1152 EngTeHi_B_Actl 1;
BA_ "GenSigSendType" SG_ 1152 EngTeHi_B_Actl 3;
BA_ "U_P702_MY2021_Tx" SG_ 1152 DcdcOn_B_Rq 1;
BA_ "GenSigSendType" SG_ 1152 DcdcOn_B_Rq 3;
BA_ "U_P702_MY2021_Tx" SG_ 1152 ULoBattSpprtSustn_B_Rq 1;
BA_ "GenSigSendType" SG_ 1152 ULoBattSpprtSustn_B_Rq 3;
BA_ "U_P702_MY2021_Tx" SG_ 1152 VehElEff_No_Avg 1;
BA_ "GenSigStartValue" SG_ 1152 VehElEff_No_Avg 126;
BA_ "U_P702_MY2021_Tx" SG_ 560 SelDrvMdeSwtch_D_Stat3 1;
BA_ "U_P702_MY2021_Rx" SG_ 560 SelDrvMdeSwtch_D_Stat3 1;
BA_ "ContentDependant" SG_ 560 SelDrvMdeSwtch_D_Stat3 1;
BA_ "U_P702_MY2021_Tx" SG_ 560 TrnSrvcRqd_B_Rq 1;
BA_ "ContentDependant" SG_ 560 TrnSrvcRqd_B_Rq 1;
BA_ "CrossOver_InfoCAN" SG_ 560 TrnSrvcRqd_B_Rq 1;
BA_ "U_P702_MY2021_Tx" SG_ 560 TrnShifActv_B_Actl 1;
BA_ "U_P702_MY2021_Rx" SG_ 560 TrnShifActv_B_Actl 1;
BA_ "ContentDependant" SG_ 560 TrnShifActv_B_Actl 1;
BA_ "U_P702_MY2021_Tx" SG_ 560 GearLvrPos_D_Actl 1;
BA_ "U_P702_MY2021_Rx" SG_ 560 GearLvrPos_D_Actl 1;
BA_ "GenSigStartValue" SG_ 560 GearLvrPos_D_Actl 14;
BA_ "CrossOver_InfoCAN" SG_ 560 GearLvrPos_D_Actl 1;
BA_ "U_P702_MY2021_Tx" SG_ 560 GboxOil_Te_Actl 1;
BA_ "U_P702_MY2021_Rx" SG_ 560 GboxOil_Te_Actl 1;
BA_ "ContentDependant" SG_ 560 GboxOil_Te_Actl 1;
BA_ "GenSigStartValue" SG_ 560 GboxOil_Te_Actl 254;
BA_ "U_P702_MY2021_Tx" SG_ 369 TrnIpcDsplyRng2_D_Actl 1;
BA_ "GenSigStartValue" SG_ 369 TrnIpcDsplyRng2_D_Actl 15;
BA_ "U_P702_MY2021_Tx" SG_ 369 TrnIpcDsplyRng_D_Stat 1;
BA_ "U_P702_MY2021_Tx" SG_ 369 TrnIpcDsplyGear_D_Actl 1;
BA_ "GenSigStartValue" SG_ 369 TrnIpcDsplyGear_D_Actl 15;
BA_ "CrossOver_InfoCAN" SG_ 369 TrnIpcDsplyGear_D_Actl 1;
BA_ "U_P702_MY2021_Tx" SG_ 369 TrnIpcDsplyMde_D_Stat 1;
BA_ "CrossOver_InfoCAN" SG_ 369 TrnIpcDsplyMde_D_Stat 1;
BA_ "WakeupSignal" SG_ 369 TrnIpcDsplyMde_D_Stat 1;
BA_ "U_P702_MY2021_Tx" SG_ 369 TrnIpcDsplyMde_D_Actl 1;
BA_ "CrossOver_InfoCAN" SG_ 369 TrnIpcDsplyMde_D_Actl 1;
BA_ "WakeupSignal" SG_ 369 TrnIpcDsplyMde_D_Actl 1;
BA_ "U_P702_MY2021_Tx" SG_ 369 TrnIpcDsplyGear_D_Stat 1;
BA_ "CrossOver_InfoCAN" SG_ 369 TrnIpcDsplyGear_D_Stat 1;
BA_ "U_P702_MY2021_Tx" SG_ 92 TrnLvrV_D_Rq 1;
BA_ "GenSigStartValue" SG_ 92 TrnLvrV_D_Rq 1;
BA_ "GenSigSendType" SG_ 92 TrnLvrV_D_Rq 3;
BA_ "U_P702_MY2021_Tx" SG_ 92 TrnSbwSysHlth_D_Actl 1;
BA_ "ContentDependant" SG_ 92 TrnSbwSysHlth_D_Actl 1;
BA_ "GenSigStartValue" SG_ 92 TrnSbwSysHlth_D_Actl 1;
BA_ "GenSigSendType" SG_ 92 TrnSbwSysHlth_D_Actl 3;
BA_ "U_P702_MY2021_Tx" SG_ 92 TrnGearNtmAllow_B_Stat 1;
BA_ "ContentDependant" SG_ 92 TrnGearNtmAllow_B_Stat 1;
BA_ "CrossOver_InfoCAN" SG_ 92 TrnGearNtmAllow_B_Stat 1;
BA_ "GenSigSendType" SG_ 92 TrnGearNtmAllow_B_Stat 3;
BA_ "U_P702_MY2021_Tx" SG_ 92 TrnDtpCmd_D_Actl 1;
BA_ "ContentDependant" SG_ 92 TrnDtpCmd_D_Actl 1;
BA_ "GenSigStartValue" SG_ 92 TrnDtpCmd_D_Actl 1;
BA_ "WakeupSignal" SG_ 92 TrnDtpCmd_D_Actl 1;
BA_ "GenSigSendType" SG_ 92 TrnDtpCmd_D_Actl 3;
BA_ "U_P702_MY2021_Tx" SG_ 92 GearSelLck_D_Rq 1;
BA_ "GenSigSendType" SG_ 92 GearSelLck_D_Rq 3;
BA_ "U_P702_MY2021_Tx" SG_ 92 TrnGearCmd_No_Cs 1;
BA_ "MetaData" SG_ 92 TrnGearCmd_No_Cs 1;
BA_ "ContentDependant" SG_ 92 TrnGearCmd_No_Cs 1;
BA_ "U_P702_MY2021_Tx" SG_ 92 TrnValidGear_D_Cnfm 1;
BA_ "ContentDependant" SG_ 92 TrnValidGear_D_Cnfm 1;
BA_ "GenSigSendType" SG_ 92 TrnValidGear_D_Cnfm 3;
BA_ "U_P702_MY2021_Tx" SG_ 92 TrnNtrlTowCmd_D_Actl 1;
BA_ "U_P702_MY2021_Rx" SG_ 92 TrnNtrlTowCmd_D_Actl 1;
BA_ "ContentDependant" SG_ 92 TrnNtrlTowCmd_D_Actl 1;
BA_ "GenSigSendType" SG_ 92 TrnNtrlTowCmd_D_Actl 3;
BA_ "U_P702_MY2021_Tx" SG_ 92 TrnGearCmd_Pc_ActlPt 1;
BA_ "ContentDependant" SG_ 92 TrnGearCmd_Pc_ActlPt 1;
BA_ "U_P702_MY2021_Tx" SG_ 92 TrnGear_D_RqPt 1;
BA_ "ContentDependant" SG_ 92 TrnGear_D_RqPt 1;
BA_ "GenSigSendType" SG_ 92 TrnGear_D_RqPt 3;
BA_ "U_P702_MY2021_Tx" SG_ 92 TrnCmdState_B_Actl 1;
BA_ "ContentDependant" SG_ 92 TrnCmdState_B_Actl 1;
BA_ "GenSigSendType" SG_ 92 TrnCmdState_B_Actl 3;
BA_ "U_P702_MY2021_Tx" SG_ 92 TrnCmdCnt_B_Actl 1;
BA_ "ContentDependant" SG_ 92 TrnCmdCnt_B_Actl 1;
BA_ "U_P702_MY2021_Tx" SG_ 92 PrkBrkActv_D_RqTrnGear 1;
BA_ "U_P702_MY2021_Rx" SG_ 92 PrkBrkActv_D_RqTrnGear 1;
BA_ "ContentDependant" SG_ 92 PrkBrkActv_D_RqTrnGear 1;
BA_ "GenSigStartValue" SG_ 92 PrkBrkActv_D_RqTrnGear 1;
BA_ "GenSigSendType" SG_ 92 PrkBrkActv_D_RqTrnGear 3;
BA_ "U_P702_MY2021_Tx" SG_ 92 TrnGearMsgTxt_D_Rq 1;
BA_ "ContentDependant" SG_ 92 TrnGearMsgTxt_D_Rq 1;
BA_ "CrossOver_InfoCAN" SG_ 92 TrnGearMsgTxt_D_Rq 1;
BA_ "GenSigSendType" SG_ 92 TrnGearMsgTxt_D_Rq 3;
BA_ "U_P702_MY2021_Tx" SG_ 92 TrnGearCmd_No_Cnt 1;
BA_ "MetaData" SG_ 92 TrnGearCmd_No_Cnt 1;
BA_ "ContentDependant" SG_ 92 TrnGearCmd_No_Cnt 1;
BA_ "GenSigSendType" SG_ 1087 FapLcInhbt_B_Rq 3;
BA_ "U_P702_MY2021_Tx" SG_ 1087 FapLcStopHold_B_Rq 1;
BA_ "U_P702_MY2021_Rx" SG_ 1087 FapLcStopHold_B_Rq 1;
BA_ "GenSigSendType" SG_ 1087 FapLcStopHold_B_Rq 3;
BA_ "U_P702_MY2021_Tx" SG_ 1087 FapLcPrchgBrk_B_Rq 1;
BA_ "U_P702_MY2021_Rx" SG_ 1087 FapLcPrchgBrk_B_Rq 1;
BA_ "GenSigSendType" SG_ 1087 FapLcPrchgBrk_B_Rq 3;
BA_ "U_P702_MY2021_Tx" SG_ 1087 FapLcObstcl_B_Stat 1;
BA_ "GenSigSendType" SG_ 1087 FapLcObstcl_B_Stat 3;
BA_ "U_P702_MY2021_Tx" SG_ 1087 FapLcMaxGrdInhbt_B_Stat 1;
BA_ "GenSigSendType" SG_ 1087 FapLcMaxGrdInhbt_B_Stat 3;
BA_ "U_P702_MY2021_Tx" SG_ 1087 FapLcMaxGrdAbrt_B_Stat 1;
BA_ "GenSigSendType" SG_ 1087 FapLcMaxGrdAbrt_B_Stat 3;
BA_ "U_P702_MY2021_Tx" SG_ 1087 FapLcActv_B_Stat 1;
BA_ "GenSigSendType" SG_ 1087 FapLcActv_B_Stat 3;
BA_ "CrossOver_InfoCAN" SG_ 332 UreaQltySysWarn_D_Rq 1;
BA_ "CrossOver_InfoCAN" SG_ 332 UreaLvlTxtWarn_D_Rq 1;
BA_ "CrossOver_InfoCAN" SG_ 332 UreaLvlQlty_D_RqDsply 1;
BA_ "U_P702_MY2021_Tx" SG_ 332 UreaQltyFlg_B_RqDsply 1;
BA_ "U_P702_MY2021_Tx" SG_ 332 UreaLvl_Pc_Actl 1;
BA_ "U_P702_MY2021_Tx" SG_ 332 VehUreaRnge2_L_DsplyMx 1;
BA_ "U_P702_MY2021_Tx" SG_ 332 UreaQltySys_D_RqDsply 1;
BA_ "CrossOver_InfoCAN" SG_ 332 UreaQltySys_D_RqDsply 1;
BA_ "U_P702_MY2021_Tx" SG_ 332 UreaLvlTxt_D_RqDsply 1;
BA_ "CrossOver_InfoCAN" SG_ 332 UreaLvlTxt_D_RqDsply 1;
BA_ "U_P702_MY2021_Tx" SG_ 332 VehUreaWarn_V_DsplyMx 1;
BA_ "CrossOver_InfoCAN" SG_ 332 VehUreaWarn_V_DsplyMx 1;
BA_ "U_P702_MY2021_Tx" SG_ 1896 TesterPhysicalResABS 1;
BA_ "GenSigSendType" SG_ 1896 TesterPhysicalResABS 3;
BA_ "U_P702_MY2021_Rx" SG_ 1889 TesterPhysicalReqTCCM 1;
BA_ "GenSigSendType" SG_ 1889 TesterPhysicalReqTCCM 3;
BA_ "U_P702_MY2021_Rx" SG_ 1888 TesterPhysicalReqABS 1;
BA_ "GenSigSendType" SG_ 1888 TesterPhysicalReqABS 3;
BA_ "U_P702_MY2021_Tx" SG_ 1631 TesterPhysicalResPSCM 1;
VAL_ 970 LkaDrvOvrrd_D_Rq 3 "Level_3" 2 "Level_2" 1 "Level_1" 0 "Level_0" ;
VAL_ 970 LkaActvStats_D2_Req 7 "NotUsed" 6 "LkaIncrIntervRight" 5 "LkaSupprRight" 4 "LkaStandIntervRight" 3 "LkaSupprLeft" 2 "LkaStandIntervLeft" 1 "LkaIncrIntervLeft" 0 "LkaNoInterv" ;
VAL_ 970 LaRefAng_No_Req 4095 "Fault" ;
VAL_ 970 LaRampType_B_Req 1 "Quick" 0 "Smooth" ;
VAL_ 970 LaCurvature_No_Calc 4095 "Fault" ;
VAL_ 970 LdwActvStats_D_Req 7 "LDW_Suppress_Right_Left" 6 "Not_Used2" 5 "LDW_Suppress_Right" 4 "LDW_Warning_Right" 3 "LDW_Suppress_Left" 2 "LDW_Warning_Left" 1 "Not_Used1" 0 "LDW_Idle" ;
VAL_ 970 LdwActvIntns_D_Req 3 "High" 2 "Medium" 1 "Low" 0 "None" ;
VAL_ 962 AdbBrdr3DistRigh_D_Stat 15 "DistGreater800m" 14 "Dist700mTo800m" 13 "Dist600mTo700m" 12 "Dist500mTo600m" 11 "Dist400mTo500m" 10 "Dist300mTo400m" 9 "Dist200mTo300m" 8 "Dist175mTo200m" 7 "Dist150mTo175m" 6 "Dist125mTo150m" 5 "Dist100mTo125m" 4 "Dist75mTo100m" 3 "Dist50mTo75m" 2 "Dist25mTo50m" 1 "Dist15mTo25m" 0 "Dist0mTo15m" ;
VAL_ 962 AdbBrdr3DistLeft_D_Stat 15 "DistGreater800m" 14 "Dist700mTo800m" 13 "Dist600mTo700m" 12 "Dist500mTo600m" 11 "Dist400mTo500m" 10 "Dist300mTo400m" 9 "Dist200mTo300m" 8 "Dist175mTo200m" 7 "Dist150mTo175m" 6 "Dist125mTo150m" 5 "Dist100mTo125m" 4 "Dist75mTo100m" 3 "Dist50mTo75m" 2 "Dist25mTo50m" 1 "Dist15mTo25m" 0 "Dist0mTo15m" ;
VAL_ 962 AdbMde3_D_Rq 3 "MarkerLightFlashing" 2 "MarkerLightConstant" 1 "Spot" 0 "None" ;
VAL_ 962 AdbIntns3_D_Rq 3 "Maximum" 2 "Medium" 1 "Low" 0 "Off" ;
VAL_ 962 AdbBrdr3Up_An_Rq 511 "Faulty" 510 "NoDataExists" ;
VAL_ 962 AdbBrdr3Right_An_Rq 2047 "Faulty" 2046 "NoDataExists" ;
VAL_ 962 AdbBrdr3Low_An_Rq 511 "Faulty" 510 "NoDataExists" ;
VAL_ 962 AdbBrdr3Left_An_Rq 2047 "Faulty" 2046 "NoDataExists" ;
VAL_ 961 AdbBrdr2DistRigh_D_Stat 15 "DistGreater800m" 14 "Dist700mTo800m" 13 "Dist600mTo700m" 12 "Dist500mTo600m" 11 "Dist400mTo500m" 10 "Dist300mTo400m" 9 "Dist200mTo300m" 8 "Dist175mTo200m" 7 "Dist150mTo175m" 6 "Dist125mTo150m" 5 "Dist100mTo125m" 4 "Dist75mTo100m" 3 "Dist50mTo75m" 2 "Dist25mTo50m" 1 "Dist15mTo25m" 0 "Dist0mTo15m" ;
VAL_ 961 AdbBrdr2DistLeft_D_Stat 15 "DistGreater800m" 14 "Dist700mTo800m" 13 "Dist600mTo700m" 12 "Dist500mTo600m" 11 "Dist400mTo500m" 10 "Dist300mTo400m" 9 "Dist200mTo300m" 8 "Dist175mTo200m" 7 "Dist150mTo175m" 6 "Dist125mTo150m" 5 "Dist100mTo125m" 4 "Dist75mTo100m" 3 "Dist50mTo75m" 2 "Dist25mTo50m" 1 "Dist15mTo25m" 0 "Dist0mTo15m" ;
VAL_ 961 AdbMde2_D_Rq 3 "MarkerLightFlashing" 2 "MarkerLightConstant" 1 "Spot" 0 "None" ;
VAL_ 961 AdbIntns2_D_Rq 3 "Maximum" 2 "Medium" 1 "Low" 0 "Off" ;
VAL_ 961 AdbBrdr2Up_An_Rq 511 "Faulty" 510 "NoDataExists" ;
VAL_ 961 AdbBrdr2Right_An_Rq 2047 "Faulty" 2046 "NoDataExists" ;
VAL_ 961 AdbBrdr2Low_An_Rq 511 "Faulty" 510 "NoDataExists" ;
VAL_ 961 AdbBrdr2Left_An_Rq 2047 "Faulty" 2046 "NoDataExists" ;
VAL_ 394 AccTrgDist2_D_Dsply 15 "DIST_ACTIVE_13_Farthest" 14 "DIST_ACTIVE_12" 13 "DIST_ACTIVE_11" 12 "DIST_ACTIVE_10" 11 "DIST_ACTIVE_9" 10 "DIST_ACTIVE_8" 9 "DIST_ACTIVE_7" 8 "DIST_ACTIVE_6" 7 "DIST_ACTIVE_5" 6 "DIST_ACTIVE_4" 5 "DIST_ACTIVE_3" 4 "DIST_ACTIVE_2" 3 "DIST_ACTIVE_1_Closest" 2 "DIST_ACTIVE_No_Target" 1 "DIST_STANDBY" 0 "DIST_OFF" ;
VAL_ 394 AccStopRes_B_Dsply 1 "Yes" 0 "No" ;
VAL_ 394 TjaWarn_D_Rq 7 "NotUsed_4" 6 "NotUsed_3" 5 "NotUsed_2" 4 "NotUsed_1" 3 "HardTakeOverLevel2" 2 "HardTakeOverLevel1" 1 "TrafficJamAssistCancel" 0 "NoWarning" ;
VAL_ 394 Tja_D_Stat 7 "NotUsed_1" 6 "ActiveWarningRight" 5 "ActiveWarningLeft" 4 "ActiveInterventionRight" 3 "ActiveInterventionLeft" 2 "Active" 1 "Standby" 0 "Off" ;
VAL_ 394 TjaMsgTxt_D_Dsply 7 "NotUsed_4" 6 "NotUsed_3" 5 "NotUsed_2" 4 "NotUsed_1" 3 "TurnOnAdaptCruiseControl" 2 "TrafficJamAssistSelected" 1 "TrafficJamAssistUnavailabl" 0 "NoMessage" ;
VAL_ 394 IaccLamp_D_Rq 3 "NotUsed_2" 2 "NotUsed_1" 1 "DisplayIaccIcon" 0 "DoNotDisplayIaccIcon" ;
VAL_ 394 AccMsgTxt_D2_Rq 15 "NotUsed_1" 14 "NCC_Enabled_Warning" 13 "IACC_TJA_Selected" 12 "ACC_TJA_Selected" 11 "IACC_Selected" 10 "Press_Brake_To_Hold" 9 "Only_Following_In_Low_Spd" 8 "TJA_Unavailable" 7 "Shift_Down" 6 "IACC_Unavailable" 5 "ACC_Selected" 4 "ACC_Overridden" 3 "Brake_Capacity_Warning" 2 "ACC_Cancelled" 1 "ACC_Unavailable" 0 "No_Text" ;
VAL_ 394 FcwDeny_B_Dsply 1 "Yes" 0 "No" ;
VAL_ 394 FdaWarn_B_Rq 1 "Yes" 0 "No" ;
VAL_ 394 FcwMemStat_B_Actl 1 "On" 0 "Off" ;
VAL_ 394 AccTGap_B_Dsply 1 "Yes" 0 "No" ;
VAL_ 394 CadsAlignIncplt_B_Actl 1 "Yes" 0 "No" ;
VAL_ 394 AccLowVMde_B_Dsply 1 "Yes" 0 "No" ;
VAL_ 394 AccFllwMde_B_Dsply 1 "Yes" 0 "No" ;
VAL_ 394 CadsRadrBlck_B_Actl 1 "Yes" 0 "No" ;
VAL_ 394 FdaStat_D_Dsply 7 "Undefined_3" 6 "Undefined_2" 5 "Undefined_1" 4 "Distance_Alert_Unavailable" 3 "DistanceAlertUnavail_Low" 2 "DistanceAlertUnavailActive" 1 "Distance_Alert_Available" 0 "Distance_Alert_Off" ;
VAL_ 394 FdaDeny_B_Dsply 1 "Yes" 0 "No" ;
VAL_ 394 CadsChime_B_Rq 1 "Yes" 0 "No" ;
VAL_ 394 CmbbPostEvnt_B_Dsply 1 "Yes" 0 "No" ;
VAL_ 394 FcwCmbbSrvcRqd_B_Rq 1 "Yes" 0 "No" ;
VAL_ 394 AccStopMde_B_Dsply 1 "Yes" 0 "No" ;
VAL_ 394 CadsCamraBlck_B_Actl 1 "Yes" 0 "No" ;
VAL_ 394 FcwMemSens_D_Actl 3 "FCW_Sensitivity_3" 2 "FCW_Sensitivity_2" 1 "FCW_Sensitivity_1" 0 "Not_Used" ;
VAL_ 394 FcwMemDfaltOn_B_Actl 1 "Default_On" 0 "Last_Setting" ;
VAL_ 394 AccSrvcRqd_B_Rq 1 "Yes" 0 "No" ;
VAL_ 394 FcwMsgTxt_D_Rq 7 "Undefined_3" 6 "Undefined_2" 5 "Low_Visibility" 4 "Unavailable_DueTo_LowSpeed" 3 "Available" 2 "Unavailable" 1 "Off" 0 "No_Text" ;
VAL_ 394 AccWarn_D_Dsply 3 "BrakeReleaseWarn_In_StopMd" 2 "Brake_Capacity_Warning" 1 "Cancel_Warning" 0 "No_Warning" ;
VAL_ 394 FcwVisblWarn_B_Rq 1 "On" 0 "Off" ;
VAL_ 394 FcwAudioWarn_B_Rq 1 "On" 0 "Off" ;
VAL_ 394 FcwMemAudioOn_B_Actl 1 "On" 0 "Off" ;
VAL_ 394 AccTGap_D_Dsply 7 "Undefined_2" 6 "Undefined_1" 5 "Time_Gap_5" 4 "Time_Gap_4" 3 "Time_Gap_3" 2 "Time_Gap_2" 1 "Time_Gap_1" 0 "Not_Used" ;
VAL_ 394 AccMemEnbl_B_RqDrv 1 "Adaptive_Cruise" 0 "Normal_Cruise" ;
VAL_ 394 FdaMem_B_Stat 1 "On" 0 "Off" ;
VAL_ 391 CadsRadarStat_D_Qf 3 "OK" 2 "Not_Within_Specifications" 1 "No_Data_Exists" 0 "Faulty" ;
VAL_ 391 CadsAudioMute_D_Rq 3 "Reserved" 2 "Partial_Audio_Mute" 1 "Full_Audio_Mute" 0 "No_Audio_Mute" ;
VAL_ 391 HudBlk3_B_Rq 1 "Yes" 0 "No" ;
VAL_ 391 HudBlk2_B_Rq 1 "Yes" 0 "No" ;
VAL_ 391 HudBlk1_B_Rq 1 "Yes" 0 "No" ;
VAL_ 391 HudFlashRate_D_Actl 3 "Unused" 2 "Flash_4Hz_50Prct_DutyCycle" 1 "On" 0 "Off" ;
VAL_ 391 CmbbBrkPrchg_D_Rq 3 "Undefined" 2 "Level_2_PreCharge_Request" 1 "Level_1_PreCharge_Request" 0 "No_PreCharge_Request" ;
VAL_ 391 CmbbBrkDecel_B_Rq 1 "Yes" 0 "No" ;
VAL_ 391 CmbbBaSens_D_Rq 3 "Level_3" 2 "Level_2" 1 "Level_1" 0 "Normal" ;
VAL_ 390 AccBrkPrkEl_B_Rq 1 "Yes" 0 "No" ;
VAL_ 390 Cmbb_B_Enbl 1 "Yes" 0 "No" ;
VAL_ 390 CmbbOvrrd_B_RqDrv 1 "Yes" 0 "No" ;
VAL_ 390 CmbbDeny_B_Actl 1 "Yes" 0 "No" ;
VAL_ 390 CmbbEngTqMn_B_Rq 1 "Yes" 0 "No" ;
VAL_ 390 AccDeny_B_Rq 1 "Yes" 0 "No" ;
VAL_ 390 AccResumEnbl_B_Rq 1 "Yes" 0 "No" ;
VAL_ 390 AccCancl_B_Rq 1 "Yes" 0 "No" ;
VAL_ 390 AccBrkPrchg_B_Rq 1 "Yes" 0 "No" ;
VAL_ 390 AccBrkDecel_B_Rq 1 "Active" 0 "Inactive" ;
VAL_ 390 AccStopStat_B_Rq 1 "Yes" 0 "No" ;
VAL_ 1186 SelDrvMdeAwd2_D_Stat 31 "Faulty" 30 "NotUsed_17" 29 "NotUsed_16" 28 "NotUsed_15" 27 "NotUsed_14" 26 "NotUsed_13" 25 "NotUsed_12" 24 "NotUsed_11" 23 "NotUsed_10" 22 "NotUsed_9" 21 "NotUsed_8" 20 "NotUsed_7" 19 "NotUsed_6" 18 "NotUsed_5" 17 "EvLaterChargeMode" 16 "EvNowMode" 15 "TrackMode" 14 "RoughRoadMode" 13 "NotAvailable" 12 "HighSpeedDesertMode_Baja" 11 "SportAdaptiveMode" 10 "RockCrawlMode" 9 "MudRutsMode" 8 "SandMode" 7 "EconomyMode" 6 "GrassGravelSnow" 5 "TowHaulMode" 4 "SportMode" 3 "Normal_4L" 2 "Normal_4A" 1 "Normal_2H" 0 "NormalMode" ;
VAL_ 1186 RearDiffLckMsg_D_Rq 7 "Locker_Disabled" 6 "Locker_Enabled" 5 "Locker_Accel_Pedal" 4 "Speed4" 3 "Speed3" 2 "Spee2" 1 "Speed1" 0 "Normal__No_Message " ;
VAL_ 1186 RearDiffLckLamp_D_Rq 3 "Not_Used" 2 "Flash" 1 "On" 0 "Off" ;
VAL_ 1186 RearDiffLck_Tq_Actl 4095 "Fault" 4094 "Unknown" ;
VAL_ 1186 RearDiffFalt_D_Stat 3 "Diff_Failed_Closed" 2 "Diff_Failed_Open" 1 "Fault_Non_Specific" 0 "No_Fault" ;
VAL_ 1186 LsdSrvcRqd_B_Rq 1 "On" 0 "Off" ;
VAL_ 611 AwdSys_D_Stat 3 "Faulty" 2 "NotUsed" 1 "_4x4_L_H_Active" 0 "_4x4_L_H_Inactive" ;
VAL_ 611 AwdStat_D_RqDsply 31 "NotUsed9" 30 "NotUsed8" 29 "NotUsed7" 28 "To_Engage_4x4_Release_Aped" 27 "To_Engage_4x4_Slow_To_3MPH" 26 "Shift_To_Neutral" 25 "Lkr_Mode_Unavail_TMS" 24 " _4x4_Mode_Unavail_TMS" 23 "Out_of_4Low_Crawl" 22 "AWD_PTU_Oil_Changed" 21 "Change_AWD_PTU_Oil" 20 "Neutral_Tow_Disabled" 19 "Neutral_Tow_Enabled" 18 "AWD_OFF" 17 "_4x4_Off_Road_Speed" 16 "_4x4_Extreme_Off_Road_Mode" 15 "_4x4_Exiting_Off_Road" 14 "_4x4_Off_Road_Mode" 10 "_4x4_Locked_Temporarily" 9 "Shift_In_Progress" 13 "Blocked_Shift_Assist" 12 "_4x4_Auto_Restored" 11 "_4x4_Disabled_Temporarily" 7 "Out_of_4Low__Neutral" 6 "Out_of_4Low__Brake" 5 "Out_of_4Low__Speed" 4 "Into_4Low__Clutch" 3 "Into_4Low__Neutral" 2 "Into_4Low__Brake" 1 "Into_4Low__Speed" 0 "Normal__No_Message" 8 "Out_of_4Low__Clutch" ;
VAL_ 611 AwdLck_D_Stat 9 "Undefined" 8 "Under_External_Torque_Ctrl" 7 "Torque_Limited_by_Cmd" 6 "Fully_Locked_by_Cmd" 5 "Disabled" 4 "Warning" 3 "Fault" 2 "Inactive" 1 "Completely_Opened_by_Cmd" 0 "OK" ;
VAL_ 611 AwdSrvcRqd_B_Rq 1 "On" 0 "Off" ;
VAL_ 611 NtrlTowAvail_B_Stat 1 "Available" 0 "NotAvailable" ;
VAL_ 611 AwdLck_Tq_Rq 4095 "Fault" 4094 "Unknown" ;
VAL_ 611 AwdOffRoadMode_D_Stats 3 "Invalid" 2 "Extreme_Off_Road" 1 "Off_Road" 0 "Normal_Mode" ;
VAL_ 611 AwdLoLamp_D_RqDsply 3 "Not_Used" 2 "Flash" 1 "On" 0 "Off" ;
VAL_ 611 AwdHiLamp_D_RqDsply 3 "Not_Used" 2 "Flash" 1 "On" 0 "Off" ;
VAL_ 611 AwdAutoLamp_D_RqDsply 3 "Not_Used" 2 "Flash" 1 "On" 0 "Off" ;
VAL_ 611 Awd2wdLamp_D_RqDsply 3 "Not_Used" 2 "Flash" 1 "On" 0 "Off" ;
VAL_ 611 AwdRnge_D_Actl 7 "Unknown" 6 "High_Range_2wd" 5 "High_Range_Auto" 4 "High_Range_Locked" 3 "Neutral" 2 "Low_Range_2wd" 1 "Low_Range_Auto" 0 "Low_Range_Locked" ;
VAL_ 1303 TrlrAidSetup_D2_Stat 7 "NotUsed_2" 6 "NotUsed_1" 5 "SetupAcquisitionSuccess" 4 "TbaTadMonitor" 3 "SetupStartAcquisition" 2 "SetupPrepForAcquisition" 1 "TbaActive" 0 "Null" ;
VAL_ 1303 TrlrAidEnbl_D2_Stat 7 "NotUsed_1" 6 "TbaActiveExpertActive" 5 "TbaActiveExpertAvail" 4 "TbaOffTrgActive" 3 "TbaOffTrgSetup" 2 "TbaSetup" 1 "TbaActive" 0 "Inactive" ;
VAL_ 1303 TrlrAidMsgTxt_D2_Rq 63 "Message63" 62 "Message62" 61 "Message61" 60 "Message60" 55 "Message55" 50 "Message50" 45 "Message45" 40 "Message40" 35 "Message35" 31 "Message31" 30 "Message30" 29 "Message29" 28 "Message28" 27 "Message27" 26 "Message26" 25 "Message25" 24 "Message24" 23 "Message23" 22 "Message22" 21 "Message21" 20 "Message20" 19 "Message19" 18 "Message18" 17 "Message17" 16 "Message16" 15 "Message15" 14 "Message14" 13 "Message13" 12 "Message12" 11 "Message11" 10 "Message10" 9 "Message9" 8 "Message8" 7 "Message7" 6 "Message6" 5 "Message5" 4 "Message4" 3 "Message3" 2 "Message2" 1 "Message1" 0 "NoMessage" ;
VAL_ 1303 EsaOn_B_Stat 1 "On" 0 "Off" ;
VAL_ 1303 LatCtlSte_D_Stat 7 "NotUsed3" 6 "NotUsed2" 5 "NotUsed1" 4 "Denied" 3 "RampOut" 2 "ContLatControlInProgress" 1 "Available" 0 "Unavailable" ;
VAL_ 1303 LatCtlLim_D_Stat 3 "LimitWithDriverActive" 2 "LimitReached" 1 "LimitClose" 0 "LimitNotReached" ;
VAL_ 1303 SelDrvMdeSte_D_Stat 0 "NotAvailable" 1 "Available" 2 "TemporarilyNotAvailable" 3 "Faulty" ;
VAL_ 1228 LsmcBrkDecelEnbl_D_Rq 3 "NotUsed2" 2 "NotUsed1" 1 "On" 0 "Off" ;
VAL_ 1228 TjaHandsOnCnfdnc_B_Est 1 "High_Confidence" 0 "Low_Confidence" ;
VAL_ 1228 LaHandsOff_B_Actl 1 "Hands_Off" 0 "Hands_On" ;
VAL_ 1228 LaActDeny_B_Actl 1 "LA_Denied" 0 "LA_Not_Denied" ;
VAL_ 1228 LaActAvail_D_Actl 3 "LKA_LCA_LDW_Avail" 2 "LCA_LKA_Avail_LDW_Suppress" 1 "LCA_LKA_Suppress_LDW_Avail" 0 "LCA_LKA_LDW_Suppress" ;
VAL_ 386 TrlrHitchLamp_D_Rqst 1 "On" 0 "Off" ;
VAL_ 386 VehVTrlrAid_B_Rq 1 "Request" 0 "NoRequest" ;
VAL_ 386 DrvSteActv_B_Stat 1 "Active" 0 "Inactive" ;
VAL_ 386 DrvSte_Tq_Actl 255 "Invalid" 254 "Unknown" ;
VAL_ 386 SteMdule_D_Stat 7 "NotUsed" 6 "EPAS_Failure3" 5 "EPAS_Failure2" 4 "System_Failure" 3 "EPAS_Shutdown" 2 "Normal_Op_Full_Assist" 1 "Normal_Op_Limited_Assist" 0 "EPAS_Initialization" ;
VAL_ 386 SteMdule_U_Meas 255 "Invalid" ;
VAL_ 386 SteMdule_I_Est 4095 "Invalid" ;
VAL_ 386 EPAS_Failure 3 "SERVICE_POWER_STEERING_NOW" 2 "SERVICE_POWER_STEERING" 1 "POWER_STRG_ASSIST_FAULT" 0 "EPAS_OK_NO_MESSAGE" ;
VAL_ 386 SteeringColumnTorque 255 "Invalid" 254 "Unknown" ;
VAL_ 386 SAPPAngleControlStat6 1 "RequestedAngleNotReached" 0 "RequestedAngleCanBeReached" ;
VAL_ 386 SAPPAngleControlStat5 1 "StrgColTorqueExceed_EAROn" 0 "ExternalSigContentOKforEAC" ;
VAL_ 386 SAPPAngleControlStat4 1 "SpeedLimitExceededEAROn" 0 "ExternalSigContentOKforEAC" ;
VAL_ 386 SAPPAngleControlStat3 1 "EARactiveNoReverseEngage" 0 "ExternalSigContentOKforEAC" ;
VAL_ 386 SAPPAngleControlStat2 1 "Rel_ExtSteeringAngleReqx" 0 "NoRel_ExtSteeringAngleReqx" ;
VAL_ 386 SAPPAngleControlStat1 3 "Fault" 2 "Active" 1 "Open" 0 "Closed" ;
VAL_ 382 StePw_B_Rq 1 "Yes" 0 "No" ;
VAL_ 382 StePinRelInit_An_Sns 65535 "Faulty" 65534 "NoDataExists" ;
VAL_ 382 StePinCompAnEst_D_Qf 3 "OK" 2 "Degraded" 1 "No_Data_Exists" 0 "Faulty" ;
VAL_ 1200 HsaTrnAout_Tq_Rq 65535 "Fault" 65534 "Unknown" ;
VAL_ 1200 BrkBstrVac_P_Actl 127 "Invalid" ;
VAL_ 1200 YawStabilityIndex 511 "Fault" 510 "NoDataExists" ;
VAL_ 1200 BrkTot_Tq_RqDrv 8191 "Fault" ;
VAL_ 1200 BrkAutoHold_D_Stat 7 "Faulty" 6 "NotUsed" 5 "Releasing" 4 "HeldSecondary" 3 "HeldSecure" 2 "Held" 1 "Inactive" 0 "Off" ;
VAL_ 1200 HsaStat_D_Dsply 7 "NotUsed3" 6 "NotUsed2" 5 "NotUsed1" 4 "NotAvailable" 3 "SlowReleaseWithChime" 2 "SlowReleaseWithoutChime" 1 "Active" 0 "Inactive" ;
VAL_ 1102 SelDrvMdePos12_D_Stat 31 "Faulty" 30 "SelDrvMde31" 29 "SelDrvMde30" 28 "SelDrvMde29" 27 "SelDrvMde28" 26 "SelDrvMde27" 25 "SelDrvMde26" 24 "SelDrvMde25" 23 "SelDrvMde24" 22 "SelDrvMde23" 21 "SelDrvMde22" 20 "SelDrvMde21" 19 "SelDrvMde20" 18 "SelDrvMde19" 17 "SelDrvMde18" 16 "SelDrvMde17" 15 "SelDrvMde16" 14 "SelDrvMde15" 13 "SelDrvMde14" 12 "SelDrvMde13" 11 "SelDrvMde12" 10 "SelDrvMde11" 9 "SelDrvMde10" 8 "SelDrvMde09" 7 "SelDrvMde08" 6 "SelDrvMde07" 5 "SelDrvMde06" 4 "SelDrvMde05" 3 "SelDrvMde04" 2 "SelDrvMde03" 1 "SelDrvMde02" 0 "SelDrvMde01" ;
VAL_ 1102 SelDrvMdePos11_D_Stat 31 "Faulty" 30 "SelDrvMde31" 29 "SelDrvMde30" 28 "SelDrvMde29" 27 "SelDrvMde28" 26 "SelDrvMde27" 25 "SelDrvMde26" 24 "SelDrvMde25" 23 "SelDrvMde24" 22 "SelDrvMde23" 21 "SelDrvMde22" 20 "SelDrvMde21" 19 "SelDrvMde20" 18 "SelDrvMde19" 17 "SelDrvMde18" 16 "SelDrvMde17" 15 "SelDrvMde16" 14 "SelDrvMde15" 13 "SelDrvMde14" 12 "SelDrvMde13" 11 "SelDrvMde12" 10 "SelDrvMde11" 9 "SelDrvMde10" 8 "SelDrvMde09" 7 "SelDrvMde08" 6 "SelDrvMde07" 5 "SelDrvMde06" 4 "SelDrvMde05" 3 "SelDrvMde04" 2 "SelDrvMde03" 1 "SelDrvMde02" 0 "SelDrvMde01" ;
VAL_ 1102 SelDrvMdePos10_D_Stat 31 "Faulty" 30 "SelDrvMde31" 29 "SelDrvMde30" 28 "SelDrvMde29" 27 "SelDrvMde28" 26 "SelDrvMde27" 25 "SelDrvMde26" 24 "SelDrvMde25" 23 "SelDrvMde24" 22 "SelDrvMde23" 21 "SelDrvMde22" 20 "SelDrvMde21" 19 "SelDrvMde20" 18 "SelDrvMde19" 17 "SelDrvMde18" 16 "SelDrvMde17" 15 "SelDrvMde16" 14 "SelDrvMde15" 13 "SelDrvMde14" 12 "SelDrvMde13" 11 "SelDrvMde12" 10 "SelDrvMde11" 9 "SelDrvMde10" 8 "SelDrvMde09" 7 "SelDrvMde08" 6 "SelDrvMde07" 5 "SelDrvMde06" 4 "SelDrvMde05" 3 "SelDrvMde04" 2 "SelDrvMde03" 1 "SelDrvMde02" 0 "SelDrvMde01" ;
VAL_ 1102 SelDrvMdePos09_D_Stat 31 "Faulty" 30 "SelDrvMde31" 29 "SelDrvMde30" 28 "SelDrvMde29" 27 "SelDrvMde28" 26 "SelDrvMde27" 25 "SelDrvMde26" 24 "SelDrvMde25" 23 "SelDrvMde24" 22 "SelDrvMde23" 21 "SelDrvMde22" 20 "SelDrvMde21" 19 "SelDrvMde20" 18 "SelDrvMde19" 17 "SelDrvMde18" 16 "SelDrvMde17" 15 "SelDrvMde16" 14 "SelDrvMde15" 13 "SelDrvMde14" 12 "SelDrvMde13" 11 "SelDrvMde12" 10 "SelDrvMde11" 9 "SelDrvMde10" 8 "SelDrvMde09" 7 "SelDrvMde08" 6 "SelDrvMde07" 5 "SelDrvMde06" 4 "SelDrvMde05" 3 "SelDrvMde04" 2 "SelDrvMde03" 1 "SelDrvMde02" 0 "SelDrvMde01" ;
VAL_ 1102 SelDrvMdePos08_D_Stat 31 "Faulty" 30 "SelDrvMde31" 29 "SelDrvMde30" 28 "SelDrvMde29" 27 "SelDrvMde28" 26 "SelDrvMde27" 25 "SelDrvMde26" 24 "SelDrvMde25" 23 "SelDrvMde24" 22 "SelDrvMde23" 21 "SelDrvMde22" 20 "SelDrvMde21" 19 "SelDrvMde20" 18 "SelDrvMde19" 17 "SelDrvMde18" 16 "SelDrvMde17" 15 "SelDrvMde16" 14 "SelDrvMde15" 13 "SelDrvMde14" 12 "SelDrvMde13" 11 "SelDrvMde12" 10 "SelDrvMde11" 9 "SelDrvMde10" 8 "SelDrvMde09" 7 "SelDrvMde08" 6 "SelDrvMde07" 5 "SelDrvMde06" 4 "SelDrvMde05" 3 "SelDrvMde04" 2 "SelDrvMde03" 1 "SelDrvMde02" 0 "SelDrvMde01" ;
VAL_ 1102 SelDrvMdePos07_D_Stat 31 "Faulty" 30 "SelDrvMde31" 29 "SelDrvMde30" 28 "SelDrvMde29" 27 "SelDrvMde28" 26 "SelDrvMde27" 25 "SelDrvMde26" 24 "SelDrvMde25" 23 "SelDrvMde24" 22 "SelDrvMde23" 21 "SelDrvMde22" 20 "SelDrvMde21" 19 "SelDrvMde20" 18 "SelDrvMde19" 17 "SelDrvMde18" 16 "SelDrvMde17" 15 "SelDrvMde16" 14 "SelDrvMde15" 13 "SelDrvMde14" 12 "SelDrvMde13" 11 "SelDrvMde12" 10 "SelDrvMde11" 9 "SelDrvMde10" 8 "SelDrvMde09" 7 "SelDrvMde08" 6 "SelDrvMde07" 5 "SelDrvMde06" 4 "SelDrvMde05" 3 "SelDrvMde04" 2 "SelDrvMde03" 1 "SelDrvMde02" 0 "SelDrvMde01" ;
VAL_ 1102 SelDrvMdePos06_D_Stat 31 "Faulty" 30 "SelDrvMde31" 29 "SelDrvMde30" 28 "SelDrvMde29" 27 "SelDrvMde28" 26 "SelDrvMde27" 25 "SelDrvMde26" 24 "SelDrvMde25" 23 "SelDrvMde24" 22 "SelDrvMde23" 21 "SelDrvMde22" 20 "SelDrvMde21" 19 "SelDrvMde20" 18 "SelDrvMde19" 17 "SelDrvMde18" 16 "SelDrvMde17" 15 "SelDrvMde16" 14 "SelDrvMde15" 13 "SelDrvMde14" 12 "SelDrvMde13" 11 "SelDrvMde12" 10 "SelDrvMde11" 9 "SelDrvMde10" 8 "SelDrvMde09" 7 "SelDrvMde08" 6 "SelDrvMde07" 5 "SelDrvMde06" 4 "SelDrvMde05" 3 "SelDrvMde04" 2 "SelDrvMde03" 1 "SelDrvMde02" 0 "SelDrvMde01" ;
VAL_ 1102 SelDrvMdePos05_D_Stat 31 "Faulty" 30 "SelDrvMde31" 29 "SelDrvMde30" 28 "SelDrvMde29" 27 "SelDrvMde28" 26 "SelDrvMde27" 25 "SelDrvMde26" 24 "SelDrvMde25" 23 "SelDrvMde24" 22 "SelDrvMde23" 21 "SelDrvMde22" 20 "SelDrvMde21" 19 "SelDrvMde20" 18 "SelDrvMde19" 17 "SelDrvMde18" 16 "SelDrvMde17" 15 "SelDrvMde16" 14 "SelDrvMde15" 13 "SelDrvMde14" 12 "SelDrvMde13" 11 "SelDrvMde12" 10 "SelDrvMde11" 9 "SelDrvMde10" 8 "SelDrvMde09" 7 "SelDrvMde08" 6 "SelDrvMde07" 5 "SelDrvMde06" 4 "SelDrvMde05" 3 "SelDrvMde04" 2 "SelDrvMde03" 1 "SelDrvMde02" 0 "SelDrvMde01" ;
VAL_ 1102 SelDrvMdePos04_D_Stat 31 "Faulty" 30 "SelDrvMde31" 29 "SelDrvMde30" 28 "SelDrvMde29" 27 "SelDrvMde28" 26 "SelDrvMde27" 25 "SelDrvMde26" 24 "SelDrvMde25" 23 "SelDrvMde24" 22 "SelDrvMde23" 21 "SelDrvMde22" 20 "SelDrvMde21" 19 "SelDrvMde20" 18 "SelDrvMde19" 17 "SelDrvMde18" 16 "SelDrvMde17" 15 "SelDrvMde16" 14 "SelDrvMde15" 13 "SelDrvMde14" 12 "SelDrvMde13" 11 "SelDrvMde12" 10 "SelDrvMde11" 9 "SelDrvMde10" 8 "SelDrvMde09" 7 "SelDrvMde08" 6 "SelDrvMde07" 5 "SelDrvMde06" 4 "SelDrvMde05" 3 "SelDrvMde04" 2 "SelDrvMde03" 1 "SelDrvMde02" 0 "SelDrvMde01" ;
VAL_ 1102 SelDrvMdePos03_D_Stat 31 "Faulty" 30 "SelDrvMde31" 29 "SelDrvMde30" 28 "SelDrvMde29" 27 "SelDrvMde28" 26 "SelDrvMde27" 25 "SelDrvMde26" 24 "SelDrvMde25" 23 "SelDrvMde24" 22 "SelDrvMde23" 21 "SelDrvMde22" 20 "SelDrvMde21" 19 "SelDrvMde20" 18 "SelDrvMde19" 17 "SelDrvMde18" 16 "SelDrvMde17" 15 "SelDrvMde16" 14 "SelDrvMde15" 13 "SelDrvMde14" 12 "SelDrvMde13" 11 "SelDrvMde12" 10 "SelDrvMde11" 9 "SelDrvMde10" 8 "SelDrvMde09" 7 "SelDrvMde08" 6 "SelDrvMde07" 5 "SelDrvMde06" 4 "SelDrvMde05" 3 "SelDrvMde04" 2 "SelDrvMde03" 1 "SelDrvMde02" 0 "SelDrvMde01" ;
VAL_ 1102 SelDrvMdePos02_D_Stat 31 "Faulty" 30 "SelDrvMde31" 29 "SelDrvMde30" 28 "SelDrvMde29" 27 "SelDrvMde28" 26 "SelDrvMde27" 25 "SelDrvMde26" 24 "SelDrvMde25" 23 "SelDrvMde24" 22 "SelDrvMde23" 21 "SelDrvMde22" 20 "SelDrvMde21" 19 "SelDrvMde20" 18 "SelDrvMde19" 17 "SelDrvMde18" 16 "SelDrvMde17" 15 "SelDrvMde16" 14 "SelDrvMde15" 13 "SelDrvMde14" 12 "SelDrvMde13" 11 "SelDrvMde12" 10 "SelDrvMde11" 9 "SelDrvMde10" 8 "SelDrvMde09" 7 "SelDrvMde08" 6 "SelDrvMde07" 5 "SelDrvMde06" 4 "SelDrvMde05" 3 "SelDrvMde04" 2 "SelDrvMde03" 1 "SelDrvMde02" 0 "SelDrvMde01" ;
VAL_ 1102 SelDrvMdePos01_D_Stat 31 "Faulty" 30 "SelDrvMde31" 29 "SelDrvMde30" 28 "SelDrvMde29" 27 "SelDrvMde28" 26 "SelDrvMde27" 25 "SelDrvMde26" 24 "SelDrvMde25" 23 "SelDrvMde24" 22 "SelDrvMde23" 21 "SelDrvMde22" 20 "SelDrvMde21" 19 "SelDrvMde20" 18 "SelDrvMde19" 17 "SelDrvMde18" 16 "SelDrvMde17" 15 "SelDrvMde16" 14 "SelDrvMde15" 13 "SelDrvMde14" 12 "SelDrvMde13" 11 "SelDrvMde12" 10 "SelDrvMde11" 9 "SelDrvMde10" 8 "SelDrvMde09" 7 "SelDrvMde08" 6 "SelDrvMde07" 5 "SelDrvMde06" 4 "SelDrvMde05" 3 "SelDrvMde04" 2 "SelDrvMde03" 1 "SelDrvMde02" 0 "SelDrvMde01" ;
VAL_ 1056 SelDrvMdePos12_B_Avail 1 "Available" 0 "NotAvailable" ;
VAL_ 1056 SelDrvMdePos11_B_Avail 1 "Available" 0 "NotAvailable" ;
VAL_ 1056 SelDrvMdePos10_B_Avail 1 "Available" 0 "NotAvailable" ;
VAL_ 1056 SelDrvMdePos09_B_Avail 1 "Available" 0 "NotAvailable" ;
VAL_ 1056 SelDrvMdePos08_B_Avail 1 "Available" 0 "NotAvailable" ;
VAL_ 1056 SelDrvMdePos07_B_Avail 1 "Available" 0 "NotAvailable" ;
VAL_ 1056 SelDrvMdePos06_B_Avail 1 "Available" 0 "NotAvailable" ;
VAL_ 1056 SelDrvMdePos05_B_Avail 1 "Available" 0 "NotAvailable" ;
VAL_ 1056 SelDrvMdePos04_B_Avail 1 "Available" 0 "NotAvailable" ;
VAL_ 1056 SelDrvMdePos03_B_Avail 1 "Available" 0 "NotAvailable" ;
VAL_ 1056 SelDrvMdePos02_B_Avail 1 "Available" 0 "NotAvailable" ;
VAL_ 1056 SelDrvMdePos01_B_Avail 1 "Available" 0 "NotAvailable" ;
VAL_ 1056 ActvDrvMde_D2_Stat 31 "Faulty" 30 "SelDrvMde31" 29 "SelDrvMde30" 28 "SelDrvMde29" 27 "SelDrvMde28" 26 "SelDrvMde27" 25 "SelDrvMde26" 24 "SelDrvMde25" 23 "SelDrvMde24" 22 "SelDrvMde23" 21 "SelDrvMde22" 20 "SelDrvMde21" 19 "SelDrvMde20" 18 "SelDrvMde19" 17 "SelDrvMde18" 16 "SelDrvMde17" 15 "SelDrvMde16" 14 "SelDrvMde15" 13 "SelDrvMde14" 12 "SelDrvMde13" 11 "SelDrvMde12" 10 "SelDrvMde11" 9 "SelDrvMde10" 8 "SelDrvMde09" 7 "SelDrvMde08" 6 "SelDrvMde07" 5 "SelDrvMde06" 4 "SelDrvMde05" 3 "SelDrvMde04" 2 "SelDrvMde03" 1 "SelDrvMde02" 0 "SelDrvMde01" ;
VAL_ 1056 SelDrvMde_D2_Rq 31 "Faulty" 30 "SelDrvMde31" 29 "SelDrvMde30" 28 "SelDrvMde29" 27 "SelDrvMde28" 26 "SelDrvMde27" 25 "SelDrvMde26" 24 "SelDrvMde25" 23 "SelDrvMde24" 22 "SelDrvMde23" 21 "SelDrvMde22" 20 "SelDrvMde21" 19 "SelDrvMde20" 18 "SelDrvMde19" 17 "SelDrvMde18" 16 "SelDrvMde17" 15 "SelDrvMde16" 14 "SelDrvMde15" 13 "SelDrvMde14" 12 "SelDrvMde13" 11 "SelDrvMde12" 10 "SelDrvMde11" 9 "SelDrvMde10" 8 "SelDrvMde09" 7 "SelDrvMde08" 6 "SelDrvMde07" 5 "SelDrvMde06" 4 "SelDrvMde05" 3 "SelDrvMde04" 2 "SelDrvMde03" 1 "SelDrvMde02" 0 "SelDrvMde01" ;
VAL_ 1056 SelDrvMdePt_D_Rq 31 "Faulty" 30 "NotUsed15" 29 "NotUsed14" 28 "NotUsed13" 27 "NotUsed12" 26 "NotUsed11" 25 "NotUsed10" 24 "NotUsed9" 23 "NotUsed8" 22 "NotUsed7" 21 "NotUsed6" 20 "NotUsed5" 19 "NotUsed4" 18 "EvLaterChargerMode" 17 "EvNowMode" 16 "DragMode" 15 "HighSpeedDesertMode_Baja" 14 "SportAdaptiveMode" 13 "NotAvailable_13" 12 "NotAvailable_12" 11 "NotAvailable_11" 10 "NotAvailable_10" 9 "RockCrawlMode" 8 "MudRutsMode" 7 "SandMode" 6 "EconomyMode" 5 "GrassGravelSnow" 4 "NotAvailable_04" 3 "TowHaulMode" 2 "NotAvailable_02" 1 "SportMode" 0 "NormalMode" ;
VAL_ 1056 SelDrvMdeMsgTxt_D_Rq 15 "Message15" 14 "Message14" 13 "Message13" 12 "Message12" 11 "Message11" 10 "Message10" 9 "Message9" 8 "Message8" 7 "Message7" 6 "Message6" 5 "Message5" 4 "Message4" 3 "Message3" 2 "Message2" 1 "Message1" 0 "NoMessage" ;
VAL_ 1056 SelDrvMde_D_Stat 3 "NotUsed" 2 "DriveModeChangeRequest" 1 "DriveModeChangeSelection" 0 "NoDriveModeChangeRequest" ;
VAL_ 1056 AwdMde_D_RqBrk 7 "Faulty" 6 "NotUsed2" 5 "NoRequest" 4 "Neutral" 3 "FourByFourLow" 2 "FourByFourHigh" 1 "FourByFourAuto" 0 "FourByTwo" ;
VAL_ 1054 TrailCtlMsgTxt_D_Rq 15 "Message15" 14 "Message14" 13 "Message13" 12 "Message12" 11 "Message11" 10 "Message10" 9 "Message9" 8 "Message8" 7 "Message7" 6 "Message6" 5 "Message5" 4 "Message4" 3 "Message3" 2 "Message2" 1 "Message1" 0 "NoMessage" ;
VAL_ 1054 TrailCtl_D_Stat 7 "Faulty" 6 "DescentOnly" 5 "EnabledDeny" 4 "StandbyOverThreshold" 3 "StandbyOverride" 2 "Active" 1 "EnabledDescent" 0 "Off" ;
VAL_ 1054 RbaBrk_D_Stat 3 "Denied" 2 "Active" 1 "Open" 0 "Closed" ;
VAL_ 1054 SelDrvMdeChassis2_D_Rq 31 "Faulty" 30 "NotUsed17" 29 "NotUsed16" 28 "NotUsed15" 27 "NotUsed14" 26 "NotUsed13" 25 "NotUsed12" 24 "NotUsed11" 23 "NotUsed10" 22 "NotUsed9" 21 "NotUsed8" 20 "NotUsed7" 19 "NotUsed6" 18 "NotUsed5" 17 "NotUsed4" 16 "NotUsed3" 15 "NotUsed2" 14 "RoughRoadMode" 13 "TrackMode" 12 "HighSpeedDesertMode" 11 "TowHaulMode" 10 "RockCrawlMode" 9 "SandMode" 8 "MudAndRutsMode" 7 "LowMuMode" 6 "ComfortAdaptiveMode" 5 "ComfortMode" 4 "SportAdaptiveMode" 3 "SportMode" 2 "EconomyMode" 1 "NormalAdaptiveMode" 0 "NormalMode" ;
VAL_ 1054 BrkBstrVac_D_Stat 3 "NotUsed" 2 "BoosterVacEstimator" 1 "BoosterVacSensor" 0 "NoBoosterVacuumMonitor" ;
VAL_ 1054 DrvSlipCtlOffLamp_D_Rq 3 "Fast_Flash" 2 "Slow_Flash" 1 "On" 0 "Off" ;
VAL_ 1054 DrvSlipCtlMdeMsg_D_Rq 31 "Message31" 30 "Message30" 29 "Message29" 28 "Message28" 27 "Message27" 26 "Message26" 25 "Message25" 24 "Message24" 23 "Message23" 22 "Message22" 21 "Message21" 20 "Message20" 19 "Message19" 18 "Message18" 17 "Message17" 16 "Message16" 15 "Message15" 14 "Message14" 13 "Message13" 12 "Message12" 11 "Message11" 10 "Message10" 9 "Message9" 8 "Message8" 7 "Message7" 6 "Message6" 5 "Message5" 4 "Message4" 3 "Message3" 2 "Message2" 1 "Message1" 0 "NoMessage" ;
VAL_ 1054 AutoHoldMsgTxt_D_Rq 15 "Message15" 14 "Message14" 13 "Message13" 12 "Message12" 11 "Message11" 10 "Message10" 9 "Message9" 8 "Message8" 7 "Message7" 6 "Message6" 5 "Message5" 4 "Message4" 3 "Message3" 2 "Message2" 1 "Message1" 0 "NoMessage" ;
VAL_ 1054 CtaBrk_D_Stat 3 "Denied" 2 "Active" 1 "Open" 0 "Closed" ;
VAL_ 1054 SelDrvMdeAwd_D_Rq 31 "Faulty" 30 "NotUsed_17" 29 "NotUsed_16" 28 "NotUsed_15" 27 "NotUsed_14" 26 "NotUsed_13" 25 "NotUsed_12" 24 "NotUsed_11" 23 "NotUsed_10" 22 "NotUsed_9" 21 "NotUsed_8" 20 "NotUsed_7" 19 "NotUsed_6" 18 "NotUsed_5" 17 "EvLaterChargeMode" 16 "EvNowMode" 15 "TrackMode" 14 "RoughRoadMode" 13 "NotAvailable" 12 "HighSpeedDesertMode_Baja" 11 "SportAdaptiveMode" 10 "RockCrawlMode" 9 "MudRutsMode" 8 "SandMode" 7 "EconomyMode" 6 "GrassGravelSnow" 5 "TowHaulMode" 4 "SportMode" 3 "Normal_4L" 2 "Normal_4A" 1 "Normal_2H" 0 "NormalMode" ;
VAL_ 1054 AutoHoldSwMde_B_Ind 1 "On" 0 "Off" ;
VAL_ 1054 AutoHoldMde_D_Ind 3 "Indication_3" 2 "Indication_2" 1 "Indication_1" 0 "Off" ;
VAL_ 1054 BrkMdeInhbt_B_RqDsply 1 "Yes" 0 "No" ;
VAL_ 1054 SelDrvMdeChassis_D_Rq 31 "Faulty" 30 "NotUsed17" 29 "NotUsed16" 28 "NotUsed15" 27 "NotUsed14" 26 "NotUsed13" 25 "NotUsed12" 24 "NotUsed11" 23 "NotUsed10" 22 "NotUsed9" 21 "NotUsed8" 20 "NotUsed7" 19 "NotUsed6" 18 "NotUsed5" 17 "NotUsed4" 16 "NotUsed3" 15 "NotUsed2" 14 "NotUsed1" 13 "TrackMode" 12 "HighSpeedDesertMode" 11 "TowHaulMode" 10 "RockCrawlMode" 9 "SandMode" 8 "MudAndRutsMode" 7 "LowMuMode" 6 "ComfortAdaptiveMode" 5 "ComfortMode" 4 "SportAdaptiveMode" 3 "SportMode" 2 "EconomyMode" 1 "NormalAdaptiveMode" 0 "NormalMode" ;
VAL_ 1054 ApaBrk_D_Stat 3 "Denied" 2 "Active" 1 "Open" 0 "Closed" ;
VAL_ 1046 RearDiffElckrOpen_B_Rq 1 "Yes" 0 "No" ;
VAL_ 1046 HsaMde_D_Mem 3 "Undefined" 2 "Manual" 1 "Automatic" 0 "Off" ;
VAL_ 1046 BrkBstrVac_B_Rq 1 "Yes" 0 "No" ;
VAL_ 1046 HdcMde_D_Actl 7 "Fault" 6 "Temporarily_Unavailable" 5 "NotEnabled_WrongGearSel" 4 "NotEnabled_SpdLimitExceed" 3 "Active_Braking" 2 "Not_Active_Braking" 1 "Off" 0 "Undefined" ;
VAL_ 1046 RearDiffLck_Tq2_RqMx 4095 "Faulty" ;
VAL_ 1046 TRLR_SWAY_EVNT_IN_PROG 1 "Yes" 0 "No" ;
VAL_ 1046 TRLR_SWAY_CONFIG_STAT 1 "On" 0 "Off" ;
VAL_ 1046 TCMode 1 "Active" 0 "Inactive" ;
VAL_ 1046 DrvSlipCtlLamp_D_Rq 3 "Fast_Flash" 2 "Slow_Flash" 1 "On" 0 "Off" ;
VAL_ 1046 Abs_B_Falt 1 "Yes" 0 "No" ;
VAL_ 1046 DrvSlipCtlMde_D_Ind 3 "App_Specific_Off_Mode_3" 2 "App_Specific_Off_Mode_2" 1 "App_Specific_Off_Mode_1" 0 "Default_Mode" ;
VAL_ 1046 DrvAntiLckLamp_D_Rq 3 "Fast_Flash" 2 "Slow_Flash" 1 "On" 0 "Off" ;
VAL_ 1046 StabCtlBrk_B_Avail 1 "Yes" 0 "No" ;
VAL_ 1046 DrvHdcWarnInfo_D_Rq 3 "Undefined" 2 "Lamp_On_Continuously" 1 "Lamp_Flashing" 0 "Lamp_Off_Continuously" ;
VAL_ 1046 DrvHdcMsg_D_Rq 7 "Undefined" 6 "Speed_too_High" 5 "Temporarily_Unavailable" 4 "System_Fault" 3 "Select_Gear" 2 "Off" 1 "On" 0 "No_Message" ;
VAL_ 1046 DrvHdcLampInfo_D_Rq 3 "Fast_Flash" 2 "Slow_Flash" 1 "On" 0 "Off" ;
VAL_ 1046 BpedMove_D_Actl 3 "Unknown" 2 "DriverApplyingBrakePedal" 1 "NoAutonomousBrkPdlMovement" 0 "AutonomousBrkPedalMove" ;
VAL_ 1046 ChimeBrk_B_Rq 1 "Yes" 0 "No" ;
VAL_ 1046 BrkLamp_B_Rq 1 "Yes" 0 "No" ;
VAL_ 1046 HILL_DESC_MC 7 "Fault_Detected" 6 "Cooling_Down" 5 "Abort_Apply_Brakes" 4 "Active" 3 "Disabled" 2 "Enabled" 1 "Off_Road" 0 "Normal" ;
VAL_ 1045 VehStab_D_Stat 15 "Faulty" 14 "No_Data_Exists" 13 "NotUsed6" 12 "NotUsed5" 11 "NotUsed4" 10 "NotUsed3" 9 "NotUsed2" 8 "NotUsed1" 7 "High_SSRA_no_OS" 6 "Straight" 5 "Post_Oversteer" 4 "Post_Transition" 3 "Countersteer" 2 "Understeer" 1 "Oversteer" 0 "Linear" ;
VAL_ 1045 BrkFluidLvl_D_Stat 3 "Invalid" 2 "Unknown" 1 "Low" 0 "OK" ;
VAL_ 1045 LsmcBrkDecel_D_Stat 7 "NotUsed_3" 6 "NotUsed_2" 5 "NotUsed_1" 4 "Denied" 3 "FaultDegraded" 2 "FaultExt" 1 "On" 0 "Off" ;
VAL_ 1045 VehYawNonLin_W_Rq 4095 "Fault" 4094 "Unknown" ;
VAL_ 1045 VehYawLin_W_Rq 4095 "Fault" 4094 "Unknown" ;
VAL_ 1045 VehVActlBrk_D_Qf 3 "OK" 2 "Not_Within_Specifications" 1 "No_Data_Exists" 0 "Faulty" ;
VAL_ 1044 StePinOffst_An_Est 65535 "Faulty" 65534 "NoDataExists" ;
VAL_ 1044 StePinOffst_D_Stat 3 "FineOffset" 2 "CoarseOffset" 1 "StoredOffset" 0 "OffsetNotCalculated" ;
VAL_ 1042 VehRol_An_Dsply 127 "Faulty" 126 "NoDataExists" ;
VAL_ 1042 VehPtch_An_Dsply 127 "Faulty" 126 "NoDataExists" ;
VAL_ 535 WhlRr_W_Meas 32767 "Fault" 32766 "Unknown" ;
VAL_ 535 WhlRl_W_Meas 32767 "Fault" 32766 "Unknown" ;
VAL_ 535 WhlFr_W_Meas 32767 "Fault" 32766 "Unknown" ;
VAL_ 535 WhlFl_W_Meas 32767 "Fault" 32766 "Unknown" ;
VAL_ 534 WhlDirRr_D_Actl 3 "Failed" 2 "Unknown" 1 "Backward" 0 "Forward" ;
VAL_ 534 WhlDirRl_D_Actl 3 "Failed" 2 "Unknown" 1 "Backward" 0 "Forward" ;
VAL_ 534 WhlDirFr_D_Actl 3 "Failed" 2 "Unknown" 1 "Backward" 0 "Forward" ;
VAL_ 534 WhlDirFl_D_Actl 3 "Failed" 2 "Unknown" 1 "Backward" 0 "Forward" ;
VAL_ 532 RgenTqFalt_B_Actl 1 "Fault" 0 "No_Fault" ;
VAL_ 532 RgenBrkDynoMde_B_Actl 1 "TwoWheelDyno" 0 "NormalOperation" ;
VAL_ 531 VehStop_D_Stat 3 "Faulty" 2 "NoDataExists" 1 "Yes" 0 "No" ;
VAL_ 531 TracCtlPtActv_B_Actl 1 "Active" 0 "Inactive" ;
VAL_ 531 LscmbbMntr_B_Err 1 "DisplayMessage" 0 "NoMessage" ;
VAL_ 531 LscmbbBrkDis_B_Actl 1 "Yes" 0 "No" ;
VAL_ 531 LscmbbDeny_B_ActlBrk 1 "Yes" 0 "No" ;
VAL_ 531 PrkBrkYwLamp_D_Rq 3 "Fast_Flash" 2 "Slow_Flash" 1 "On" 0 "Off" ;
VAL_ 531 PrkBrkRedLamp_D_Rq 3 "Fast_Flash" 2 "Slow_Flash" 1 "On" 0 "Off" ;
VAL_ 531 VehicleStationary 1 "Yes" 0 "No" ;
VAL_ 531 LscmbbBrkDecel_B_Actl 1 "Yes" 0 "No" ;
VAL_ 531 AbsActv_B_Actl 1 "Yes" 0 "No" ;
VAL_ 531 StabCtlBrkActv_B_Actl 1 "Yes" 0 "No" ;
VAL_ 531 CmbbBrkPrchg_B_Actl 1 "Yes" 0 "No" ;
VAL_ 531 CmbbBrkDecel_B_Actl 1 "Yes" 0 "No" ;
VAL_ 531 CmbbBaSensInc_B_Actl 1 "Yes" 0 "No" ;
VAL_ 531 AccBrkWarm_B_Actl 1 "Yes" 0 "No" ;
VAL_ 531 AccBrkTotTqMn_B_Actl 1 "Yes" 0 "No" ;
VAL_ 531 AccBrkPrchgActv_B_Actl 1 "Yes" 0 "No" ;
VAL_ 531 AccBrkDis_B_Actl 1 "Yes" 0 "No" ;
VAL_ 531 AccBrkDeny_B_Actl 1 "Yes" 0 "No" ;
VAL_ 531 AccBrkActv_B_Actl 1 "Yes" 0 "No" ;
VAL_ 531 PrplDrgCtlActv_B_Actl 1 "Active" 0 "Inactive" ;
VAL_ 531 LscmbbBaSensInc_B_Actl 1 "Yes" 0 "No" ;
VAL_ 531 CmbbBrkDis_B_Actl 1 "Yes" 0 "No" ;
VAL_ 531 CmbbDeny_B_ActlBrk 1 "Yes" 0 "No" ;
VAL_ 531 CcDis_B_Cmd 1 "Yes" 0 "No" ;
VAL_ 531 VehLongOvrGnd_A_Est 1023 "Fault" 1022 "Unknown" ;
VAL_ 531 LscmbBrkPrchg_B_Actl 1 "Active" 0 "Inactive" ;
VAL_ 531 AccStopActv_B_ActlBrk 1 "Yes" 0 "No" ;
VAL_ 531 AccDis_B_ActlEpb 1 "Yes" 0 "No" ;
VAL_ 531 PrkBrkMsgTxt_D_Rq 15 "Message15" 14 "Message14" 13 "Message13" 12 "Message12" 11 "Message11" 10 "Message10" 9 "Message9" 8 "Message8" 7 "Message7" 6 "Message6" 5 "Message5" 4 "Message4" 3 "Message3" 2 "Message2" 1 "Message1" 0 "No_Message" ;
VAL_ 531 PrkBrkStatus 7 "GeneralFault_MaintenceMode" 6 "ECD_by_Brake_ECU_Active" 5 "EPB_Limphome_Active" 4 "Rear_Caliper_Open" 3 "RWU_By_EPB_Active" 2 "Rear_Caliper_Transition" 1 "Rear_Caliper_Closed" 0 "Not_Supported" ;
VAL_ 136 SteWhlBrkOffst_An_Rq 32767 "Faulty" 32766 "NoDataExists" ;
VAL_ 127 AwdLatDelta_B_Rq 1 "Active" 0 "Inactive" ;
VAL_ 125 VehRolComp_W_Actl 4094 "NoDataExists" 4095 "Fault" ;
VAL_ 125 VehVertComp_A_Actl 1022 "NoDataExists" 1023 "Fault" ;
VAL_ 125 BrkTot_Tq_RqArb 8191 "Fault" 8190 "Unknown" ;
VAL_ 125 BrkTot_Tq_Actl 8191 "Fault" 8190 "Unknown" ;
VAL_ 125 HsaStat_D_Actl 7 "Faulty" 6 "FaultyWithDriverIndication" 5 "SlowRelease" 4 "FastRelease" 3 "ActiveBrakePedalReleased" 2 "ActiveBrakePedalPressed" 1 "FindingGradient" 0 "Inactive" ;
VAL_ 119 VehTrvlDir_D_Stat 7 "Faulty" 6 "NoDataExists" 5 "NotUsed2" 4 "NotUsed1" 3 "Reverse" 2 "LikelyReverse" 1 "Forward" 0 "LikelyForward" ;
VAL_ 119 VehOverGnd_V_Est 65535 "Invalid" 65534 "Unknown" ;
VAL_ 119 VehLongComp_A_Actl 1023 "Fault" 1022 "NoDataExists" ;
VAL_ 119 VehLatComp_A_Actl 1023 "Fault" 1022 "NoDataExists" ;
VAL_ 119 VehYawComp_W_Actl 4095 "Fault" 4094 "NoDataExists" ;
VAL_ 118 BrkCtrFnd_B_Stat 1 "Yes" 0 "No" ;
VAL_ 118 DrvSte_D_Stat 15 "NotUsed10" 14 "NotUsed9" 13 "NotUsed8" 12 "NotUsed7" 11 "NotUsed6" 10 "NotUsed5" 9 "NotUsed4" 8 "NotUsed3" 7 "NotUsed2" 6 "NotUsed1" 5 "Request_Active" 4 "Ignition_Off" 3 "DSR_in_Normal_Idle_Mode" 2 "EPAS_Comm_Disturbed" 1 "DSR_Request_Not_Applicable" 0 "DSR_Deactivated" ;
VAL_ 118 DrvSte_Tq_Rq 255 "Invalid" 254 "Unknown" ;
VAL_ 118 EmgcyBrkLamp_D_Rq 3 "NotUsed" 2 "Active_at_standstill" 1 "Active_at_speed" 0 "Inactive" ;
VAL_ 118 StopLamp_B_RqBrk 1 "Active" 0 "Inactive" ;
VAL_ 118 SteWhlCompAnEst_D_Qf 3 "OK" 2 "Not_Within_Specifications" 1 "No_Data_Exists" 0 "Faulty" ;
VAL_ 73 immoSubTarget1Cmd_T1 7 "Unused3" 6 "Unused2" 5 "ECHO_TARGET1_IDBLOCK2" 4 "Unused1" 3 "RQST_TARGET1_IDBLOCK2" 2 "RQST_TARGET1_IDBLOCK1" 1 "RESPONSE" 0 "IDLE" ;
VAL_ 561 TrnMsgTxt2_D_Rq 7 "NotUsed3" 6 "NotUsed2" 5 "NotUsed1" 4 "TransTooHot_LoudChime" 3 "PressBrake_LoudChime" 2 "PressBrake_SoftChime" 1 "PressBrake_NoChime" 0 "NoText_NoChime" ;
VAL_ 561 TrnMsgTxt_D_Rq 15 "Message_15" 14 "Message_14" 13 "Message_13" 12 "Message_12" 11 "Message_11" 10 "Message_10" 9 "Message_9" 8 "Message_8" 7 "Message_7" 6 "Message_6" 5 "Message_5" 4 "Message_4" 3 "Message_3" 2 "Message_2" 1 "Message_1" 0 "NoMessage" ;
VAL_ 330 TrnAout_W_ActlUnfilt 32767 "Fault" 32766 "Unknown" ;
VAL_ 869 FuelMaintMde_D_Dsply 3 "Feature_Not_Present" 2 "In_Fuel_Maint_Mode" 1 "Close_to_Fuel_Maint" 0 "OK" ;
VAL_ 869 PwrFlowTxt_D_Dsply 15 "NotUsed7" 14 "NotUsed6" 13 "NotUsed5" 12 "NotUsed4" 11 "NotUsed3" 10 "NotUsed2" 9 "NotUsed1" 8 "Disp_Charge_Cmplt_Txt" 7 "Disp_Remote_Start_Txt" 6 "Disp_Eng_Drv_Txt" 5 "Disp_Elec_Drv_Txt" 4 "Disp_Idle_with_Chrg_Txt" 3 "Disp_Idle_Txt" 2 "Disp_Charg_HV_Batt_Txt" 1 "Disp_Hyb_Drive_Txt" 0 "No_Text" ;
VAL_ 869 EngOnMsg2_D_Dsply 12 "Battery_Temperature" 11 "Hill_Decent_Control" 10 "Fuel_Maintenance" 9 "Oil_Maintenance" 8 "Normal_Operation" 7 "Low_Gear" 6 "Batt_Charging" 5 "Engine_Cold" 4 "Neutral_Gear" 3 "Heater_Setting" 2 "High_Speed" 1 "Acceleration" 0 "No_Display" 13 "Not_Used_States_0xD_0x1F" ;
VAL_ 869 EngOnMsg1_D_Dsply 12 "Battery_Temperature" 11 "Hill_Decent_Control" 10 "Fuel_Maintenance" 9 "Oil_Maintenance" 8 "Normal_Operation" 7 "Low_Gear" 6 "Batt_Charging" 5 "Engine_Cold" 4 "Neutral_Gear" 3 "Heater_Setting" 2 "High_Speed" 1 "Acceleration" 0 "No_Display" 13 "Not_Used_States_0xD_0x1F" ;
VAL_ 869 EngActv_B_Dsply 1 "On" 0 "Off" ;
VAL_ 869 EffWhlThresOn_B_Dsply 1 "On" 0 "Off" ;
VAL_ 606 ElVehLaterMde_D_Stat 3 "NotUsed" 2 "Available" 1 "NotAvailable" 0 "Null" ;
VAL_ 606 ElVehNowMde_D_Stat 3 "NotUsed" 2 "Available" 1 "NotAvailable" 0 "Null" ;
VAL_ 374 GearEngag_D_Actl 7 "Undefined" 6 "Fwd_Clutch_Fully_Engaged" 5 "Neutral_Idle" 4 "Disengaged_to_Neutral_Idle" 3 "Disengaged_to_Neutral_Park" 2 "Engagement_in_Progress" 1 "InitializeFwdClutchEngagmt" 0 "Park_Neutral" ;
VAL_ 374 TrnRng_D_Rq 15 "Fault" 14 "Unknown_Position" 13 "NotUsed_2" 12 "NotUsed_1" 11 "Range6" 10 "Range5" 9 "Range4" 8 "Range3_M3_L3" 7 "Range2_M2_L2" 6 "Range1_M1_L1" 5 "Low" 4 "Sport_DriveSport_Mposition" 3 "Drive" 2 "Neutral" 1 "Reverse" 0 "Park" ;
VAL_ 374 TrnPrkSys_D_Actl 15 "Faulty" 14 "NotUsed_5" 13 "NotUsed_4" 12 "NotUsed_3" 11 "NotUsed_2" 10 "NotUsed_1" 9 "FrequencyError" 8 "OutOfRangeHigh" 7 "OutOfRangeLow" 6 "Override" 5 "OutOfPark" 4 "TransitionCloseToOutOfPark" 3 "AtNoSpring" 2 "TransitionCloseToPark" 1 "Park" 0 "NotKnown" ;
VAL_ 374 GearLvr_D_ActlDrv 15 "Fault" 14 "Unknown_Position" 13 "NotUsed_2" 12 "NotUsed_1" 11 "Range6" 10 "Range5" 9 "Range4" 8 "Range3_M3_L3" 7 "Range2_M2_L2" 6 "Range1_M1_L1" 5 "Low" 4 "Sport_DriveSport_Mposition" 3 "Drive" 2 "Neutral" 1 "Reverse" 0 "Park" ;
VAL_ 374 GearPos_D_Trg 15 "Unknown" 14 "Reverse" 13 "Undefined_5" 12 "Undefined_4" 11 "Undefined_3" 10 "Tenth" 9 "Ninth" 8 "Eighth" 7 "Seventh" 6 "Sixth" 5 "Fifth" 4 "Fourth" 3 "Third" 2 "Second" 1 "First" 0 "Neutral" ;
VAL_ 374 GearPos_D_Actl 15 "Unknown" 14 "Reverse" 13 "Undefined_5" 12 "Undefined_4" 11 "Undefined_3" 10 "Tenth" 9 "Ninth" 8 "Eighth" 7 "Seventh" 6 "Sixth" 5 "Fifth" 4 "Fourth" 3 "Third" 2 "Second" 1 "First" 0 "Neutral" ;
VAL_ 603 WhlDirAvgDrv_D_Actl 3 "Failed" 2 "Unknown" 1 "Backward" 0 "Forward" ;
VAL_ 603 PrplTqMnRgen_B_Actl 1 "Yes" 0 "No" ;
VAL_ 603 BattTracCnnct_D_Rq 3 "Undefined" 2 "Retain" 1 "Close" 0 "Open" ;
VAL_ 602 HtrnWarnLamp_B_Dsply 1 "On" 0 "Off" ;
VAL_ 602 HybPwLimOn_B_Stat 1 "Yes" 0 "No" ;
VAL_ 602 PwPckTqRdy_B_Dsply 1 "On" 0 "Off" ;
VAL_ 1152 GrdAsstActv_B_Stat 1 "On" 0 "Off" ;
VAL_ 1152 EngTeHi_B_Actl 1 "EngineTempHigh" 0 "Normal" ;
VAL_ 1152 DcdcOn_B_Rq 1 "On" 0 "Off" ;
VAL_ 1152 ULoBattSpprtSustn_B_Rq 1 "Active" 0 "Inactive" ;
VAL_ 1152 VehElEff_No_Avg 127 "Faulty" 126 "NoDataExists" ;
VAL_ 560 SelDrvMdeSwtch_D_Stat3 3 "Faulty" 2 "SwitchState2" 1 "SwitchState1" 0 "NotPressed" ;
VAL_ 560 TrnSrvcRqd_B_Rq 1 "On" 0 "Off" ;
VAL_ 560 TrnShifActv_B_Actl 1 "Active" 0 "Inactive" ;
VAL_ 560 GearLvrPos_D_Actl 15 "Fault" 14 "Unknown_Position" 13 "Undefined_Treat_as__Fault" 12 "Undefined_Treat_as_Fault" 11 "sixth" 10 "fifth" 9 "fourth" 8 "third" 7 "second" 6 "first" 5 "Low" 4 "Sport_DriveSport" 3 "Drive" 2 "Neutral" 1 "Reverse" 0 "Park" ;
VAL_ 560 GboxOil_Te_Actl 255 "Faulty" 254 "NoDataExists" ;
VAL_ 369 TrnIpcDsplyRng2_D_Actl 15 "No_Range_Selected" 14 "Range_14" 13 "Range_13" 12 "Range_12" 11 "Range_11" 10 "Range_10" 9 "Range_9" 8 "Range_8" 7 "Range_7" 6 "Range_6" 5 "Range_5" 4 "Range_4" 3 "Range_3" 2 "Range_2" 1 "Range_1" 0 "NotUsed" ;
VAL_ 369 TrnIpcDsplyRng_D_Stat 3 "NotUsed" 2 "Flash" 1 "On" 0 "Blank_No_Display" ;
VAL_ 369 TrnIpcDsplyGear_D_Actl 15 "No_Gear_Selected" 14 "_14th_Gear" 13 "_13th_Gear" 12 "_12th_Gear" 11 "_11th_Gear" 10 "_10th_Gear" 9 "_9th_Gear" 8 "_8th_Gear" 7 "_7th_Gear" 6 "_6th_Gear" 5 "_5th_Gear" 4 "_4th_Gear" 3 "_3rd_Gear" 2 "_2nd_Gear" 1 "_1st_Gear" 0 "Neutral" ;
VAL_ 369 TrnIpcDsplyMde_D_Stat 3 "Reserved_Blank_No_Display" 2 "Flash" 1 "On" 0 "Blank_No_Display" ;
VAL_ 369 TrnIpcDsplyMde_D_Actl 7 "Manual_3" 6 "Manual_2" 5 "Manual_1_Low" 4 "Sport" 3 "Drive" 2 "Neutral" 1 "Reverse" 0 "Park" ;
VAL_ 369 TrnIpcDsplyGear_D_Stat 3 "Reserved_Blank_No_Display" 2 "Flash" 1 "On" 0 "Blank_No_Display" ;
VAL_ 92 TrnLvrV_D_Rq 3 "Full_Speed" 2 "Aggressive" 1 "Normal" 0 "Quiet" ;
VAL_ 92 TrnSbwSysHlth_D_Actl 3 "OK" 2 "Degraded" 1 "No_Data_Exists" 0 "Faulty" ;
VAL_ 92 TrnGearNtmAllow_B_Stat 1 "Yes" 0 "No" ;
VAL_ 92 TrnDtpCmd_D_Actl 7 "NotUsed4" 6 "NotUsed3" 5 "NotUsed2" 4 "Relatch" 3 "Deploy" 2 "Self_Test" 1 "No_Command" 0 "NotUsed1" ;
VAL_ 92 GearSelLck_D_Rq 3 "PreventionBlocker" 2 "Unlock" 1 "Lock" 0 "Null" ;
VAL_ 92 TrnValidGear_D_Cnfm 3 "Accept" 2 "Reject" 1 "Internal_Request" 0 "No_Command" ;
VAL_ 92 TrnNtrlTowCmd_D_Actl 3 "NotUsed" 2 "Neutral_Tow_Entry" 1 "Car_Wash_Mode" 0 "Normal_Mode" ;
VAL_ 92 TrnGearCmd_Pc_ActlPt 1023 "Fault" ;
VAL_ 92 TrnGear_D_RqPt 7 "Fault" 6 "NotUsed" 5 "Manual" 4 "Drive" 3 "Neutral" 2 "Reverse" 1 "Park" 0 "No_Gear" ;
VAL_ 92 TrnCmdState_B_Actl 1 "Yes" 0 "No" ;
VAL_ 92 PrkBrkActv_D_RqTrnGear 3 "NotUsed2" 2 "RequestParkBrakeEngage" 1 "NoRequest" 0 "NotUsed1" ;
VAL_ 92 TrnGearMsgTxt_D_Rq 15 "Message_15" 14 "Message_14" 13 "Message_13" 12 "Message_12" 11 "Message_11" 10 "Message_10" 9 "Message_9" 8 "Message_8" 7 "Message_7" 6 "Message_6" 5 "Message_5" 4 "Message_4" 3 "Message_3" 2 "Message_2" 1 "Message_1" 0 "NoMessage" ;
VAL_ 1087 FapLcInhbt_B_Rq 1 "Yes" 0 "No" ;
VAL_ 1087 FapLcStopHold_B_Rq 1 "Yes" 0 "No" ;
VAL_ 1087 FapLcPrchgBrk_B_Rq 1 "Yes" 0 "No" ;
VAL_ 1087 FapLcObstcl_B_Stat 1 "Yes" 0 "No" ;
VAL_ 1087 FapLcMaxGrdInhbt_B_Stat 1 "Yes" 0 "No" ;
VAL_ 1087 FapLcMaxGrdAbrt_B_Stat 1 "Yes" 0 "No" ;
VAL_ 1087 FapLcActv_B_Stat 1 "Yes" 0 "No" ;
VAL_ 332 UreaQltySysWarn_D_Rq 7 "Undefined" 6 "ZZ_Overrides" 5 "EngineIdled" 4 "Engine_Idle_Upon_Refuel" 3 "SPEED_LIMITED_to_YY_mph" 2 "YY_MPH_MAX_UPON_Restart" 1 "CONTAMINATED_ExhFluid" 0 "NoQualityProblem" ;
VAL_ 332 UreaLvlTxtWarn_D_Rq 15 "NotUsed_4" 14 "NotUsed_3" 13 "NotUsed_2" 12 "NotUsed_1" 11 "System_Error" 10 "Engine_Idled_See_Manual" 9 "Engine_Idled_Upon_Refuel" 8 "Speed_Limited_To_YY_mph" 7 "YYmph_Max_Upon_Restart" 6 "Speed_Limited_To_YY_mph" 5 "YYmph_Max_Upon_Restart" 4 "SpdLimtd_YYmph_In_XXmiles" 3 "ExFlRange_XXMiles_ScndWarn" 2 "Exh_Fluid_Range_XX_Miles" 1 "Exh_Fluid_Under_Half_Full" 0 "Exh_Fluid_Over_Half_Full" ;
VAL_ 332 UreaLvlQlty_D_RqDsply 7 "NotUsed_5" 6 "NotUsed_4" 5 "NotUsed_3" 4 "NotUsed_2" 3 "NotUsed_1" 2 "FlashChime" 1 "On" 0 "Off" ;
VAL_ 332 DieslPrtcWarn_D_Rq 15 "NotUsed_4" 14 "NotUsed_3" 13 "NotUsed_2" 12 "NotUsed_1" 11 "OCR_ExhFilterClean_Stopped" 10 "OCR_ExhFilterCleaned" 9 "RgnOff_AtLimit" 8 "RgnOff_OverLoaded" 7 "RgnOff_Loaded" 6 "Exhaust_Filter_Full" 5 "DPF_OverLimit" 4 "DPF_AtLimit" 3 "ExhFilter_Drive_Completed" 2 "Cleaning_Exhaust_Filter" 1 "DPF_OverLoaded" 0 "DPF_Normal_Operation" ;
VAL_ 332 UreaQltyFlg_B_RqDsply 1 "True" 0 "False" ;
VAL_ 332 UreaQltySys_D_RqDsply 7 "Undefined" 6 "ZZ_Overrides" 5 "EngineIdled" 4 "Engine_Idle_Upon_Refuel" 3 "SPEED_LIMITED_to_YY_mph" 2 "YY_MPH_MAX_UPON_Restart" 1 "CONTAMINATED_ExhFluid" 0 "NoQualityProblem" ;
VAL_ 332 UreaLvlTxt_D_RqDsply 15 "NotUsed_4" 14 "NotUsed_3" 13 "NotUsed_2" 12 "NotUsed_1" 11 "System_Error" 10 "Engine_Idled_See_Manual" 9 "Engine_Idled_Upon_Refuel" 8 "Speed_Limited_To_YY_mph" 7 "YYmph_Max_Upon_Restart" 6 "Speed_Limited_To_YY_mph" 5 "YYmph_Max_Upon_Restart" 4 "SpdLimtd_YYmph_In_XXmiles" 3 "ExFlRange_XXMiles_ScndWarn" 2 "Exh_Fluid_Range_XX_Miles" 1 "Exh_Fluid_Under_Half_Full" 0 "Exh_Fluid_Over_Half_Full" ;
